VERSION "V6.0.0"

NS_ :

BS_:

BU_: OBD_Node CGW_PT POD BMS TCU APTC VCU MCU PRND EVCOM IBS_PT ADCU_PT

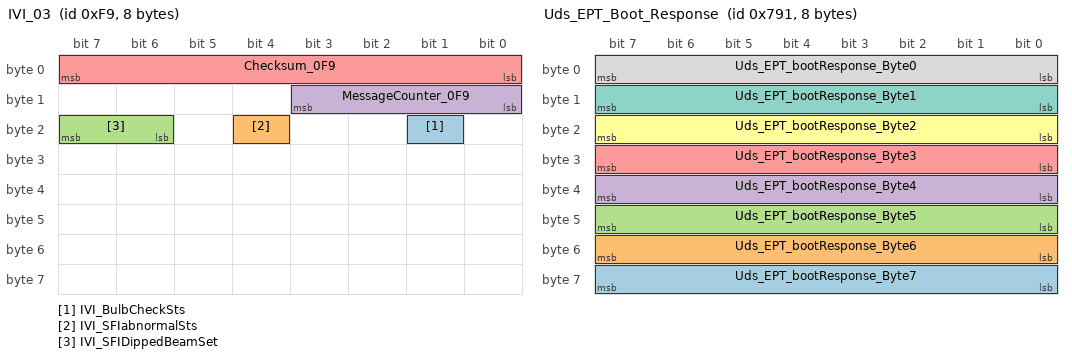
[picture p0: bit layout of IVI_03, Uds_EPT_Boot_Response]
BO_ 249 IVI_03: 8 CGW_PT
 SG_ IVI_BulbCheckSts : 17|1@0+ (1,0) [0|1] ""  VCU
 SG_ IVI_SFIabnormalSts : 20|1@0+ (1,0) [0|1] ""  VCU
 SG_ IVI_SFIDippedBeamSet : 23|2@0+ (1,0) [0|3] ""  VCU
 SG_ MessageCounter_0F9 : 11|4@0+ (1,0) [0|15] ""  VCU
 SG_ Checksum_0F9 : 7|8@0+ (1,0) [0|255] ""  VCU

BO_ 1937 Uds_EPT_Boot_Response: 8 VCU
 SG_ Uds_EPT_bootResponse_Byte7 : 56|8@1+ (1,0) [0|0] ""  CGW_PT
 SG_ Uds_EPT_bootResponse_Byte6 : 48|8@1+ (1,0) [0|0] ""  CGW_PT
 SG_ Uds_EPT_bootResponse_Byte5 : 40|8@1+ (1,0) [0|0] ""  CGW_PT
 SG_ Uds_EPT_bootResponse_Byte4 : 32|8@1+ (1,0) [0|0] ""  CGW_PT
 SG_ Uds_EPT_bootResponse_Byte3 : 24|8@1+ (1,0) [0|0] ""  CGW_PT
 SG_ Uds_EPT_bootResponse_Byte2 : 16|8@1+ (1,0) [0|0] ""  CGW_PT
 SG_ Uds_EPT_bootResponse_Byte1 : 8|8@1+ (1,0) [0|0] ""  CGW_PT
 SG_ Uds_EPT_bootResponse_Byte0 : 0|8@1+ (1,0) [0|0] ""  CGW_PT

BO_ 1809 Uds_EPT_Boot_Request: 8 CGW_PT
 SG_ UDS_EPT_BootCmd3 : 16|8@1+ (1,0) [0|0] ""  VCU
 SG_ UDS_EPT_BootCmd2 : 8|8@1+ (1,0) [0|0] ""  VCU
 SG_ UDS_EPT_BootCmd1 : 0|8@1+ (1,0) [0|0] ""  VCU

BO_ 151 ACU_info: 8 CGW_PT
 SG_ Checksum_097 : 7|8@0+ (1,0) [0|255] ""  MCU,BMS
 SG_ MessageCounter_097 : 11|4@0+ (1,0) [0|15] ""  MCU,BMS
 SG_ ACU_CrashOutputSts : 23|5@0+ (1,0) [0|31] ""  MCU,BMS
 SG_ ACU_CrashOutputStsValid : 16|1@0+ (1,0) [0|1] ""  MCU,BMS
 SG_ ACU_DriverSeatBeltSts : 31|1@0+ (1,0) [0|1] "" Vector__XXX
 SG_ ACU_DriverSeatBeltStsValid : 30|1@0+ (1,0) [0|1] "" Vector__XXX
 SG_ ACU_PassengerSeatBeltSts : 27|1@0+ (1,0) [0|1] "" Vector__XXX
 SG_ ACU_PassengerSeatBeltStsValid : 26|1@0+ (1,0) [0|1] "" Vector__XXX
 SG_ ACU_PassengerSts : 25|1@0+ (1,0) [0|1] "" Vector__XXX
 SG_ ACU_SecondLeftSeatBeltSts : 39|1@0+ (1,0) [0|1] "" Vector__XXX
 SG_ ACU_RLSeatBeltStatusValid : 38|1@0+ (1,0) [0|1] "" Vector__XXX
 SG_ ACU_SecondLeftSts : 37|1@0+ (1,0) [0|1] "" Vector__XXX
 SG_ ACU_SecondRightSeatBeltSts : 55|1@0+ (1,0) [0|1] "" Vector__XXX
 SG_ ACU_RRSeatBeltStatusValid : 54|1@0+ (1,0) [0|1] "" Vector__XXX
 SG_ ACU_SecondRightSts : 53|1@0+ (1,0) [0|1] "" Vector__XXX
 SG_ ACU_PassengerAirbagSts : 63|2@0+ (1,0) [0|3] "" Vector__XXX
 SG_ ACU_DriverWarningLampSts : 61|2@0+ (1,0) [0|2] "" Vector__XXX
 SG_ ACU_PassengerWarningLampSts : 59|2@0+ (1,0) [0|2] "" Vector__XXX
 SG_ ACU_WarningLampSts : 57|2@0+ (1,0) [0|2] "" Vector__XXX

BO_ 918 ADCU_temperature: 8 ADCU_PT
 SG_ ADCU_TemperatureSts : 23|2@0+ (1,0) [0|3] "" Vector__XXX

BO_ 613 APTC_TCU: 8 APTC
 SG_ APTC_HVPowerUpReq : 7|1@0+ (1,0) [0|1] ""  TCU,CGW_PT
 SG_ APTC_HeatingFaltStatus : 6|1@0+ (1,0) [0|1] ""  TCU,CGW_PT
 SG_ APTC_DriveFaltStatus : 5|1@0+ (1,0) [0|1] ""  TCU,CGW_PT
 SG_ APTC_LostCommuFaltStatus : 4|1@0+ (1,0) [0|1] ""  TCU,CGW_PT
 SG_ APTC_IGBTFaltStatus : 3|2@0+ (1,0) [0|3] ""  TCU,CGW_PT
 SG_ APTC_Core1TempSensorFaltStatus : 1|2@0+ (1,0) [0|3] ""  TCU,CGW_PT
 SG_ APTC_LeftCoreTemp : 15|8@0+ (1,-40) [-40|215] "degrees"  TCU,CGW_PT
 SG_ APTC_RightCoreTemp : 23|8@0+ (1,-40) [-40|215] "degrees"  TCU,CGW_PT
 SG_ APTC_PowerConsumption : 31|8@0+ (0.04,0) [0|10.2] "KW"  TCU,VCU,CGW_PT
 SG_ APTC_HVBusVoltage : 39|11@0+ (0.5,0) [0|1020] "V"  TCU,CGW_PT
 SG_ APTC_OverCurrentFault : 52|1@0+ (1,0) [0|1] ""  TCU,CGW_PT
 SG_ APTC_LowVoltageStatus : 51|2@0+ (1,0) [0|3] ""  TCU,CGW_PT
 SG_ APTC_HighVoltageStatus : 49|2@0+ (1,0) [0|3] ""  TCU,CGW_PT
 SG_ APTC_OverLoadStatus : 63|2@0+ (1,0) [0|3] ""  TCU,CGW_PT
 SG_ APTC_IGBTTempSensorStatus : 61|2@0+ (1,0) [0|3] ""  TCU,CGW_PT
 SG_ APTC_PCBTempSensorStatus : 59|2@0+ (1,0) [0|3] ""  TCU,CGW_PT
 SG_ APTC_Core2TempSensorFaltStatus : 57|2@0+ (1,0) [0|3] ""  TCU,CGW_PT

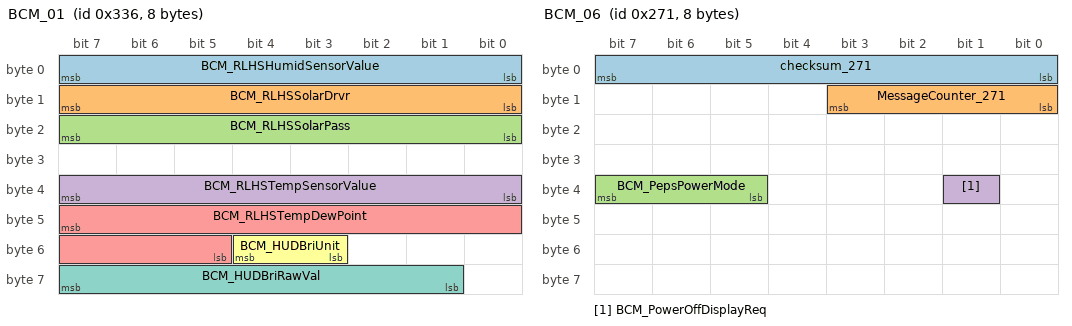
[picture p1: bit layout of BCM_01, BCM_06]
BO_ 822 BCM_01: 8 CGW_PT
 SG_ BCM_RLHSHumidSensorValue : 7|8@0+ (0.5,-0.5) [0|100] "percent"  TCU
 SG_ BCM_RLHSSolarDrvr : 15|8@0+ (4,0) [0|1000] "W/m^2"  TCU
 SG_ BCM_RLHSSolarPass : 23|8@0+ (4,0) [0|1000] "W/m^2"  TCU
 SG_ BCM_RLHSTempSensorValue : 39|8@0+ (0.5,-40) [-39.5|87] "celsius"  TCU
 SG_ BCM_RLHSTempDewPoint : 47|11@0+ (0.1,-39.6) [-39.5|60.4] "celsius"  TCU
 SG_ BCM_HUDBriUnit : 52|2@0+ (1,0) [0|3] "" Vector__XXX
 SG_ BCM_HUDBriRawVal : 63|7@0+ (1,0) [0|126] "" Vector__XXX

BO_ 826 BCM_05: 8 CGW_PT
 SG_ Checksum_33A : 7|8@0+ (1,0) [0|255] ""  VCU
 SG_ MessageCounter_33A : 11|4@0+ (1,0) [0|15] ""  VCU
 SG_ BCM_GearTimesSts : 15|3@0+ (1,0) [0|5] ""  VCU
 SG_ BCM_ChrgFlapLockSts : 12|1@0+ (1,0) [0|1] ""  VCU
 SG_ BCM_FRSeatBeltRemindReq : 17|2@0+ (1,0) [0|3] ""  VCU
 SG_ BCM_FLSeatBeltRemindReq : 19|2@0+ (1,0) [0|3] ""  VCU
 SG_ BCM_KeyNotInCarRemind : 20|1@0+ (1,0) [0|1] ""  VCU
 SG_ BCM_RRSeatBeltRemindReq : 29|2@0+ (1,0) [0|3] ""  VCU
 SG_ BCM_RLSeatBeltRemindReq : 31|2@0+ (1,0) [0|3] ""  VCU
 SG_ BCM_WiperServiceSts : 33|2@0+ (1,0) [0|1] ""  VCU
 SG_ BCM_AutoCloseWinFunSts : 36|1@0+ (1,0) [0|1] ""  VCU
 SG_ BCM_DomeLampBrightSts : 37|1@0+ (1,0) [0|1] ""  VCU
 SG_ BCM_PuddleLiReq : 39|2@0+ (1,0) [0|2] ""  VCU
 SG_ BCM_DomeLampAutoSts : 41|2@0+ (1,0) [0|2] ""  VCU
 SG_ BCM_FrontWiperModeSts : 44|3@0+ (1,0) [0|5] ""  VCU
 SG_ BCM_WiperWorkingSts : 47|3@0+ (1,0) [0|2] ""  VCU
 SG_ BCM_WelLightshowOnOffSts : 51|2@0+ (1,0) [0|2] ""  VCU

BO_ 625 BCM_06: 8 CGW_PT
 SG_ checksum_271 : 7|8@0+ (1,0) [0|255] ""  VCU
 SG_ MessageCounter_271 : 11|4@0+ (1,0) [0|15] ""  VCU
 SG_ BCM_PepsPowerMode : 39|3@0+ (1,0) [0|7] ""  VCU
 SG_ BCM_PowerOffDisplayReq : 33|1@0+ (1,0) [0|1] ""  VCU

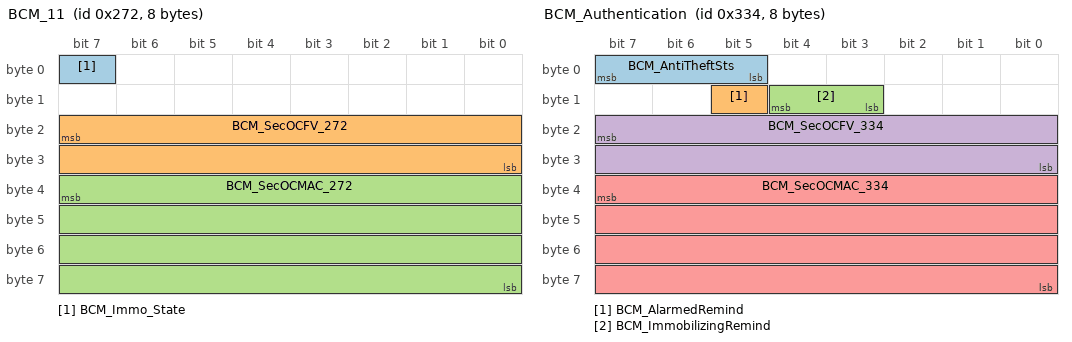
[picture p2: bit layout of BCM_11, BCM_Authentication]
BO_ 626 BCM_11: 8 CGW_PT
 SG_ BCM_Immo_State : 7|1@0+ (1,0) [0|1] ""  VCU
 SG_ BCM_SecOCFV_272 : 23|16@0+ (1,0) [0|65535] ""  VCU
 SG_ BCM_SecOCMAC_272 : 39|32@0+ (1,0) [0|4294967295] ""  VCU

BO_ 820 BCM_Authentication: 8 CGW_PT
 SG_ BCM_AntiTheftSts : 7|3@0+ (1,0) [0|3] ""  VCU
 SG_ BCM_AlarmedRemind : 13|1@0+ (1,0) [0|1] "" Vector__XXX
 SG_ BCM_ImmobilizingRemind : 12|2@0+ (1,0) [0|3] "" Vector__XXX
 SG_ BCM_SecOCFV_334 : 23|16@0+ (1,0) [0|65535] ""  VCU
 SG_ BCM_SecOCMAC_334 : 39|32@0+ (1,0) [0|4294967295] ""  VCU

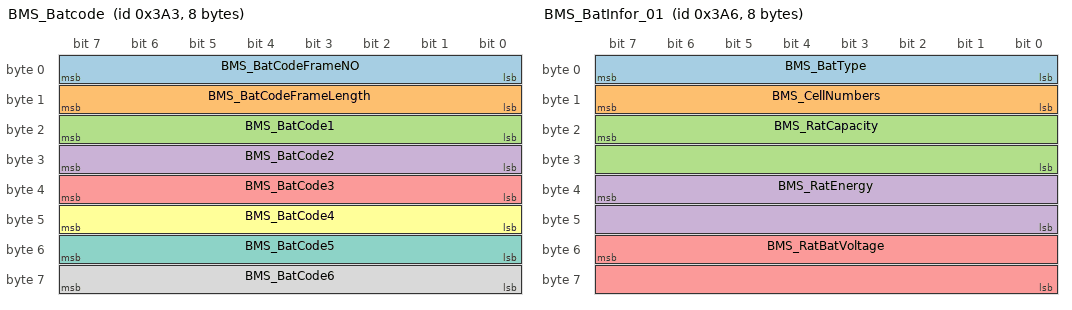
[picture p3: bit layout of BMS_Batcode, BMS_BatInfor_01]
BO_ 931 BMS_Batcode: 8 BMS
 SG_ BMS_BatCodeFrameNO : 7|8@0+ (1,0) [0|255] "" Vector__XXX
 SG_ BMS_BatCodeFrameLength : 15|8@0+ (1,0) [0|255] "" Vector__XXX
 SG_ BMS_BatCode1 : 23|8@0+ (1,0) [0|255] "" Vector__XXX
 SG_ BMS_BatCode2 : 31|8@0+ (1,0) [0|255] "" Vector__XXX
 SG_ BMS_BatCode3 : 39|8@0+ (1,0) [0|255] "" Vector__XXX
 SG_ BMS_BatCode4 : 47|8@0+ (1,0) [0|255] "" Vector__XXX
 SG_ BMS_BatCode5 : 55|8@0+ (1,0) [0|255] "" Vector__XXX
 SG_ BMS_BatCode6 : 63|8@0+ (1,0) [0|255] "" Vector__XXX

BO_ 934 BMS_BatInfor_01: 8 BMS
 SG_ BMS_BatType : 7|8@0+ (1,0) [0|255] ""  VCU,CGW_PT
 SG_ BMS_CellNumbers : 15|8@0+ (1,0) [0|255] ""  VCU,CGW_PT
 SG_ BMS_RatCapacity : 23|16@0+ (0.1,0) [0|6553.5] "Ah"  VCU,CGW_PT
 SG_ BMS_RatEnergy : 39|16@0+ (0.1,0) [0|6553.5] "KWH"  VCU,CGW_PT
 SG_ BMS_RatBatVoltage : 55|16@0+ (0.1,0) [0|6553.5] "V"  VCU,CGW_PT

BO_ 935 BMS_BatInfor_02: 8 BMS
 SG_ BMS_BatSupName : 7|64@0+ (1,0) [0|4294967295] ""  VCU

BO_ 938 BMS_BatInfor_03: 8 BMS
 SG_ BMS_RemainCapacity : 23|16@0+ (0.1,0) [0|6553.5] "Ah"  VCU

BO_ 993 BMS_Cellinfo: 8 BMS
 SG_ BMS_Cellinfo : 7|64@0+ (0.01,0) [0|655.35] "" Vector__XXX

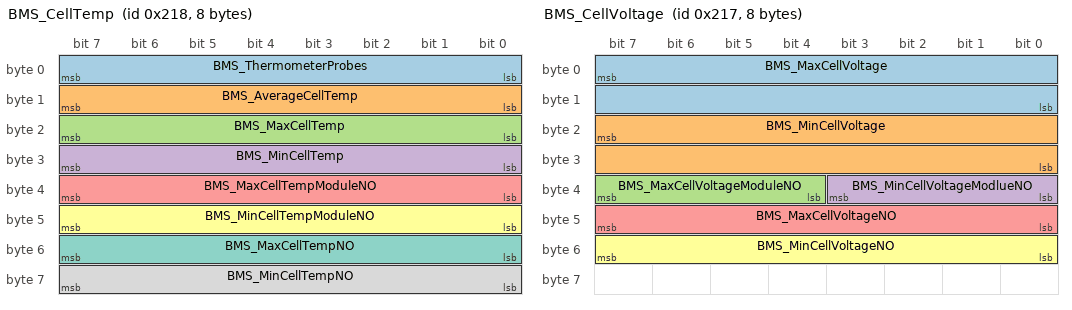
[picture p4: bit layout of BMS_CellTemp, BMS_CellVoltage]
BO_ 536 BMS_CellTemp: 8 BMS
 SG_ BMS_ThermometerProbes : 7|8@0+ (1,0) [0|255] ""  CGW_PT
 SG_ BMS_AverageCellTemp : 15|8@0+ (1,-40) [-40|215] "celsius"  TCU,VCU,CGW_PT
 SG_ BMS_MaxCellTemp : 23|8@0+ (1,-40) [-40|215] "celsius"  TCU,VCU,CGW_PT
 SG_ BMS_MinCellTemp : 31|8@0+ (1,-40) [-40|215] "celsius"  TCU,VCU,CGW_PT
 SG_ BMS_MaxCellTempModuleNO : 39|8@0+ (1,0) [0|255] ""  CGW_PT
 SG_ BMS_MinCellTempModuleNO : 47|8@0+ (1,0) [0|255] ""  VCU,CGW_PT
 SG_ BMS_MaxCellTempNO : 55|8@0+ (1,0) [0|255] ""  VCU,CGW_PT
 SG_ BMS_MinCellTempNO : 63|8@0+ (1,0) [0|255] ""  VCU,CGW_PT

BO_ 535 BMS_CellVoltage: 8 BMS
 SG_ BMS_MaxCellVoltage : 7|16@0+ (0.001,0) [0|65.535] "V"  VCU,CGW_PT
 SG_ BMS_MinCellVoltage : 23|16@0+ (0.001,0) [0|65.535] "V"  VCU,CGW_PT
 SG_ BMS_MaxCellVoltageModuleNO : 39|4@0+ (1,0) [0|15] ""  VCU,CGW_PT
 SG_ BMS_MinCellVoltageModlueNO : 35|4@0+ (1,0) [0|15] ""  CGW_PT
 SG_ BMS_MaxCellVoltageNO : 47|8@0+ (1,0) [0|255] ""  VCU,CGW_PT
 SG_ BMS_MinCellVoltageNO : 55|8@0+ (1,0) [0|255] ""  CGW_PT

BO_ 530 BMS_Charge_01: 8 BMS
 SG_ BMS_RemChagTime : 7|16@0+ (1,0) [0|3600] "min"  VCU,CGW_PT
 SG_ BMS_MaxChagVoltage : 23|16@0+ (0.1,0) [0|6553.5] "V"  VCU,CGW_PT,POD
 SG_ BMS_AllowChagCurrent : 39|16@0+ (0.1,-1000) [-1000|1000] "A"  VCU,CGW_PT

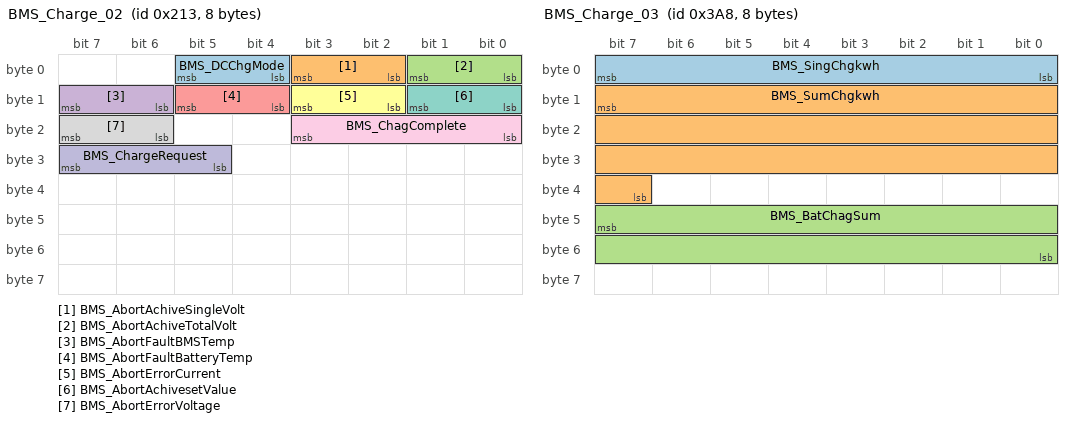
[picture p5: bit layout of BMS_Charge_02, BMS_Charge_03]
BO_ 531 BMS_Charge_02: 8 BMS
 SG_ BMS_DCChgMode : 5|2@0+ (1,0) [0|2] ""  VCU,CGW_PT
 SG_ BMS_AbortAchiveSingleVolt : 3|2@0+ (1,0) [0|2] ""  VCU,CGW_PT
 SG_ BMS_AbortAchiveTotalVolt : 1|2@0+ (1,0) [0|2] ""  VCU,CGW_PT
 SG_ BMS_AbortFaultBMSTemp : 15|2@0+ (1,0) [0|2] ""  VCU,CGW_PT
 SG_ BMS_AbortFaultBatteryTemp : 13|2@0+ (1,0) [0|2] ""  VCU,CGW_PT
 SG_ BMS_AbortErrorCurrent : 11|2@0+ (1,0) [0|2] ""  VCU,CGW_PT
 SG_ BMS_AbortAchivesetValue : 9|2@0+ (1,0) [0|2] ""  VCU,CGW_PT
 SG_ BMS_AbortErrorVoltage : 23|2@0+ (1,0) [0|2] ""  VCU,CGW_PT
 SG_ BMS_ChagComplete : 19|4@0+ (1,0) [0|3] ""  VCU,CGW_PT,POD
 SG_ BMS_ChargeRequest : 31|3@0+ (1,0) [0|4] ""  VCU,CGW_PT,POD

BO_ 936 BMS_Charge_03: 8 BMS
 SG_ BMS_SingChgkwh : 7|8@0+ (1,0) [0|255] "KWH"  VCU
 SG_ BMS_SumChgkwh : 15|25@0+ (1,0) [0|16777216] "KWH"  VCU
 SG_ BMS_BatChagSum : 47|16@0+ (1,0) [0|3000] ""  VCU

BO_ 937 BMS_Charge_04: 8 BMS
 SG_ BMS_SumDisChgkwh : 7|25@0+ (1,0) [0|16777216] "KWH" Vector__XXX

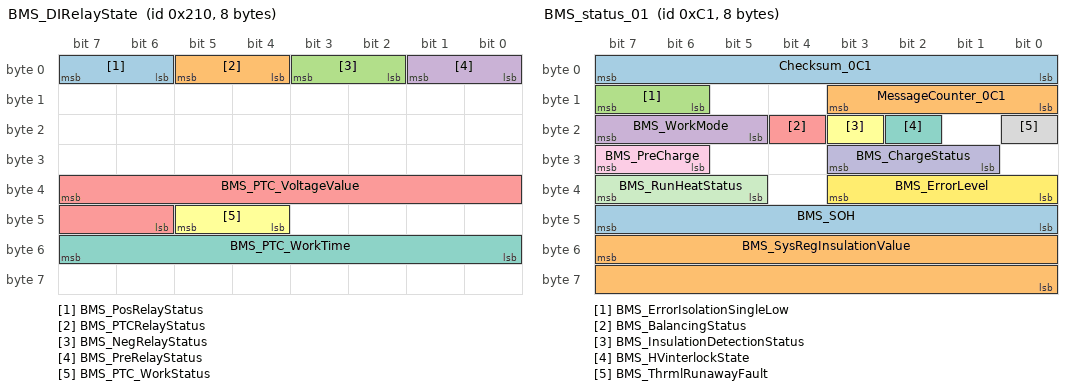
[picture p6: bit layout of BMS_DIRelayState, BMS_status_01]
BO_ 528 BMS_DIRelayState: 8 BMS
 SG_ BMS_PosRelayStatus : 7|2@0+ (1,0) [0|3] ""  VCU,CGW_PT
 SG_ BMS_PTCRelayStatus : 5|2@0+ (1,0) [0|3] ""  VCU,CGW_PT
 SG_ BMS_NegRelayStatus : 3|2@0+ (1,0) [0|3] ""  VCU,CGW_PT
 SG_ BMS_PreRelayStatus : 1|2@0+ (1,0) [0|3] ""  VCU,CGW_PT
 SG_ BMS_PTC_VoltageValue : 39|10@0+ (1,0) [0|1023] "V"  TCU,VCU,CGW_PT
 SG_ BMS_PTC_WorkStatus : 45|2@0+ (1,0) [0|2] ""  CGW_PT
 SG_ BMS_PTC_WorkTime : 55|8@0+ (1,0) [0|255] "min"  CGW_PT

BO_ 772 BMS_ErrorInfo: 8 BMS
 SG_ BMS_ErrorCellOverVolt : 7|2@0+ (1,0) [0|3] ""  VCU,CGW_PT
 SG_ BMS_ErrorCellUnderVolt : 5|2@0+ (1,0) [0|3] ""  VCU,CGW_PT
 SG_ BMS_ErrorCellHighTemp : 3|2@0+ (1,0) [0|3] ""  VCU,CGW_PT
 SG_ BMS_ErrorCellLowTemp : 1|2@0+ (1,0) [0|3] ""  VCU,CGW_PT
 SG_ BMS_ErrorBattOverVolt : 15|2@0+ (1,0) [0|3] ""  CGW_PT
 SG_ BMS_ErrorBattUnderVolt : 13|2@0+ (1,0) [0|3] ""  CGW_PT
 SG_ BMS_ErrorChaCurrentOver : 11|2@0+ (1,0) [0|3] ""  VCU,CGW_PT
 SG_ BMS_ErrorDisChaCurrentOver : 9|2@0+ (1,0) [0|3] ""  CGW_PT
 SG_ BMS_ErrorBSUOffline : 23|1@0+ (1,0) [0|1] ""  CGW_PT
 SG_ BMS_ErrorLeakCurrent : 22|2@0+ (1,0) [0|3] ""  CGW_PT
 SG_ BMS_ErrorCellVoltDiff : 20|2@0+ (1,0) [0|3] ""  CGW_PT
 SG_ BMS_ErrorCellTempDiff : 18|2@0+ (1,0) [0|3] ""  CGW_PT
 SG_ BMS_ErrorBatVolt : 31|2@0+ (1,0) [0|3] ""  CGW_PT
 SG_ BMS_ErrorHallOffline : 29|1@0+ (1,0) [0|1] ""  CGW_PT
 SG_ BMS_ErrorCellVoltOffline : 28|1@0+ (1,0) [0|1] ""  CGW_PT
 SG_ BMS_ErrorCellTempOffline : 27|1@0+ (1,0) [0|1] ""  CGW_PT
 SG_ BMS_ErrorPreChaFailed : 26|1@0+ (1,0) [0|1] ""  VCU,CGW_PT
 SG_ BMS_ErrorRelay : 25|1@0+ (1,0) [0|1] ""  VCU,CGW_PT
 SG_ BMS_ErrorBSUBalance : 24|1@0+ (1,0) [0|1] ""  CGW_PT
 SG_ BMS_ErrorLowSoc : 37|2@0+ (1,0) [0|3] ""  VCU,CGW_PT
 SG_ BMS_ErrorHighSoc : 35|1@0+ (1,0) [0|1] ""  VCU,CGW_PT
 SG_ BMS_ErrorSoCJump_RM : 34|1@0+ (1,0) [0|1] ""  CGW_PT
 SG_ BMS_ErrorHVIL : 33|1@0+ (1,0) [0|1] ""  CGW_PT
 SG_ BMS_ErrorEmergencyOffCrash : 32|1@0+ (1,0) [0|1] ""  MCU,CGW_PT
 SG_ BMS_ErrorSystemsMatch : 47|1@0+ (1,0) [0|1] ""  CGW_PT
 SG_ BMS_ErrorSmoke : 46|1@0+ (1,0) [0|1] ""  CGW_PT
 SG_ BMS_ErrorLeakDet : 45|1@0+ (1,0) [0|1] ""  CGW_PT
 SG_ BMS_ThermalRunawayFault : 43|1@0+ (1,0) [0|1] ""  VCU,CGW_PT
 SG_ BMS_DTC : 55|8@0+ (1,0) [0|255] ""  CGW_PT

BO_ 933 BMS_PRO: 8 BMS
 SG_ BMS_BatProDatYear : 7|8@0+ (1,0) [0|1] ""  VCU,CGW_PT
 SG_ BMS_BatProDatMonth : 15|8@0+ (1,0) [0|1] ""  VCU,CGW_PT
 SG_ BMS_BatProDatDay : 23|8@0+ (1,0) [0|1] ""  VCU,CGW_PT

BO_ 992 BMS_SGW_01: 8 BMS
 SG_ BMS_FeedEnergySts : 7|17@0+ (0.1,0) [0|9999] ""  CGW_PT
 SG_ BMS_DirveDiscSts : 31|17@0+ (0.1,0) [0|9999] ""  CGW_PT

BO_ 193 BMS_status_01: 8 BMS
 SG_ Checksum_0C1 : 7|8@0+ (1,0) [0|255] ""  VCU,MCU,CGW_PT
 SG_ MessageCounter_0C1 : 11|4@0+ (1,0) [0|15] ""  VCU,MCU,CGW_PT
 SG_ BMS_ErrorIsolationSingleLow : 15|2@0+ (1,0) [0|3] ""  VCU,CGW_PT
 SG_ BMS_WorkMode : 23|3@0+ (1,0) [0|7] ""  VCU,MCU,CGW_PT
 SG_ BMS_BalancingStatus : 20|1@0+ (1,0) [0|1] ""  VCU,CGW_PT
 SG_ BMS_InsulationDetectionStatus : 19|1@0+ (1,0) [0|1] ""  VCU,CGW_PT
 SG_ BMS_HVinterlockState : 18|1@0+ (1,0) [0|1] ""  VCU,CGW_PT
 SG_ BMS_ThrmlRunawayFault : 16|1@0+ (1,0) [0|1] ""  VCU,CGW_PT
 SG_ BMS_PreCharge : 31|2@0+ (1,0) [0|3] ""  VCU,CGW_PT
 SG_ BMS_ChargeStatus : 27|3@0+ (1,0) [0|7] ""  VCU,CGW_PT
 SG_ BMS_RunHeatStatus : 39|3@0+ (1,0) [0|4] ""  VCU,CGW_PT
 SG_ BMS_ErrorLevel : 35|4@0+ (1,0) [0|4] ""  VCU,CGW_PT
 SG_ BMS_SOH : 47|8@0+ (0.5,0) [0|100] "percent"  VCU,CGW_PT
 SG_ BMS_SysRegInsulationValue : 55|16@0+ (1,0) [0|60000] "kOhm"  VCU,CGW_PT

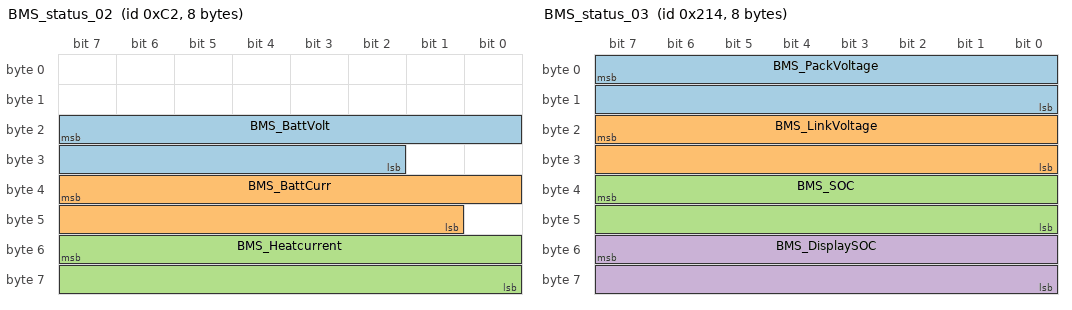
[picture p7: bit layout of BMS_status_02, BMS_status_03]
BO_ 194 BMS_status_02: 8 BMS
 SG_ BMS_BattVolt : 23|14@0+ (0.1,0) [0|1000] "V"  VCU,MCU,CGW_PT
 SG_ BMS_BattCurr : 39|15@0+ (0.1,-1024) [-1024|1023] "A"  VCU,CGW_PT
 SG_ BMS_Heatcurrent : 55|16@0+ (0.1,-1024) [-1024|1023] "A"  TCU,VCU,CGW_PT

BO_ 532 BMS_status_03: 8 BMS
 SG_ BMS_PackVoltage : 7|16@0+ (0.1,0) [0|6553.5] "V"  VCU,CGW_PT
 SG_ BMS_LinkVoltage : 23|16@0+ (0.1,0) [0|6553.5] "V"  VCU,CGW_PT
 SG_ BMS_SOC : 39|16@0+ (0.01,0) [0|100] "percent"  CGW_PT
 SG_ BMS_DisplaySOC : 55|16@0+ (0.01,0) [0|100] "percent"  TCU,APTC,VCU,MCU,PRND,EVCOM,ADCU_PT,CGW_PT,POD

BO_ 533 BMS_status_04: 8 BMS
 SG_ BMS_FeedbackCurr : 7|16@0- (0.1,-1000) [-1000|1000] "A"  VCU
 SG_ BMS_DisChgCurr : 23|16@0- (0.1,-1000) [-1000|1000] "A"  VCU

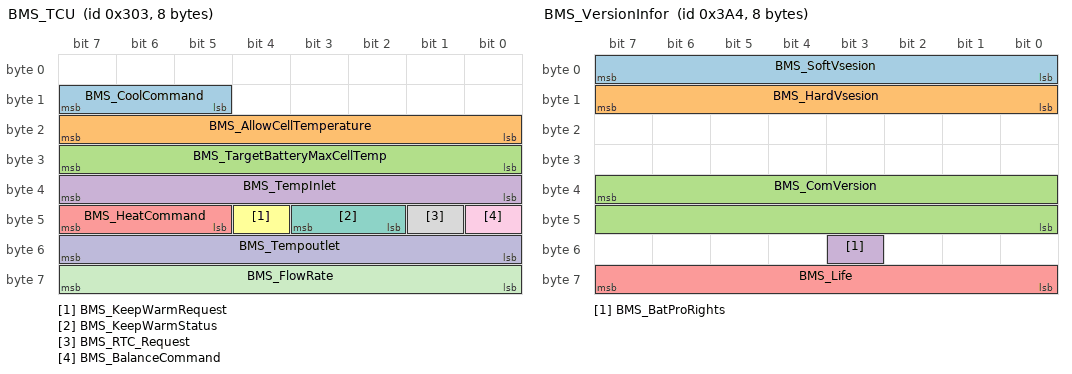
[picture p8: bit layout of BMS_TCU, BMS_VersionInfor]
BO_ 771 BMS_TCU: 8 BMS
 SG_ BMS_CoolCommand : 15|3@0+ (1,0) [0|7] ""  TCU,CGW_PT
 SG_ BMS_AllowCellTemperature : 23|8@0+ (1,-40) [-40|215] "celsius"  VCU,CGW_PT
 SG_ BMS_TargetBatteryMaxCellTemp : 31|8@0+ (1,-40) [-40|215] "celsius"  TCU,CGW_PT
 SG_ BMS_TempInlet : 39|8@0+ (1,-40) [-40|215] "celsius"  TCU,CGW_PT
 SG_ BMS_HeatCommand : 47|3@0+ (1,0) [0|7] ""  TCU,CGW_PT
 SG_ BMS_KeepWarmRequest : 44|1@0+ (1,0) [0|1] ""  VCU,CGW_PT,POD
 SG_ BMS_KeepWarmStatus : 43|2@0+ (1,0) [0|2] ""  VCU,CGW_PT
 SG_ BMS_RTC_Request : 41|1@0+ (1,0) [0|1] ""  VCU,CGW_PT
 SG_ BMS_BalanceCommand : 40|1@0+ (1,0) [0|1] ""  TCU,CGW_PT
 SG_ BMS_Tempoutlet : 55|8@0+ (1,-40) [-40|215] "celsius"  TCU,CGW_PT
 SG_ BMS_FlowRate : 63|8@0+ (1,0) [0|255] "L/min"  TCU,CGW_PT

BO_ 932 BMS_VersionInfor: 8 BMS
 SG_ BMS_SoftVsesion : 7|8@0+ (1,0) [0|1] ""  CGW_PT
 SG_ BMS_HardVsesion : 15|8@0+ (1,0) [0|1] ""  CGW_PT
 SG_ BMS_ComVersion : 39|16@0+ (1,0) [0|65535] ""  VCU,CGW_PT
 SG_ BMS_BatProRights : 51|1@0+ (1,0) [0|1] ""  VCU,CGW_PT
 SG_ BMS_Life : 63|8@0+ (1,0) [0|255] ""  CGW_PT

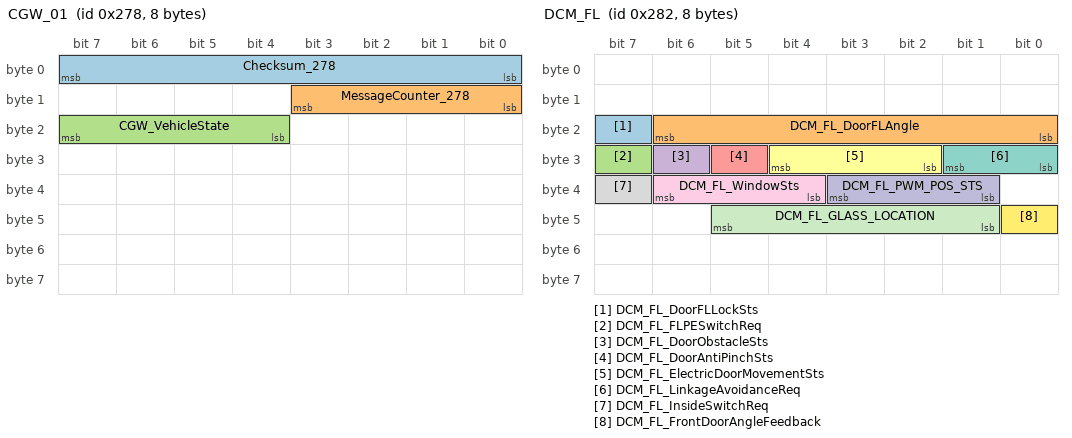
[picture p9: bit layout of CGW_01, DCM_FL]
BO_ 632 CGW_01: 8 CGW_PT
 SG_ Checksum_278 : 7|8@0+ (1,0) [0|255] ""  VCU,MCU,PRND,ADCU_PT,BMS
 SG_ MessageCounter_278 : 11|4@0+ (1,0) [0|15] ""  VCU,MCU,PRND,ADCU_PT,BMS
 SG_ CGW_VehicleState : 23|4@0+ (1,0) [0|8] ""  TCU,APTC,VCU,MCU,PRND,EVCOM,ADCU_PT,POD,BMS

BO_ 642 DCM_FL: 8 CGW_PT
 SG_ DCM_FL_DoorFLLockSts : 23|1@0+ (1,0) [0|1] "" Vector__XXX
 SG_ DCM_FL_DoorFLAngle : 22|7@0+ (1,0) [0|100] "degrees" Vector__XXX
 SG_ DCM_FL_FLPESwitchReq : 31|1@0+ (1,0) [0|1] "" Vector__XXX
 SG_ DCM_FL_DoorObstacleSts : 30|1@0+ (1,0) [0|1] "" Vector__XXX
 SG_ DCM_FL_DoorAntiPinchSts : 29|1@0+ (1,0) [0|1] "" Vector__XXX
 SG_ DCM_FL_ElectricDoorMovementSts : 28|3@0+ (1,0) [0|7] "" Vector__XXX
 SG_ DCM_FL_LinkageAvoidanceReq : 25|2@0+ (1,0) [0|3] "" Vector__XXX
 SG_ DCM_FL_InsideSwitchReq : 39|1@0+ (1,0) [0|1] "" Vector__XXX
 SG_ DCM_FL_WindowSts : 38|3@0+ (1,0) [0|5] "" Vector__XXX
 SG_ DCM_FL_PWM_POS_STS : 35|3@0+ (1,0) [0|4] "" Vector__XXX
 SG_ DCM_FL_GLASS_LOCATION : 45|5@0+ (1,0) [0|20] ""  TCU
 SG_ DCM_FL_FrontDoorAngleFeedback : 40|1@0+ (1,0) [0|1] "" Vector__XXX

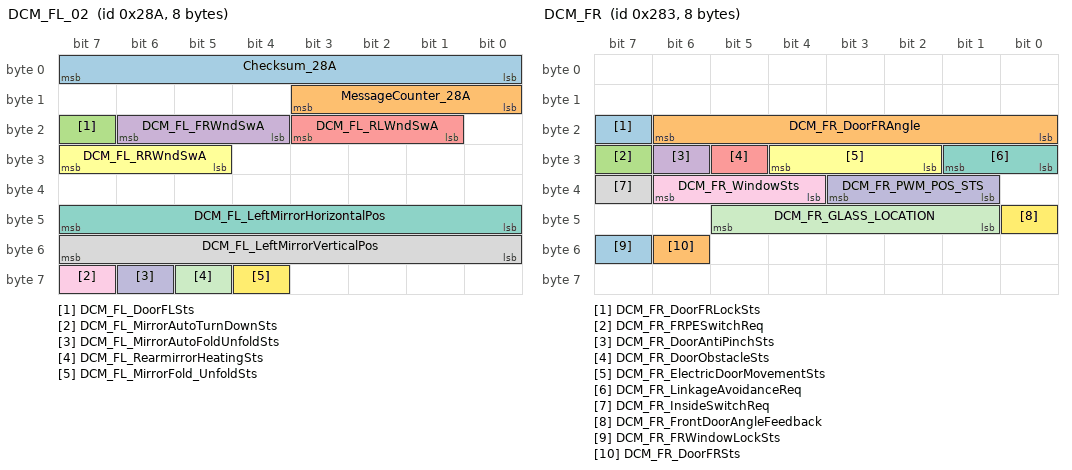
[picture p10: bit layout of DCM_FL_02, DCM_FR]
BO_ 650 DCM_FL_02: 8 CGW_PT
 SG_ Checksum_28A : 7|8@0+ (1,0) [0|255] ""  VCU
 SG_ MessageCounter_28A : 11|4@0+ (1,0) [0|15] ""  VCU
 SG_ DCM_FL_DoorFLSts : 23|1@0+ (1,0) [0|1] ""  TCU,VCU
 SG_ DCM_FL_FRWndSwA : 22|3@0+ (1,0) [0|5] ""  VCU
 SG_ DCM_FL_RLWndSwA : 19|3@0+ (1,0) [0|5] ""  VCU
 SG_ DCM_FL_RRWndSwA : 31|3@0+ (1,0) [0|5] ""  VCU
 SG_ DCM_FL_LeftMirrorHorizontalPos : 47|8@0+ (1,0) [0|100] "percent"  VCU
 SG_ DCM_FL_LeftMirrorVerticalPos : 55|8@0+ (1,0) [0|100] "percent"  VCU
 SG_ DCM_FL_MirrorAutoTurnDownSts : 63|1@0+ (1,0) [0|1] ""  VCU
 SG_ DCM_FL_MirrorAutoFoldUnfoldSts : 62|1@0+ (1,0) [0|1] ""  VCU
 SG_ DCM_FL_RearmirrorHeatingSts : 61|1@0+ (1,0) [0|1] ""  VCU
 SG_ DCM_FL_MirrorFold_UnfoldSts : 60|1@0+ (1,0) [0|1] ""  VCU

BO_ 643 DCM_FR: 8 CGW_PT
 SG_ DCM_FR_DoorFRLockSts : 23|1@0+ (1,0) [0|1] "" Vector__XXX
 SG_ DCM_FR_DoorFRAngle : 22|7@0+ (1,0) [0|100] "degrees" Vector__XXX
 SG_ DCM_FR_FRPESwitchReq : 31|1@0+ (1,0) [0|1] "" Vector__XXX
 SG_ DCM_FR_DoorAntiPinchSts : 30|1@0+ (1,0) [0|1] "" Vector__XXX
 SG_ DCM_FR_DoorObstacleSts : 29|1@0+ (1,0) [0|1] "" Vector__XXX
 SG_ DCM_FR_ElectricDoorMovementSts : 28|3@0+ (1,0) [0|7] "" Vector__XXX
 SG_ DCM_FR_LinkageAvoidanceReq : 25|2@0+ (1,0) [0|3] "" Vector__XXX
 SG_ DCM_FR_InsideSwitchReq : 39|1@0+ (1,0) [0|1] "" Vector__XXX
 SG_ DCM_FR_WindowSts : 38|3@0+ (1,0) [0|5] "" Vector__XXX
 SG_ DCM_FR_PWM_POS_STS : 35|3@0+ (1,0) [0|4] "" Vector__XXX
 SG_ DCM_FR_GLASS_LOCATION : 45|5@0+ (1,0) [0|20] ""  TCU
 SG_ DCM_FR_FrontDoorAngleFeedback : 40|1@0+ (1,0) [0|1] "" Vector__XXX
 SG_ DCM_FR_FRWindowLockSts : 55|1@0+ (1,0) [0|1] "" Vector__XXX
 SG_ DCM_FR_DoorFRSts : 54|1@0+ (1,0) [0|1] ""  TCU,VCU

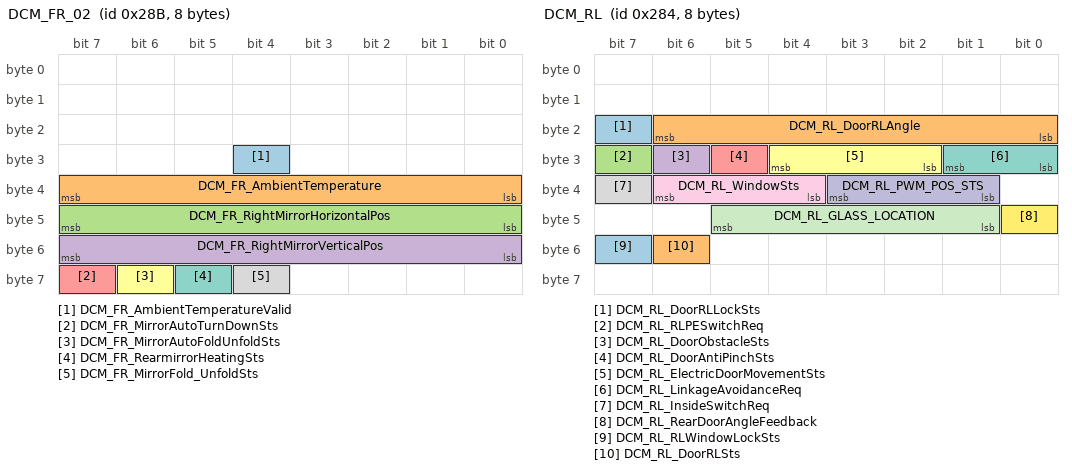
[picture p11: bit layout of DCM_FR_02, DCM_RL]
BO_ 651 DCM_FR_02: 8 CGW_PT
 SG_ DCM_FR_AmbientTemperatureValid : 28|1@0+ (1,0) [0|1] ""  VCU,TCU,BMS
 SG_ DCM_FR_AmbientTemperature : 39|8@0+ (1,-50) [-50|205] "celsius"  VCU,TCU,BMS
 SG_ DCM_FR_RightMirrorHorizontalPos : 47|8@0+ (1,0) [0|100] "percent" Vector__XXX
 SG_ DCM_FR_RightMirrorVerticalPos : 55|8@0+ (1,0) [0|100] "percent" Vector__XXX
 SG_ DCM_FR_MirrorAutoTurnDownSts : 63|1@0+ (1,0) [0|1] "" Vector__XXX
 SG_ DCM_FR_MirrorAutoFoldUnfoldSts : 62|1@0+ (1,0) [0|1] "" Vector__XXX
 SG_ DCM_FR_RearmirrorHeatingSts : 61|1@0+ (1,0) [0|1] "" Vector__XXX
 SG_ DCM_FR_MirrorFold_UnfoldSts : 60|1@0+ (1,0) [0|1] "" Vector__XXX

BO_ 644 DCM_RL: 8 CGW_PT
 SG_ DCM_RL_DoorRLLockSts : 23|1@0+ (1,0) [0|1] "" Vector__XXX
 SG_ DCM_RL_DoorRLAngle : 22|7@0+ (1,0) [0|100] "degrees" Vector__XXX
 SG_ DCM_RL_RLPESwitchReq : 31|1@0+ (1,0) [0|1] "" Vector__XXX
 SG_ DCM_RL_DoorObstacleSts : 30|1@0+ (1,0) [0|1] "" Vector__XXX
 SG_ DCM_RL_DoorAntiPinchSts : 29|1@0+ (1,0) [0|1] "" Vector__XXX
 SG_ DCM_RL_ElectricDoorMovementSts : 28|3@0+ (1,0) [0|7] "" Vector__XXX
 SG_ DCM_RL_LinkageAvoidanceReq : 25|2@0+ (1,0) [0|3] "" Vector__XXX
 SG_ DCM_RL_InsideSwitchReq : 39|1@0+ (1,0) [0|1] "" Vector__XXX
 SG_ DCM_RL_WindowSts : 38|3@0+ (1,0) [0|5] "" Vector__XXX
 SG_ DCM_RL_PWM_POS_STS : 35|3@0+ (1,0) [0|4] "" Vector__XXX
 SG_ DCM_RL_GLASS_LOCATION : 45|5@0+ (1,0) [0|20] ""  TCU
 SG_ DCM_RL_RearDoorAngleFeedback : 40|1@0+ (1,0) [0|1] "" Vector__XXX
 SG_ DCM_RL_RLWindowLockSts : 55|1@0+ (1,0) [0|1] "" Vector__XXX
 SG_ DCM_RL_DoorRLSts : 54|1@0+ (1,0) [0|1] ""  TCU,VCU

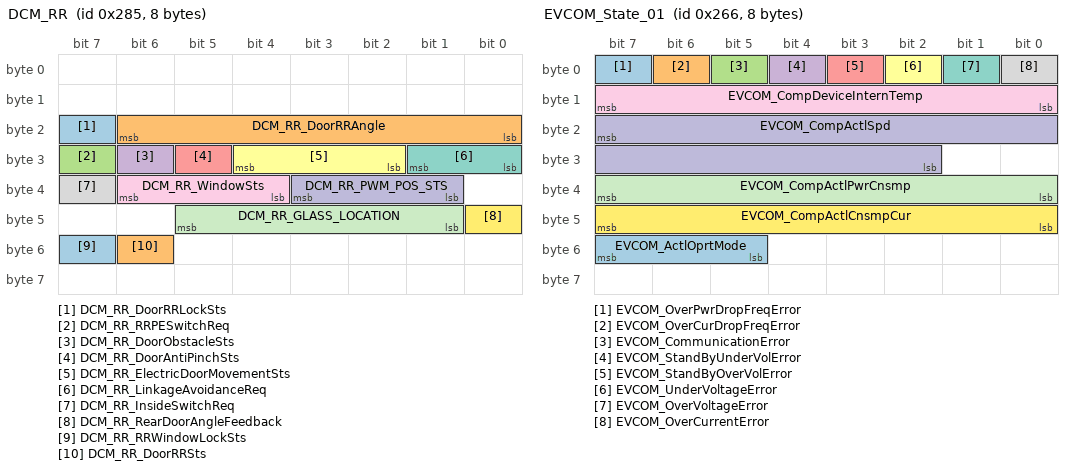
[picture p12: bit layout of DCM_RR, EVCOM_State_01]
BO_ 645 DCM_RR: 8 CGW_PT
 SG_ DCM_RR_DoorRRLockSts : 23|1@0+ (1,0) [0|1] "" Vector__XXX
 SG_ DCM_RR_DoorRRAngle : 22|7@0+ (1,0) [0|100] "degrees" Vector__XXX
 SG_ DCM_RR_RRPESwitchReq : 31|1@0+ (1,0) [0|1] "" Vector__XXX
 SG_ DCM_RR_DoorObstacleSts : 30|1@0+ (1,0) [0|1] "" Vector__XXX
 SG_ DCM_RR_DoorAntiPinchSts : 29|1@0+ (1,0) [0|1] "" Vector__XXX
 SG_ DCM_RR_ElectricDoorMovementSts : 28|3@0+ (1,0) [0|7] "" Vector__XXX
 SG_ DCM_RR_LinkageAvoidanceReq : 25|2@0+ (1,0) [0|3] "" Vector__XXX
 SG_ DCM_RR_InsideSwitchReq : 39|1@0+ (1,0) [0|1] "" Vector__XXX
 SG_ DCM_RR_WindowSts : 38|3@0+ (1,0) [0|5] "" Vector__XXX
 SG_ DCM_RR_PWM_POS_STS : 35|3@0+ (1,0) [0|4] "" Vector__XXX
 SG_ DCM_RR_GLASS_LOCATION : 45|5@0+ (1,0) [0|20] ""  TCU
 SG_ DCM_RR_RearDoorAngleFeedback : 40|1@0+ (1,0) [0|1] "" Vector__XXX
 SG_ DCM_RR_RRWindowLockSts : 55|1@0+ (1,0) [0|1] "" Vector__XXX
 SG_ DCM_RR_DoorRRSts : 54|1@0+ (1,0) [0|1] ""  TCU,VCU

BO_ 614 EVCOM_State_01: 8 EVCOM
 SG_ EVCOM_OverPwrDropFreqError : 7|1@0+ (1,0) [0|1] ""  TCU,CGW_PT
 SG_ EVCOM_OverCurDropFreqError : 6|1@0+ (1,0) [0|1] ""  TCU,CGW_PT
 SG_ EVCOM_CommunicationError : 5|1@0+ (1,0) [0|1] ""  TCU,CGW_PT
 SG_ EVCOM_StandByUnderVolError : 4|1@0+ (1,0) [0|1] ""  TCU,CGW_PT
 SG_ EVCOM_StandByOverVolError : 3|1@0+ (1,0) [0|1] ""  TCU,CGW_PT
 SG_ EVCOM_UnderVoltageError : 2|1@0+ (1,0) [0|1] ""  TCU,CGW_PT
 SG_ EVCOM_OverVoltageError : 1|1@0+ (1,0) [0|1] ""  TCU,CGW_PT
 SG_ EVCOM_OverCurrentError : 0|1@0+ (1,0) [0|1] ""  TCU,CGW_PT
 SG_ EVCOM_CompDeviceInternTemp : 15|8@0+ (1,-40) [-40|215] "celsius"  TCU,CGW_PT
 SG_ EVCOM_CompActlSpd : 23|14@0+ (1,0) [0|9200] "rpm"  TCU,CGW_PT
 SG_ EVCOM_CompActlPwrCnsmp : 39|8@0+ (0.04,0) [0|10.2] "KW"  TCU,VCU,CGW_PT
 SG_ EVCOM_CompActlCnsmpCur : 47|8@0+ (0.2,0) [0|51] "A"  TCU,VCU,CGW_PT
 SG_ EVCOM_ActlOprtMode : 55|3@0+ (1,0) [0|7] ""  TCU,CGW_PT

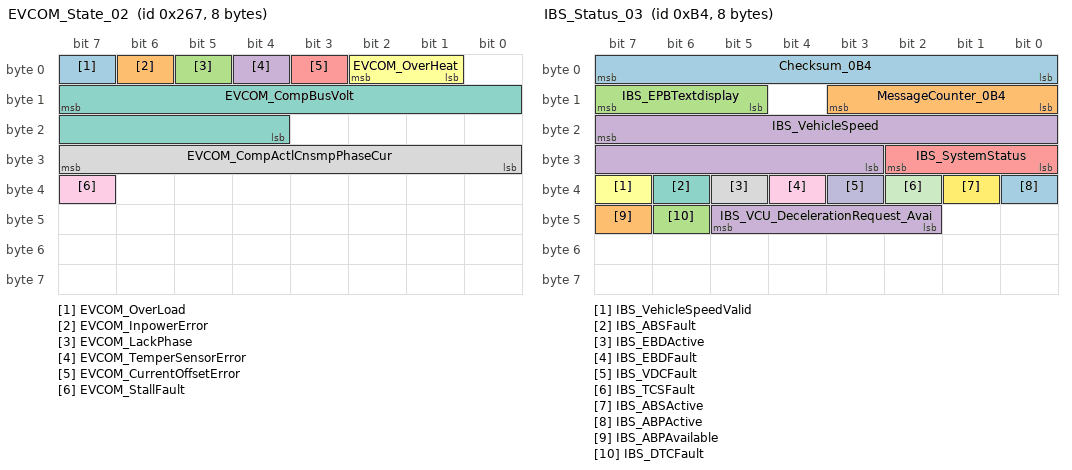
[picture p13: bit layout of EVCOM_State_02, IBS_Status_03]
BO_ 615 EVCOM_State_02: 8 EVCOM
 SG_ EVCOM_OverLoad : 7|1@0+ (1,0) [0|1] ""  TCU,CGW_PT
 SG_ EVCOM_InpowerError : 6|1@0+ (1,0) [0|1] ""  TCU,CGW_PT
 SG_ EVCOM_LackPhase : 5|1@0+ (1,0) [0|1] ""  TCU,CGW_PT
 SG_ EVCOM_TemperSensorError : 4|1@0+ (1,0) [0|1] ""  TCU,CGW_PT
 SG_ EVCOM_CurrentOffsetError : 3|1@0+ (1,0) [0|1] ""  TCU,CGW_PT
 SG_ EVCOM_OverHeat : 2|2@0+ (1,0) [0|3] ""  TCU,CGW_PT
 SG_ EVCOM_CompBusVolt : 15|12@0+ (2,0) [0|1022] "V"  TCU,CGW_PT
 SG_ EVCOM_CompActlCnsmpPhaseCur : 31|8@0+ (0.2,0) [0|51] "A"  TCU,CGW_PT
 SG_ EVCOM_StallFault : 39|1@0+ (1,0) [0|1] ""  TCU,CGW_PT

BO_ 179 IBS_Status_02: 8 CGW_PT
 SG_ Checksum_0B3 : 7|8@0+ (1,0) [0|255] ""  MCU,PRND,BMS
 SG_ MessageCounter_0B3 : 11|4@0+ (1,0) [0|15] ""  MCU,PRND,BMS
 SG_ IBS_EPBFailureLamp : 23|2@0+ (1,0) [0|1] ""  PRND
 SG_ IBS_BrakeLightRequest : 21|2@0+ (1,0) [0|3] "" Vector__XXX
 SG_ IBS_EPBworkingSts : 19|3@0+ (1,0) [0|7] ""  MCU,BMS
 SG_ IBS_TCSActive : 31|1@0+ (1,0) [0|1] "" Vector__XXX
 SG_ IBS_VDCActive : 30|1@0+ (1,0) [0|1] "" Vector__XXX
 SG_ IBS_HDCAvailable : 27|1@0+ (1,0) [0|1] "" Vector__XXX
 SG_ IBS_AEBActive : 26|1@0+ (1,0) [0|1] "" Vector__XXX
 SG_ IBS_HHCActive : 25|1@0+ (1,0) [0|1] "" Vector__XXX
 SG_ IBS_HHCAvailable : 24|1@0+ (1,0) [0|1] "" Vector__XXX
 SG_ IBS_AVHAvailable : 39|1@0+ (1,0) [0|1] "" Vector__XXX
 SG_ IBS_HazWarnReq : 38|2@0+ (1,0) [0|2] "" Vector__XXX
 SG_ IBS_EPBFunctionLamp : 35|2@0+ (1,0) [0|3] ""  PRND
 SG_ IBS_AEBAvailable : 33|1@0+ (1,0) [0|1] "" Vector__XXX
 SG_ IBS_AWBActive : 36|1@0+ (1,0) [0|1] "" Vector__XXX
 SG_ IBS_AWBAvailable : 32|1@0+ (1,0) [0|1] "" Vector__XXX
 SG_ IBS_EPBControllerSts : 47|2@0+ (1,0) [0|1] "" Vector__XXX

BO_ 180 IBS_Status_03: 8 CGW_PT
 SG_ Checksum_0B4 : 7|8@0+ (1,0) [0|255] ""  MCU,PRND,ADCU_PT,BMS
 SG_ MessageCounter_0B4 : 11|4@0+ (1,0) [0|15] ""  MCU,PRND,ADCU_PT,BMS
 SG_ IBS_EPBTextdisplay : 15|3@0+ (1,0) [0|4] "" Vector__XXX
 SG_ IBS_VehicleSpeed : 23|13@0+ (0.05625,0) [0|360] "km/h"  TCU,APTC,MCU,PRND,EVCOM,POD,BMS
 SG_ IBS_SystemStatus : 26|3@0+ (1,0) [0|7] "" Vector__XXX
 SG_ IBS_VehicleSpeedValid : 39|1@0+ (1,0) [0|1] "" Vector__XXX
 SG_ IBS_ABSFault : 38|1@0+ (1,0) [0|1] "" Vector__XXX
 SG_ IBS_EBDActive : 37|1@0+ (1,0) [0|1] "" Vector__XXX
 SG_ IBS_EBDFault : 36|1@0+ (1,0) [0|1] "" Vector__XXX
 SG_ IBS_VDCFault : 35|1@0+ (1,0) [0|1] ""  ADCU_PT
 SG_ IBS_TCSFault : 34|1@0+ (1,0) [0|1] ""  ADCU_PT
 SG_ IBS_ABSActive : 33|1@0+ (1,0) [0|1] "" Vector__XXX
 SG_ IBS_ABPActive : 32|1@0+ (1,0) [0|1] "" Vector__XXX
 SG_ IBS_ABPAvailable : 47|1@0+ (1,0) [0|1] "" Vector__XXX
 SG_ IBS_DTCFault : 46|1@0+ (1,0) [0|1] "" Vector__XXX
 SG_ IBS_VCU_DecelerationRequest_Avai : 45|4@0+ (1,0) [0|3] "" Vector__XXX

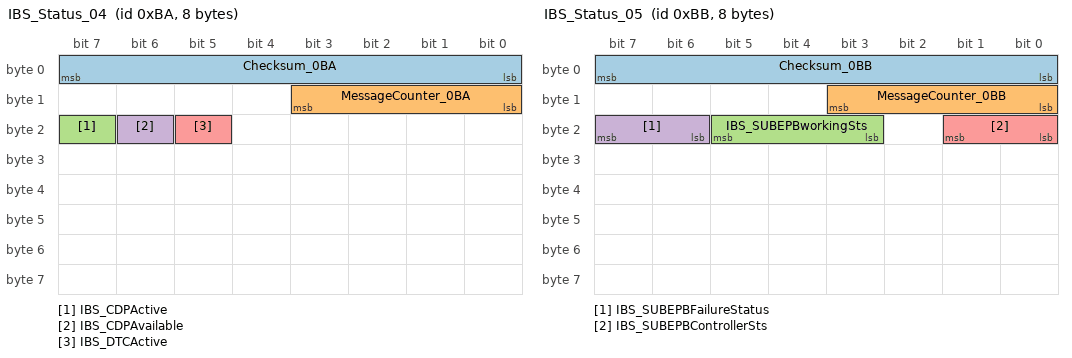
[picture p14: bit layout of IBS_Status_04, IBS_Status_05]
BO_ 186 IBS_Status_04: 8 CGW_PT
 SG_ Checksum_0BA : 7|8@0+ (1,0) [0|255] ""  PRND
 SG_ MessageCounter_0BA : 11|4@0+ (1,0) [0|15] ""  PRND
 SG_ IBS_CDPActive : 23|1@0+ (1,0) [0|1] ""  PRND
 SG_ IBS_CDPAvailable : 22|1@0+ (1,0) [0|1] "" Vector__XXX
 SG_ IBS_DTCActive : 21|1@0+ (1,0) [0|1] "" Vector__XXX

BO_ 187 IBS_Status_05: 8 IBS_PT
 SG_ Checksum_0BB : 7|8@0+ (1,0) [0|255] ""  VCU,ADCU_PT,CGW_PT
 SG_ MessageCounter_0BB : 11|4@0+ (1,0) [0|15] ""  VCU,ADCU_PT,CGW_PT
 SG_ IBS_SUBEPBworkingSts : 21|3@0+ (1,0) [0|7] ""  VCU,ADCU_PT,CGW_PT
 SG_ IBS_SUBEPBFailureStatus : 23|2@0+ (1,0) [0|3] ""  VCU,ADCU_PT,CGW_PT
 SG_ IBS_SUBEPBControllerSts : 17|2@0+ (1,0) [0|1] ""  VCU,ADCU_PT,CGW_PT

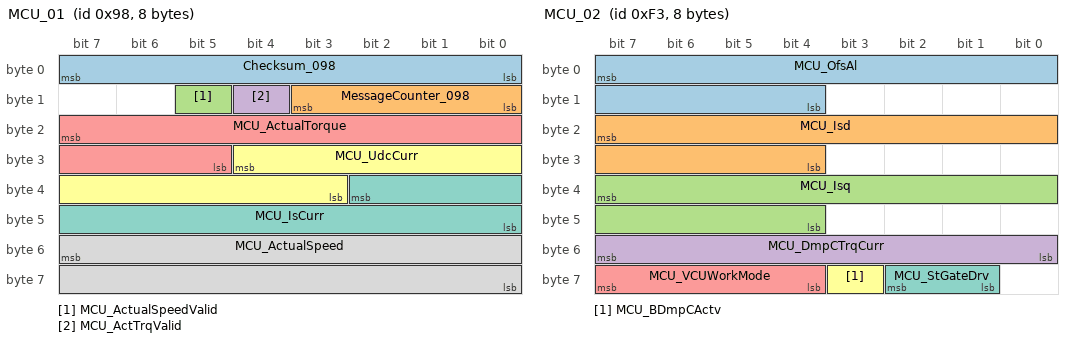
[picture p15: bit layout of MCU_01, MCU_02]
BO_ 152 MCU_01: 8 MCU
 SG_ Checksum_098 : 7|8@0+ (1,0) [0|255] ""  VCU,IBS_PT,CGW_PT
 SG_ MessageCounter_098 : 11|4@0+ (1,0) [0|15] ""  VCU,IBS_PT,CGW_PT
 SG_ MCU_ActualSpeedValid : 13|1@0+ (1,0) [0|1] ""  VCU,IBS_PT,CGW_PT
 SG_ MCU_ActTrqValid : 12|1@0+ (1,0) [0|1] ""  VCU,CGW_PT
 SG_ MCU_ActualTorque : 23|11@0+ (1,-1023) [-1023|1023] ""  VCU,CGW_PT
 SG_ MCU_UdcCurr : 28|10@0+ (1,0) [0|1021] ""  VCU,CGW_PT
 SG_ MCU_IsCurr : 34|11@0+ (1,-1023) [-1023|1023] ""  VCU,CGW_PT
 SG_ MCU_ActualSpeed : 55|16@0+ (1,-32767) [-32767|32767] ""  VCU,IBS_PT,CGW_PT

BO_ 243 MCU_02: 8 MCU
 SG_ MCU_OfsAl : 7|12@0+ (0.0878906,0) [0|359.6483352] ""  CGW_PT
 SG_ MCU_Isd : 23|12@0+ (0.5,-1023.5) [-1023.5|1023] ""  CGW_PT
 SG_ MCU_Isq : 39|12@0+ (0.5,-1023.5) [-1023.5|1023] ""  CGW_PT
 SG_ MCU_DmpCTrqCurr : 55|8@0+ (0.2,-25) [-25|25] ""  CGW_PT
 SG_ MCU_VCUWorkMode : 63|4@0+ (1,0) [0|8] ""  VCU,CGW_PT
 SG_ MCU_BDmpCActv : 59|1@0+ (1,0) [0|1] ""  VCU,CGW_PT
 SG_ MCU_StGateDrv : 58|2@0+ (1,0) [0|3] ""  TCU,CGW_PT

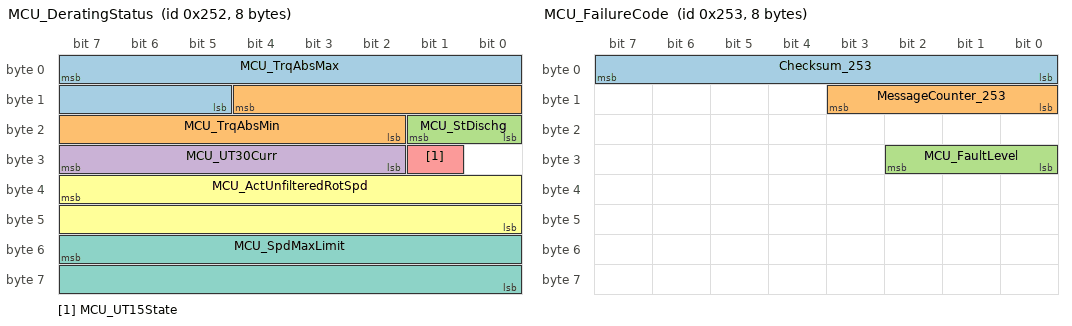
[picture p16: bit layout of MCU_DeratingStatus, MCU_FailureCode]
BO_ 594 MCU_DeratingStatus: 8 MCU
 SG_ MCU_TrqAbsMax : 7|11@0+ (1,-1023) [-1023|1023] ""  VCU,CGW_PT
 SG_ MCU_TrqAbsMin : 12|11@0+ (1,-1023) [-1023|1023] ""  VCU,CGW_PT
 SG_ MCU_StDischg : 17|2@0+ (1,0) [0|3] ""  CGW_PT
 SG_ MCU_UT30Curr : 31|6@0+ (0.5,0) [0|31] "V"  CGW_PT
 SG_ MCU_UT15State : 25|1@0+ (1,0) [0|1] ""  CGW_PT
 SG_ MCU_ActUnfilteredRotSpd : 39|16@0+ (1,-32767) [-32767|32767] ""  CGW_PT
 SG_ MCU_SpdMaxLimit : 55|16@0+ (1,-32767) [-32767|32767] ""  CGW_PT

BO_ 595 MCU_FailureCode: 8 MCU
 SG_ Checksum_253 : 7|8@0+ (1,0) [0|255] ""  VCU,CGW_PT
 SG_ MessageCounter_253 : 11|4@0+ (1,0) [0|15] ""  VCU,CGW_PT
 SG_ MCU_FaultLevel : 26|3@0+ (1,0) [0|7] ""  VCU,CGW_PT

BO_ 929 MCU_HardwareNumber: 8 MCU
 SG_ MCU_HwVer : 7|16@0+ (1,0) [0|65535] ""  CGW_PT

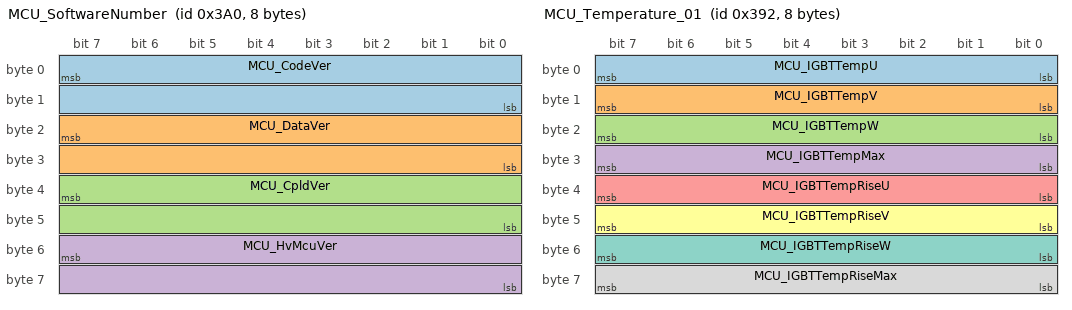
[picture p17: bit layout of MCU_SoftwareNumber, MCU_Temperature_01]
BO_ 928 MCU_SoftwareNumber: 8 MCU
 SG_ MCU_CodeVer : 7|16@0+ (1,0) [0|65535] ""  CGW_PT
 SG_ MCU_DataVer : 23|16@0+ (1,0) [0|65535] ""  CGW_PT
 SG_ MCU_CpldVer : 39|16@0+ (1,0) [0|65535] ""  CGW_PT
 SG_ MCU_HvMcuVer : 55|16@0+ (1,0) [0|65535] ""  CGW_PT

BO_ 914 MCU_Temperature_01: 8 MCU
 SG_ MCU_IGBTTempU : 7|8@0+ (1,-50) [-50|200] ""  CGW_PT
 SG_ MCU_IGBTTempV : 15|8@0+ (1,-50) [-50|200] ""  CGW_PT
 SG_ MCU_IGBTTempW : 23|8@0+ (1,-50) [-50|200] ""  CGW_PT
 SG_ MCU_IGBTTempMax : 31|8@0+ (1,-50) [-50|200] ""  TCU,VCU,CGW_PT
 SG_ MCU_IGBTTempRiseU : 39|8@0+ (1,0) [0|200] ""  CGW_PT
 SG_ MCU_IGBTTempRiseV : 47|8@0+ (1,0) [0|200] ""  CGW_PT
 SG_ MCU_IGBTTempRiseW : 55|8@0+ (1,0) [0|200] ""  CGW_PT
 SG_ MCU_IGBTTempRiseMax : 63|8@0+ (1,0) [0|200] ""  CGW_PT

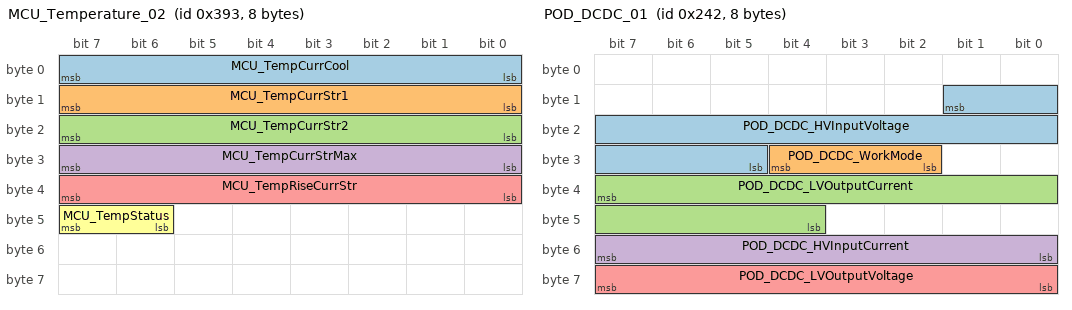
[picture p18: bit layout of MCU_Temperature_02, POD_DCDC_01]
BO_ 915 MCU_Temperature_02: 8 MCU
 SG_ MCU_TempCurrCool : 7|8@0+ (1,-50) [-50|200] ""  TCU,CGW_PT
 SG_ MCU_TempCurrStr1 : 15|8@0+ (1,-50) [-50|200] ""  CGW_PT
 SG_ MCU_TempCurrStr2 : 23|8@0+ (1,-50) [-50|200] ""  CGW_PT
 SG_ MCU_TempCurrStrMax : 31|8@0+ (1,-50) [-50|200] ""  TCU,CGW_PT
 SG_ MCU_TempRiseCurrStr : 39|8@0+ (1,0) [0|250] ""  CGW_PT
 SG_ MCU_TempStatus : 47|2@0+ (1,0) [0|3] ""  VCU,CGW_PT

BO_ 578 POD_DCDC_01: 8 POD
 SG_ POD_DCDC_HVInputVoltage : 9|13@0+ (0.1,0) [0|800] "V"  VCU,CGW_PT
 SG_ POD_DCDC_WorkMode : 28|3@0+ (1,0) [0|4] ""  VCU,CGW_PT
 SG_ POD_DCDC_LVOutputCurrent : 39|12@0+ (0.1,0) [0|400] "A"  CGW_PT
 SG_ POD_DCDC_HVInputCurrent : 55|8@0+ (0.1,0) [0|25.5] "A"  VCU,CGW_PT
 SG_ POD_DCDC_LVOutputVoltage : 63|8@0+ (0.1,0) [0|25.5] "V"  CGW_PT

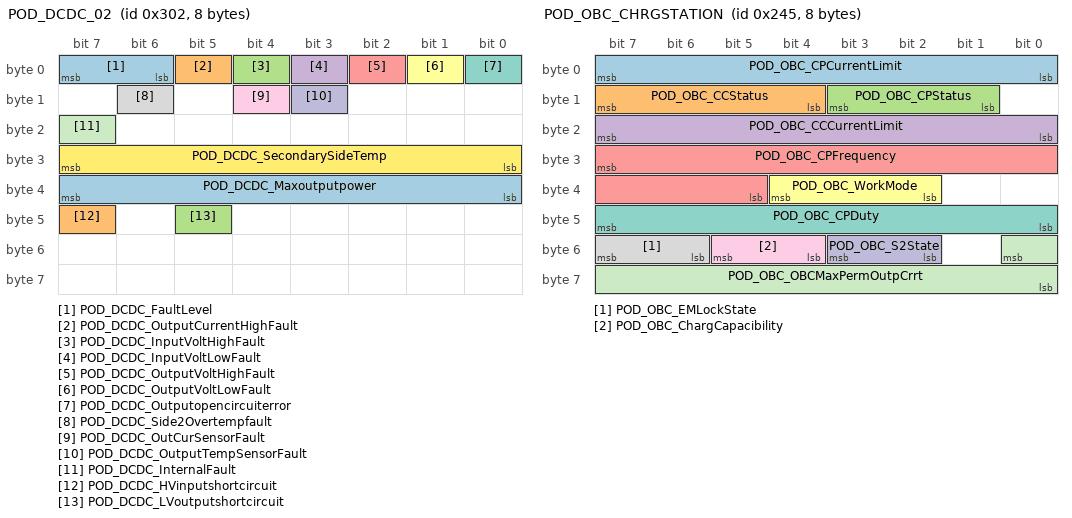
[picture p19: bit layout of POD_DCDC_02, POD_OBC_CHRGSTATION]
BO_ 770 POD_DCDC_02: 8 POD
 SG_ POD_DCDC_FaultLevel : 7|2@0+ (1,0) [0|3] ""  VCU,CGW_PT
 SG_ POD_DCDC_OutputCurrentHighFault : 5|1@0+ (1,0) [0|1] ""  CGW_PT
 SG_ POD_DCDC_InputVoltHighFault : 4|1@0+ (1,0) [0|1] ""  CGW_PT
 SG_ POD_DCDC_InputVoltLowFault : 3|1@0+ (1,0) [0|1] ""  CGW_PT
 SG_ POD_DCDC_OutputVoltHighFault : 2|1@0+ (1,0) [0|1] ""  CGW_PT
 SG_ POD_DCDC_OutputVoltLowFault : 1|1@0+ (1,0) [0|1] ""  CGW_PT
 SG_ POD_DCDC_Outputopencircuiterror : 0|1@0+ (1,0) [0|1] ""  CGW_PT
 SG_ POD_DCDC_Side2Overtempfault : 14|1@0+ (1,0) [0|1] ""  VCU,CGW_PT
 SG_ POD_DCDC_OutCurSensorFault : 12|1@0+ (1,0) [0|1] ""  CGW_PT
 SG_ POD_DCDC_OutputTempSensorFault : 11|1@0+ (1,0) [0|1] ""  CGW_PT
 SG_ POD_DCDC_InternalFault : 23|1@0+ (1,0) [0|1] ""  CGW_PT
 SG_ POD_DCDC_SecondarySideTemp : 31|8@0+ (1,-40) [-40|215] "celsius"  TCU,CGW_PT
 SG_ POD_DCDC_Maxoutputpower : 39|8@0+ (0.02,0) [0|5.1] "kW"  CGW_PT
 SG_ POD_DCDC_HVinputshortcircuit : 47|1@0+ (1,0) [0|1] ""  CGW_PT
 SG_ POD_DCDC_LVoutputshortcircuit : 45|1@0+ (1,0) [0|1] ""  CGW_PT

BO_ 581 POD_OBC_CHRGSTATION: 8 POD
 SG_ POD_OBC_CPCurrentLimit : 7|8@0+ (0.126,0) [0|32.13] "A"  VCU,CGW_PT
 SG_ POD_OBC_CCStatus : 15|4@0+ (1,0) [0|10] ""  VCU,CGW_PT
 SG_ POD_OBC_CPStatus : 11|3@0+ (1,0) [0|7] ""  VCU,CGW_PT
 SG_ POD_OBC_CCCurrentLimit : 23|8@0+ (0.126,0) [0|32.13] "A"  VCU,CGW_PT
 SG_ POD_OBC_CPFrequency : 31|11@0+ (1,0) [0|2000] "Hz"  CGW_PT
 SG_ POD_OBC_WorkMode : 36|3@0+ (1,0) [0|7] ""  VCU,CGW_PT
 SG_ POD_OBC_CPDuty : 47|8@0+ (1,0) [0|255] "percent"  VCU,CGW_PT
 SG_ POD_OBC_EMLockState : 55|2@0+ (1,0) [0|2] ""  VCU,CGW_PT
 SG_ POD_OBC_ChargCapacibility : 53|2@0+ (1,0) [0|2] ""  VCU,CGW_PT
 SG_ POD_OBC_S2State : 51|2@0+ (1,0) [0|2] ""  VCU,CGW_PT
 SG_ POD_OBC_OBCMaxPermOutpCrrt : 48|9@0+ (0.1,0) [0|40] "A"  VCU,CGW_PT

CM_ "Revision:V1.0,
Revision:V1.0.1,
Revision:V1.0.1,
Revision:V1.0.2,
Revision:V1.0.2,
Revision:V1.0.2,
Revision:V1.0.2,
Revision:V1.0.2,
Revision:V1.0.2,
Revision:V1.0.2,
Revision:V1.0.2,
Revision:V1.0.2,
Revision:V1.0.2,
Revision:V1.0.2,
Revision:V1.0.2,
Revision:V1.0.2,
Revision:V1.1,
Revision:V1.1,
Revision:V1.1,
Revision:V1.1,
Revision:V1.1,
Revision:V1.1,
Revision:V1.1,
Revision:V1.1,
Revision:V1.1,
Revision:V1.1,
Revision:V1.1,
Revision:V1.1,
Revision:V1.1,
Revision:V1.1,
Revision:V1.2,
Revision:V0.1.3,
Revision:V0.1.3,
Revision:V0.1.3,
Revision:V0.1.3,
Revision:V0.1.3,
Revision:V0.1.3,
Revision:V0.1.3,
Revision:V0.1.3,
Revision:V0.2.0,
Revision:V0.2.0,
Revision:V0.2.0,
Revision:V0.2.0,
Revision:V0.2.0,
Revision:V0.2.0,
Revision:V0.2.0,
Revision:V0.2.0,
Revision:V1.0.0,
Revision:V1.1.0,
Revision:V1.1.0,
Revision:V1.0.0,
Revision:V1.0.0,
Revision:V1.0.0,
Revision:V1.0.0,
Revision:V1.0.0,
Revision:V1.0.0,
Revision:V1.0.0,
Revision:V1.0.0,
Revision:V1";
CM_ SG_ 151 Checksum_097 "Checksum signal for frame";
CM_ SG_ 151 MessageCounter_097 "Message counter signal for frame";
CM_ SG_ 151 ACU_CrashOutputSts "Crash Output Status";
CM_ SG_ 151 ACU_CrashOutputStsValid "Collision signal effective indication";
CM_ SG_ 151 ACU_DriverSeatBeltSts "Driver seat belt status";
CM_ SG_ 151 ACU_DriverSeatBeltStsValid "Driver seat belt state invalid";
CM_ SG_ 151 ACU_PassengerSeatBeltSts "Passenger seat belt status";
CM_ SG_ 151 ACU_PassengerSeatBeltStsValid "Passenger seat belt status invalid signal";
CM_ SG_ 151 ACU_PassengerSts "Passenger seat occupied state";
CM_ SG_ 151 ACU_SecondLeftSeatBeltSts "Second row left seat belt condition";
CM_ SG_ 151 ACU_RLSeatBeltStatusValid "Second row seat belt status on the left is valid";
CM_ SG_ 151 ACU_SecondLeftSts "The left seat of the second row is occupied";
CM_ SG_ 151 ACU_SecondRightSeatBeltSts "Second row right seat belt status";
CM_ SG_ 151 ACU_RRSeatBeltStatusValid "Second row seat belt status on the lright is valid";
CM_ SG_ 151 ACU_SecondRightSts "The right seat of the second row is occupied";
CM_ SG_ 151 ACU_PassengerAirbagSts "Passenger Airbag Status, closed or not";
CM_ SG_ 151 ACU_DriverWarningLampSts "Driver Warning Lamp Status";
CM_ SG_ 151 ACU_PassengerWarningLampSts "Passenger Warning Lamp Status";
CM_ SG_ 151 ACU_WarningLampSts "WarningLampStatus";
CM_ SG_ 918 ADCU_TemperatureSts "Information about the current temperature of the ADCU control unit";
CM_ SG_ 613 APTC_HVPowerUpReq "APTC high voltage power supply off line request";
CM_ SG_ 613 APTC_HeatingFaltStatus "ptc heater core status";
CM_ SG_ 613 APTC_DriveFaltStatus "Ptc driver status";
CM_ SG_ 613 APTC_LostCommuFaltStatus "TCU signal lost";
CM_ SG_ 613 APTC_IGBTFaltStatus "IGBT failure";
CM_ SG_ 613 APTC_Core1TempSensorFaltStatus "Left core sensor temperature error";
CM_ SG_ 613 APTC_LeftCoreTemp "Left core sensor temperature";
CM_ SG_ 613 APTC_RightCoreTemp "Right core sensor temperature";
CM_ SG_ 613 APTC_PowerConsumption "APTC OutPut Power";
CM_ SG_ 613 APTC_HVBusVoltage "HV voltage";
CM_ SG_ 613 APTC_OverCurrentFault "Indicate Over Current Fault";
CM_ SG_ 613 APTC_LowVoltageStatus "Indicate Low Volatge Status";
CM_ SG_ 613 APTC_HighVoltageStatus "Indicate High Volatge Status";
CM_ SG_ 613 APTC_OverLoadStatus "Indicate Over load Fault";
CM_ SG_ 613 APTC_IGBTTempSensorStatus "Indicate IGBT Sensor Status";
CM_ SG_ 613 APTC_PCBTempSensorStatus "Indicate PCB Sensor Status";
CM_ SG_ 613 APTC_Core2TempSensorFaltStatus "Right core sensor temperature error";
CM_ SG_ 822 BCM_RLHSHumidSensorValue "This signal delivers information about air humid : from 0% to 100%";
CM_ SG_ 822 BCM_RLHSSolarDrvr "The left solar sensor measured";
CM_ SG_ 822 BCM_RLHSSolarPass "The right solar sensor measured";
CM_ SG_ 822 BCM_RLHSTempSensorValue "This signal delivers information about temperature in car";
CM_ SG_ 822 BCM_RLHSTempDewPoint "Dew point temperature";
CM_ SG_ 822 BCM_HUDBriUnit "HUD Brightness Unit";
CM_ SG_ 822 BCM_HUDBriRawVal "Brightness adjust value for HUD";
CM_ SG_ 826 Checksum_33A "Checksum signal for frame";
CM_ SG_ 826 MessageCounter_33A "Message counter signal for frame";
CM_ SG_ 826 BCM_GearTimesSts "R gear times status";
CM_ SG_ 826 BCM_ChrgFlapLockSts "Charging flap lock status";
CM_ SG_ 826 BCM_FRSeatBeltRemindReq "The front passenger seat belt unfastened reminder request signal";
CM_ SG_ 826 BCM_FLSeatBeltRemindReq "The driver seat belt unfastened reminder request signal";
CM_ SG_ 826 BCM_KeyNotInCarRemind "Key not found reminder";
CM_ SG_ 826 BCM_RRSeatBeltRemindReq "The second row right seat belt unfastened reminder request signal";
CM_ SG_ 826 BCM_RLSeatBeltRemindReq "The second row left seat belt unfastened reminder request signal";
CM_ SG_ 826 BCM_WiperServiceSts "Wiper Service Mode State";
CM_ SG_ 826 BCM_AutoCloseWinFunSts "Auto close window function status";
CM_ SG_ 826 BCM_DomeLampBrightSts "Dome lamp brightness feedback signal";
CM_ SG_ 826 BCM_PuddleLiReq "Puddle light in exterior mirror request";
CM_ SG_ 826 BCM_DomeLampAutoSts "Dome Lamp automatic setting";
CM_ SG_ 826 BCM_FrontWiperModeSts "Front wipers mode status feedback";
CM_ SG_ 826 BCM_WiperWorkingSts "Front wipers working status";
CM_ SG_ 826 BCM_WelLightshowOnOffSts "Welcome Light show switch state signal";
CM_ SG_ 625 checksum_271 "Checksum signal for frame";
CM_ SG_ 625 MessageCounter_271 "Message counter signal for frame";
CM_ SG_ 625 BCM_PepsPowerMode "Power mode";
CM_ SG_ 625 BCM_PowerOffDisplayReq "Power-down pop-up window prompt request";
CM_ SG_ 626 BCM_Immo_State "BCM-VCU Immobilizing state";
CM_ SG_ 626 BCM_SecOCFV_272 "Freshness value";
CM_ SG_ 626 BCM_SecOCMAC_272 "Message authentication code";
CM_ SG_ 820 BCM_AntiTheftSts "Anti-theft status";
CM_ SG_ 820 BCM_AlarmedRemind "Vehicle has experienced anti-theft alarm reminders";
CM_ SG_ 820 BCM_ImmobilizingRemind "Immobilizing Remind";
CM_ SG_ 820 BCM_SecOCFV_334 "Freshness value";
CM_ SG_ 820 BCM_SecOCMAC_334 "Message authentication code";
CM_ SG_ 931 BMS_BatCodeFrameNO "BatteryCodeNumber";
CM_ SG_ 931 BMS_BatCodeFrameLength "Length of battery code";
CM_ SG_ 931 BMS_BatCode1 "Battery code 1";
CM_ SG_ 931 BMS_BatCode2 "Battery code 2";
CM_ SG_ 931 BMS_BatCode3 "Battery code 3";
CM_ SG_ 931 BMS_BatCode4 "Battery code 4";
CM_ SG_ 931 BMS_BatCode5 "Battery code 5";
CM_ SG_ 931 BMS_BatCode6 "Battery code 6";
CM_ SG_ 934 BMS_BatType "Battery type";
CM_ SG_ 934 BMS_CellNumbers "Sum of cell in pack";
CM_ SG_ 934 BMS_RatCapacity "Rated capacity of power battery system";
CM_ SG_ 934 BMS_RatEnergy "Nominal total energy of power battery";
CM_ SG_ 934 BMS_RatBatVoltage "Rated Voltage of power battery system";
CM_ SG_ 935 BMS_BatSupName "Battery supplier name";
CM_ SG_ 938 BMS_RemainCapacity "BMS Remain Capacity";
CM_ SG_ 993 BMS_Cellinfo "Battery cell information, including cell temperature and voltage.";
CM_ SG_ 536 BMS_ThermometerProbes "Sum of Temperature Probe in PACK";
CM_ SG_ 536 BMS_AverageCellTemp "Average battery cell temperature";
CM_ SG_ 536 BMS_MaxCellTemp "Maximal Cell TemperatureInlet value";
CM_ SG_ 536 BMS_MinCellTemp "Minimal Cell TemperatureInlet value";
CM_ SG_ 536 BMS_MaxCellTempModuleNO "Maximal Cell TemperatureInlet module NO";
CM_ SG_ 536 BMS_MinCellTempModuleNO "Minimal Cell TemperatureInlet module NO";
CM_ SG_ 536 BMS_MaxCellTempNO "Maximal Cell TemperatureInlet NO";
CM_ SG_ 536 BMS_MinCellTempNO "Minimal Cell TemperatureInlet NO";
CM_ SG_ 535 BMS_MaxCellVoltage "The Maximal Cell Voltage";
CM_ SG_ 535 BMS_MinCellVoltage "The Minimal Cell Voltage";
CM_ SG_ 535 BMS_MaxCellVoltageModuleNO "Maximal Cell Voltage module NO";
CM_ SG_ 535 BMS_MinCellVoltageModlueNO "Minimal Cell Voltage module NO";
CM_ SG_ 535 BMS_MaxCellVoltageNO "The Maximal Cell Voltage NO";
CM_ SG_ 535 BMS_MinCellVoltageNO "The Minimal Cell Voltage NO";
CM_ SG_ 530 BMS_RemChagTime "Remaining charging time prediction in minute";
CM_ SG_ 530 BMS_MaxChagVoltage "Maximum allowable charging voltage";
CM_ SG_ 530 BMS_AllowChagCurrent "Maximum allowable charging current";
CM_ SG_ 531 BMS_DCChgMode "DC charging mode";
CM_ SG_ 531 BMS_AbortAchiveSingleVolt "Abort charging when reaching the set value of unit voltage";
CM_ SG_ 531 BMS_AbortAchiveTotalVolt "Stop charging when the total voltage setting is reached";
CM_ SG_ 531 BMS_AbortFaultBMSTemp "BMS over temperature suspension charging";
CM_ SG_ 531 BMS_AbortFaultBatteryTemp "Battery pack over temperature stops charging";
CM_ SG_ 531 BMS_AbortErrorCurrent "Overcurrent suspension charging";
CM_ SG_ 531 BMS_AbortAchivesetValue "Abort charging when reaching the required SOC target value";
CM_ SG_ 531 BMS_AbortErrorVoltage "Abnormal voltage suspends charging";
CM_ SG_ 531 BMS_ChagComplete "Charging completion status";
CM_ SG_ 531 BMS_ChargeRequest "BMS charging request";
CM_ SG_ 936 BMS_SingChgkwh "Single charged electric quantity (charger online)";
CM_ SG_ 936 BMS_SumChgkwh "Accumulated charged electric quantity";
CM_ SG_ 936 BMS_BatChagSum "Sum of how many cycle for battery charged";
CM_ SG_ 937 BMS_SumDisChgkwh "Accumulated discharged electric quantity";
CM_ SG_ 528 BMS_PosRelayStatus "State of positive relay status";
CM_ SG_ 528 BMS_PTCRelayStatus "the status of PTC relay from BMS side";
CM_ SG_ 528 BMS_NegRelayStatus "State of negtive relay status";
CM_ SG_ 528 BMS_PreRelayStatus "State of precharge relay status";
CM_ SG_ 528 BMS_PTC_VoltageValue "Voltage across Pack PTC";
CM_ SG_ 528 BMS_PTC_WorkStatus "PTC WorkStatus";
CM_ SG_ 528 BMS_PTC_WorkTime "PTC WorkTime";
CM_ SG_ 772 BMS_ErrorCellOverVolt "Cell voltage over limit";
CM_ SG_ 772 BMS_ErrorCellUnderVolt "Cell voltage under limit";
CM_ SG_ 772 BMS_ErrorCellHighTemp "Cell temperature over limit";
CM_ SG_ 772 BMS_ErrorCellLowTemp "Cell temperature under limit";
CM_ SG_ 772 BMS_ErrorBattOverVolt "Battery voltage over limit";
CM_ SG_ 772 BMS_ErrorBattUnderVolt "Battery voltage under limit";
CM_ SG_ 772 BMS_ErrorChaCurrentOver "Battery charge current over limit";
CM_ SG_ 772 BMS_ErrorDisChaCurrentOver "Battery discharge current over limit";
CM_ SG_ 772 BMS_ErrorBSUOffline "BSU offline";
CM_ SG_ 772 BMS_ErrorLeakCurrent "Leakage current exceeds the limit";
CM_ SG_ 772 BMS_ErrorCellVoltDiff "Cell‘s voltage diffrence between maximal and minimal one is over limit";
CM_ SG_ 772 BMS_ErrorCellTempDiff "Cell's temperature diffrence between maximal and minimal one is over limit";
CM_ SG_ 772 BMS_ErrorBatVolt "Battery error";
CM_ SG_ 772 BMS_ErrorHallOffline "Hall offline";
CM_ SG_ 772 BMS_ErrorCellVoltOffline "Cell voltage detector offline";
CM_ SG_ 772 BMS_ErrorCellTempOffline "Cell temperature detector offline";
CM_ SG_ 772 BMS_ErrorPreChaFailed "HV precharg failed";
CM_ SG_ 772 BMS_ErrorRelay "Relay error";
CM_ SG_ 772 BMS_ErrorBSUBalance "BSU balance fuction error";
CM_ SG_ 772 BMS_ErrorLowSoc "SOC under limit";
CM_ SG_ 772 BMS_ErrorHighSoc "SOC over limit";
CM_ SG_ 772 BMS_ErrorSoCJump_RM "SOC jump";
CM_ SG_ 772 BMS_ErrorHVIL "HVIL offline";
CM_ SG_ 772 BMS_ErrorEmergencyOffCrash "Crash signal";
CM_ SG_ 772 BMS_ErrorSystemsMatch "BMS not matched alarm";
CM_ SG_ 772 BMS_ErrorSmoke "Smoke alarm";
CM_ SG_ 772 BMS_ErrorLeakDet "Leakage detection";
CM_ SG_ 772 BMS_ThermalRunawayFault "Thermal Runaway failure";
CM_ SG_ 772 BMS_DTC "Fault code";
CM_ SG_ 933 BMS_BatProDatYear "Battery pack production date year";
CM_ SG_ 933 BMS_BatProDatMonth "Battery pack production date month";
CM_ SG_ 933 BMS_BatProDatDay "Battery pack production date day";
CM_ SG_ 992 BMS_FeedEnergySts "Accumulated actual feedback energy for this operation";
CM_ SG_ 992 BMS_DirveDiscSts "Accumulated actual discharge energy during this operation";
CM_ SG_ 193 Checksum_0C1 "Checksum signal for frame";
CM_ SG_ 193 MessageCounter_0C1 "Message counter signal for frame";
CM_ SG_ 193 BMS_ErrorIsolationSingleLow "The insulation resistance is too low.";
CM_ SG_ 193 BMS_WorkMode "State of BMS";
CM_ SG_ 193 BMS_BalancingStatus "Cell balancing status";
CM_ SG_ 193 BMS_InsulationDetectionStatus "BMS insulation detection status";
CM_ SG_ 193 BMS_HVinterlockState "HV interlock state";
CM_ SG_ 193 BMS_ThrmlRunawayFault "Thermal runaway fault";
CM_ SG_ 193 BMS_PreCharge "State of BMS Precharge";
CM_ SG_ 193 BMS_ChargeStatus "State of BMS Charge Mode";
CM_ SG_ 193 BMS_RunHeatStatus "State of Heat state when car running";
CM_ SG_ 193 BMS_ErrorLevel "BMS Error Level";
CM_ SG_ 193 BMS_SOH "BMS SOH";
CM_ SG_ 193 BMS_SysRegInsulationValue "BMS system insulation value";
CM_ SG_ 194 BMS_BattVolt "the voltage of dclink from BMS side";
CM_ SG_ 194 BMS_BattCurr "the current of dclink from BMS side";
CM_ SG_ 194 BMS_Heatcurrent "Heat current";
CM_ SG_ 532 BMS_PackVoltage "Pack Inside Volt";
CM_ SG_ 532 BMS_LinkVoltage "Pack Outside Volt";
CM_ SG_ 532 BMS_SOC "BMS Real SOC";
CM_ SG_ 532 BMS_DisplaySOC "BMS Display SOC";
CM_ SG_ 533 BMS_FeedbackCurr "Maximum feed back charging current(30S)";
CM_ SG_ 533 BMS_DisChgCurr "Maximum allowable discharge current";
CM_ SG_ 771 BMS_CoolCommand "Cool command from BMS";
CM_ SG_ 771 BMS_AllowCellTemperature "Maximum allowable charging temperature";
CM_ SG_ 771 BMS_TargetBatteryMaxCellTemp "Target battery cell temperature";
CM_ SG_ 771 BMS_TempInlet "Water inlet temperature";
CM_ SG_ 771 BMS_HeatCommand "Heat command from BMS";
CM_ SG_ 771 BMS_KeepWarmRequest "Keep warm request";
CM_ SG_ 771 BMS_KeepWarmStatus "Keep warm status";
CM_ SG_ 771 BMS_RTC_Request "BMS real time clock wake up request";
CM_ SG_ 771 BMS_BalanceCommand "Balance command from BMS";
CM_ SG_ 771 BMS_Tempoutlet "Outlet water temperature";
CM_ SG_ 771 BMS_FlowRate "Coolant flow rate";
CM_ SG_ 932 BMS_SoftVsesion "BMS software version";
CM_ SG_ 932 BMS_HardVsesion "BMS hardware version";
CM_ SG_ 932 BMS_ComVersion "BMS Communication Protocol Version";
CM_ SG_ 932 BMS_BatProRights "Battery property rights";
CM_ SG_ 932 BMS_Life "BMS life signal";
CM_ SG_ 632 Checksum_278 "Checksum signal for frame";
CM_ SG_ 632 MessageCounter_278 "Message counter signal for frame";
CM_ SG_ 632 CGW_VehicleState "Vehicle state";
CM_ SG_ 642 DCM_FL_DoorFLLockSts "Left front door lock status";
CM_ SG_ 642 DCM_FL_DoorFLAngle "FL door angle signal";
CM_ SG_ 642 DCM_FL_FLPESwitchReq "Front left exterior door handle PE switch status";
CM_ SG_ 642 DCM_FL_DoorObstacleSts "Left front door obstacle avoidance status";
CM_ SG_ 642 DCM_FL_DoorAntiPinchSts "Left front door anti pinch status";
CM_ SG_ 642 DCM_FL_ElectricDoorMovementSts "FL Electric door movement status";
CM_ SG_ 642 DCM_FL_LinkageAvoidanceReq "FLdoor linkage avoidance";
CM_ SG_ 642 DCM_FL_InsideSwitchReq "Driver's door open switch operation";
CM_ SG_ 642 DCM_FL_WindowSts "Left front window status";
CM_ SG_ 642 DCM_FL_PWM_POS_STS "Driver window position status";
CM_ SG_ 642 DCM_FL_GLASS_LOCATION "Left front window percentage position";
CM_ SG_ 642 DCM_FL_FrontDoorAngleFeedback "Feedback value for rear door angle setting";
CM_ SG_ 650 Checksum_28A "Checksum signal for frame";
CM_ SG_ 650 MessageCounter_28A "Message counter signal for frame";
CM_ SG_ 650 DCM_FL_DoorFLSts "Driver's door status";
CM_ SG_ 650 DCM_FL_FRWndSwA "Front right window enabled";
CM_ SG_ 650 DCM_FL_RLWndSwA "Rear left window enabled";
CM_ SG_ 650 DCM_FL_RRWndSwA "Rear right window enabled";
CM_ SG_ 650 DCM_FL_LeftMirrorHorizontalPos "Left and right position of left rearview mirror (percentage)";
CM_ SG_ 650 DCM_FL_LeftMirrorVerticalPos "Up and down positions of the left rearview mirror (percentage)";
CM_ SG_ 650 DCM_FL_MirrorAutoTurnDownSts "Left exterior mirror automatic flip down enable status feedback";
CM_ SG_ 650 DCM_FL_MirrorAutoFoldUnfoldSts "Left exterior mirror automatic folding and unfolding setting status";
CM_ SG_ 650 DCM_FL_RearmirrorHeatingSts "Left rear mirror heat status";
CM_ SG_ 650 DCM_FL_MirrorFold_UnfoldSts "Mirror folding or unfolding status signal";
CM_ SG_ 643 DCM_FR_DoorFRLockSts "Right front door locked state";
CM_ SG_ 643 DCM_FR_DoorFRAngle "FR door angle signal";
CM_ SG_ 643 DCM_FR_FRPESwitchReq "Right front exterior door handle PE switch status";
CM_ SG_ 643 DCM_FR_DoorAntiPinchSts "Right front door anti pinch status";
CM_ SG_ 643 DCM_FR_DoorObstacleSts "Right front door obstacle avoidance status";
CM_ SG_ 643 DCM_FR_ElectricDoorMovementSts "FR Electric door movement status";
CM_ SG_ 643 DCM_FR_LinkageAvoidanceReq "RR door linkage avoidance";
CM_ SG_ 643 DCM_FR_InsideSwitchReq "Front passenger door open switch operation";
CM_ SG_ 643 DCM_FR_WindowSts "Front right window status";
CM_ SG_ 643 DCM_FR_PWM_POS_STS "Passenger window position status";
CM_ SG_ 643 DCM_FR_GLASS_LOCATION "Right front window percentage position";
CM_ SG_ 643 DCM_FR_FrontDoorAngleFeedback "Feedback value for rear door angle setting";
CM_ SG_ 643 DCM_FR_FRWindowLockSts "Passenger window disabled";
CM_ SG_ 643 DCM_FR_DoorFRSts "Right front door status signal";
CM_ SG_ 651 DCM_FR_AmbientTemperatureValid "Ambient temperature Valid";
CM_ SG_ 651 DCM_FR_AmbientTemperature "Ambient temperature";
CM_ SG_ 651 DCM_FR_RightMirrorHorizontalPos "Right rearview mirror left and right position (percentage)";
CM_ SG_ 651 DCM_FR_RightMirrorVerticalPos "Right rearview mirror up and down position (percentage)";
CM_ SG_ 651 DCM_FR_MirrorAutoTurnDownSts "Right exterior mirror automatic flip down enable status feedback";
CM_ SG_ 651 DCM_FR_MirrorAutoFoldUnfoldSts "Right exterior mirror automatic folding and unfolding setting status";
CM_ SG_ 651 DCM_FR_RearmirrorHeatingSts "EN: Right rear mirror heat status";
CM_ SG_ 651 DCM_FR_MirrorFold_UnfoldSts "Mirror folding or unfolding status signal";
CM_ SG_ 644 DCM_RL_DoorRLLockSts "left rear door locked state";
CM_ SG_ 644 DCM_RL_DoorRLAngle "RL door angle signal";
CM_ SG_ 644 DCM_RL_RLPESwitchReq "Left rear exterior door handle PE switch status";
CM_ SG_ 644 DCM_RL_DoorObstacleSts "Left rear door obstacle avoidance status";
CM_ SG_ 644 DCM_RL_DoorAntiPinchSts "Left rear  door anti pinch status";
CM_ SG_ 644 DCM_RL_ElectricDoorMovementSts "RL Electric door movement status";
CM_ SG_ 644 DCM_RL_LinkageAvoidanceReq "FL door linkage avoidance";
CM_ SG_ 644 DCM_RL_InsideSwitchReq "Left rear door open switch operation";
CM_ SG_ 644 DCM_RL_WindowSts "Left rear window status";
CM_ SG_ 644 DCM_RL_PWM_POS_STS "Left rear window position status";
CM_ SG_ 644 DCM_RL_GLASS_LOCATION "Left rear window percentage position";
CM_ SG_ 644 DCM_RL_RearDoorAngleFeedback "Feedback value for rear door angle setting";
CM_ SG_ 644 DCM_RL_RLWindowLockSts "Rear left window disabled";
CM_ SG_ 644 DCM_RL_DoorRLSts "Left rear door status signal";
CM_ SG_ 645 DCM_RR_DoorRRLockSts "Right rear door locked state";
CM_ SG_ 645 DCM_RR_DoorRRAngle "RR door angle signal";
CM_ SG_ 645 DCM_RR_RRPESwitchReq "Right rear exterior door handle PE switch status";
CM_ SG_ 645 DCM_RR_DoorObstacleSts "Right rear door obstacle avoidance status";
CM_ SG_ 645 DCM_RR_DoorAntiPinchSts "Right rear door anti pinch status";
CM_ SG_ 645 DCM_RR_ElectricDoorMovementSts "RR Electric door movement status";
CM_ SG_ 645 DCM_RR_LinkageAvoidanceReq "FR door linkage avoidance";
CM_ SG_ 645 DCM_RR_InsideSwitchReq "Right rear door o open switch operation";
CM_ SG_ 645 DCM_RR_WindowSts "Right rear window status";
CM_ SG_ 645 DCM_RR_PWM_POS_STS "Right rear window position status";
CM_ SG_ 645 DCM_RR_GLASS_LOCATION "Right rear window percentage position";
CM_ SG_ 645 DCM_RR_RearDoorAngleFeedback "Feedback value for rear door angle setting";
CM_ SG_ 645 DCM_RR_RRWindowLockSts "Rear right window disabled";
CM_ SG_ 645 DCM_RR_DoorRRSts "Right rear door status signal";
CM_ SG_ 614 EVCOM_OverPwrDropFreqError "EVCOM Over Power Drop Frequency Error";
CM_ SG_ 614 EVCOM_OverCurDropFreqError "EVCOM Over Current Drop Frequency Error";
CM_ SG_ 614 EVCOM_CommunicationError "EVCOM Communication Error";
CM_ SG_ 614 EVCOM_StandByUnderVolError "EVCOM Stand By Under Voltage Error";
CM_ SG_ 614 EVCOM_StandByOverVolError "EVCOM Stand By Over Voltage Error";
CM_ SG_ 614 EVCOM_UnderVoltageError "EVCOM Under Voltage Error LV";
CM_ SG_ 614 EVCOM_OverVoltageError "EVCOM Over Voltage Error LV";
CM_ SG_ 614 EVCOM_OverCurrentError "EVCOM Over Current Error";
CM_ SG_ 614 EVCOM_CompDeviceInternTemp "Device Internal Temperature";
CM_ SG_ 614 EVCOM_CompActlSpd "Compressor Actual Speed";
CM_ SG_ 614 EVCOM_CompActlPwrCnsmp "Compressor Actual Power Consumption";
CM_ SG_ 614 EVCOM_CompActlCnsmpCur "Compressor Run Current";
CM_ SG_ 614 EVCOM_ActlOprtMode "Air Conditioning Compressor Actual Operation Mode";
CM_ SG_ 615 EVCOM_OverLoad "EVCOM  Over Load Error";
CM_ SG_ 615 EVCOM_InpowerError "EVCOM  Inpower Error";
CM_ SG_ 615 EVCOM_LackPhase "EVCOM  Lack Phase Error";
CM_ SG_ 615 EVCOM_TemperSensorError "EVCOM  Temperature Sensor Error";
CM_ SG_ 615 EVCOM_CurrentOffsetError "EVCOM Current offset Error";
CM_ SG_ 615 EVCOM_OverHeat "EVCOM Over Heat Error";
CM_ SG_ 615 EVCOM_CompBusVolt "Compressor Bus Voltage";
CM_ SG_ 615 EVCOM_CompActlCnsmpPhaseCur "Compressor Run Phase Current";
CM_ SG_ 615 EVCOM_StallFault "Stall Fault";
CM_ SG_ 179 Checksum_0B3 "Checksum signal for frame";
CM_ SG_ 179 MessageCounter_0B3 "Message counter signal for frame";
CM_ SG_ 179 IBS_EPBFailureLamp "EN: EPB Failure Lamp";
CM_ SG_ 179 IBS_BrakeLightRequest "EN: IBS request to turn on the stop lamp when the active braking is triggered";
CM_ SG_ 179 IBS_EPBworkingSts "EN: EPB Status";
CM_ SG_ 179 IBS_TCSActive "EN: Tindicates TCS intervention active,TCS will detect spinning wheels and request torque reduction/limitation";
CM_ SG_ 179 IBS_VDCActive "EN: indicates VDC intervention active,
ESP will detect other vehicle slip/slide situations, and brake individual wheels to counteract the vehicle slid";
CM_ SG_ 179 IBS_HDCAvailable "EN: HDC Function Available";
CM_ SG_ 179 IBS_AEBActive "EN: AEB Function Active";
CM_ SG_ 179 IBS_HHCActive "EN: HHC Function Active";
CM_ SG_ 179 IBS_HHCAvailable "EN: HHC Function Available";
CM_ SG_ 179 IBS_AVHAvailable "EN: AVH Function Available";
CM_ SG_ 179 IBS_HazWarnReq "EN: Hazard warning Lamps";
CM_ SG_ 179 IBS_EPBFunctionLamp "EN: EPB Function Lamp";
CM_ SG_ 179 IBS_AEBAvailable "Information indicating whether braking control for AEB is possible or not";
CM_ SG_ 179 IBS_AWBActive "AWB is active or not";
CM_ SG_ 179 IBS_AWBAvailable "AWB is available or not";
CM_ SG_ 179 IBS_EPBControllerSts "Primary controller switchover status of an EPB";
CM_ SG_ 180 Checksum_0B4 "Checksum signal for frame";
CM_ SG_ 180 MessageCounter_0B4 "Message counter signal for frame";
CM_ SG_ 180 IBS_EPBTextdisplay "EN: EPB Text display";
CM_ SG_ 180 IBS_VehicleSpeed "EN: Vehicle speed";
CM_ SG_ 180 IBS_SystemStatus "IBS System Status";
CM_ SG_ 180 IBS_VehicleSpeedValid "EN: Vehicle speed valid";
CM_ SG_ 180 IBS_ABSFault "ABS system has detected a failure which does not allow a reliable ABS regulation and is therefore switched off.";
CM_ SG_ 180 IBS_EBDActive "EBD Active Status";
CM_ SG_ 180 IBS_EBDFault "ABS system has detected a heavy fault, which does not even allow a reliable electronic brake distribution and is therefore completely shut down.";
CM_ SG_ 180 IBS_VDCFault "EN: VDC status valid";
CM_ SG_ 180 IBS_TCSFault "EN: TCS status valid";
CM_ SG_ 180 IBS_ABSActive "indicates ABS intervention active.";
CM_ SG_ 180 IBS_ABPActive "Prefill(ABP) is active or not.";
CM_ SG_ 180 IBS_ABPAvailable "Prefill(ABP) is available or not.";
CM_ SG_ 180 IBS_DTCFault "Drag Torque Control fault";
CM_ SG_ 180 IBS_VCU_DecelerationRequest_Avai "Indicates whether the VCU-related deceleration request function is available";
CM_ SG_ 186 Checksum_0BA "Checksum signal for frame";
CM_ SG_ 186 MessageCounter_0BA "Message counter signal for frame";
CM_ SG_ 186 IBS_CDPActive "Indicate CDP Control Active";
CM_ SG_ 186 IBS_CDPAvailable "EN: CDP Function Available";
CM_ SG_ 186 IBS_DTCActive "Drag Torque Control";
CM_ SG_ 187 Checksum_0BB "Checksum signal for frame";
CM_ SG_ 187 MessageCounter_0BB "Message counter signal for frame";
CM_ SG_ 187 IBS_SUBEPBworkingSts "EPB Status(Redundant EPB status)";
CM_ SG_ 187 IBS_SUBEPBFailureStatus "EPB failure status(Redundant EPB status)";
CM_ SG_ 187 IBS_SUBEPBControllerSts "Switchover status of EPB auxiliary controller";
CM_ SG_ 152 Checksum_098 "Checksum signal for frame";
CM_ SG_ 152 MessageCounter_098 "Message counter signal for frame";
CM_ SG_ 152 MCU_ActualSpeedValid "Motor actual speed valid status";
CM_ SG_ 152 MCU_ActTrqValid "Motor actual torque valid status";
CM_ SG_ 152 MCU_ActualTorque "the actual torque of motor";
CM_ SG_ 152 MCU_UdcCurr "the actual voltage of udclink";
CM_ SG_ 152 MCU_IsCurr "the actual current";
CM_ SG_ 152 MCU_ActualSpeed "the actual motor speed";
CM_ SG_ 243 MCU_OfsAl "the offset angle of motor";
CM_ SG_ 243 MCU_Isd "the actual d axle current of MCU";
CM_ SG_ 243 MCU_Isq "the actual q axle current of MCU";
CM_ SG_ 243 MCU_DmpCTrqCurr "the actual torque of damping control compensation";
CM_ SG_ 243 MCU_VCUWorkMode "the actual running mode of motor";
CM_ SG_ 243 MCU_BDmpCActv "the damping control enable flag of motor";
CM_ SG_ 243 MCU_StGateDrv "the gate drive status of MCU";
CM_ SG_ 594 MCU_TrqAbsMax "the maximum allowed torque of E-motor";
CM_ SG_ 594 MCU_TrqAbsMin "the minimum allowed torque of E-motor";
CM_ SG_ 594 MCU_StDischg "the discharge status";
CM_ SG_ 594 MCU_UT30Curr "the actual voltage of Tl30";
CM_ SG_ 594 MCU_UT15State "the active state of Tl15 KL15";
CM_ SG_ 594 MCU_ActUnfilteredRotSpd "Unfiltered motor speed";
CM_ SG_ 594 MCU_SpdMaxLimit "The maximum allowed speed of E-motor";
CM_ SG_ 595 Checksum_253 "Checksum signal for frame";
CM_ SG_ 595 MessageCounter_253 "Message counter signal for frame";
CM_ SG_ 595 MCU_FaultLevel "the failure code of E-motor which has the highest priority";
CM_ SG_ 929 MCU_HwVer "the version of hardware";
CM_ SG_ 928 MCU_CodeVer "the version of TC275 software code";
CM_ SG_ 928 MCU_DataVer "the version of TC275 software calibration data";
CM_ SG_ 928 MCU_CpldVer "the version of CPLD software";
CM_ SG_ 928 MCU_HvMcuVer "the version of Hv Mcu software";
CM_ SG_ 914 MCU_IGBTTempU "the temperature of U phase IGBT";
CM_ SG_ 914 MCU_IGBTTempV "the temperature of V phase IGBT";
CM_ SG_ 914 MCU_IGBTTempW "the temperature of W phase IGBT";
CM_ SG_ 914 MCU_IGBTTempMax "the temperature of Max phase IGBT";
CM_ SG_ 914 MCU_IGBTTempRiseU "the temperature rise of U phase IGBT";
CM_ SG_ 914 MCU_IGBTTempRiseV "the temperature rise of V phase IGBT";
CM_ SG_ 914 MCU_IGBTTempRiseW "the temperature rise of W phase IGBT";
CM_ SG_ 914 MCU_IGBTTempRiseMax "the temperature rise of Max phase IGBT";
CM_ SG_ 915 MCU_TempCurrCool "the temperature of coolant";
CM_ SG_ 915 MCU_TempCurrStr1 "the temperature of stator NTC1";
CM_ SG_ 915 MCU_TempCurrStr2 "the temperature of stator NTC2";
CM_ SG_ 915 MCU_TempCurrStrMax "the temperature of Max stator NTC";
CM_ SG_ 915 MCU_TempRiseCurrStr "the temperature of stator NTC1";
CM_ SG_ 915 MCU_TempStatus "The E-motor temperature state";
CM_ SG_ 578 POD_DCDC_HVInputVoltage "Voltage at high voltage side";
CM_ SG_ 578 POD_DCDC_WorkMode "State DCDC converter";
CM_ SG_ 578 POD_DCDC_LVOutputCurrent "Current on low voltage side";
CM_ SG_ 578 POD_DCDC_HVInputCurrent "Current at high voltage side";
CM_ SG_ 578 POD_DCDC_LVOutputVoltage "Voltage on low voltage side";
CM_ SG_ 770 POD_DCDC_FaultLevel "0x0: No Fault;
0x1: Minor faults.The drive performance of the whole vehicle has no influence on the parts, the output power is not limited, the function is affected to a certain extent, and the instrument alarm prompts. The component records the corresponding fault code
0x2: Recoverable malfunctions,Light the meter fault light and record the fault code. drive speed should be limited with 60km/h.the fault code of the faulty parts is recorded, limit LV power and the ICU lights up the system fault light and DCDC fault indicator.
0x3: Unrecoverable malfunctions,The function and performance of the whole vehicle are affected, drive speed should be limited with 60km/h.the fault code of the faulty parts is recorded, limit LV power and the ICU lights up the system fault light and DCDC fault indicator.";
CM_ SG_ 770 POD_DCDC_OutputCurrentHighFault "DCDC output overcurrent fault";
CM_ SG_ 770 POD_DCDC_InputVoltHighFault "DCDC input overvoltage fault";
CM_ SG_ 770 POD_DCDC_InputVoltLowFault "DCDC input undervoltage fault";
CM_ SG_ 770 POD_DCDC_OutputVoltHighFault "DCDC output overvoltage fault";
CM_ SG_ 770 POD_DCDC_OutputVoltLowFault "DCDC output undervoltage fault";
CM_ SG_ 770 POD_DCDC_Outputopencircuiterror "DCDC output open circuit error";
CM_ SG_ 770 POD_DCDC_Side2Overtempfault "DCDC Secordary side overtemperature fault";
CM_ SG_ 770 POD_DCDC_OutCurSensorFault "DCDC the low-side current sensor is faulty";
CM_ SG_ 770 POD_DCDC_OutputTempSensorFault "DCDC the low-voltage side temperature sensor is faulty";
CM_ SG_ 770 POD_DCDC_InternalFault "DCDC internal error";
CM_ SG_ 770 POD_DCDC_SecondarySideTemp "This signal is sent to TMS,according to this signal, TCU control the temporature of water";
CM_ SG_ 770 POD_DCDC_Maxoutputpower "DCDC maximum out put power at present condition";
CM_ SG_ 770 POD_DCDC_HVinputshortcircuit "DCDC HV input short circuit";
CM_ SG_ 770 POD_DCDC_LVoutputshortcircuit "DCDC LV output short circuit";
CM_ SG_ 581 POD_OBC_CPCurrentLimit "Maximum AC current of infrastructure signalled by charging station with Duty-Cycle on the CP-PWM-Signal.";
CM_ SG_ 581 POD_OBC_CCStatus "OBC CC status";
CM_ SG_ 581 POD_OBC_CPStatus "Feedback the connected status of CP to VCU";
CM_ SG_ 581 POD_OBC_CCCurrentLimit "Maximum AC current of vehicle plug and cable detected by the EV.
For different charging plugs and cables e.g. with lower current performance then the charging station there are seperate values of resistors (RC and R4) inside the charging plug";
CM_ SG_ 581 POD_OBC_CPFrequency "CP frequency";
CM_ SG_ 581 POD_OBC_WorkMode "Idle when OBC shut up & be able to send message /
Readywhen OBC finish init. & itself detec./Charging/
Faultwhen OBC Fault Level=Recoverable fault,stop output but not power down
/Level=Unrecoverable fault,stop output and pow.down
/Stopstop pow.down";
CM_ SG_ 581 POD_OBC_CPDuty "CP Duty";
CM_ SG_ 581 POD_OBC_EMLockState "Give feedback of EM lock status to VCU";
CM_ SG_ 581 POD_OBC_ChargCapacibility "single-phase or three-phase";
CM_ SG_ 581 POD_OBC_S2State "Give feedback of S2 status to VCU";
CM_ SG_ 581 POD_OBC_OBCMaxPermOutpCrrt "Report OBC Max Permit Output Current";
BA_DEF_ BO_  "SCP_FreshnessValueTxLength" INT 0 512;
BA_DEF_ BO_  "SCP_FreshnessValueLength" INT 0 512;
BA_DEF_ BO_  "SCP_FreshnessValueld" INT 0 65535;
BA_DEF_ BO_  "SCP_DataId" INT 0 65535;
BA_DEF_ BO_  "SCP_AuthinfoTxLength" INT 0 512;
BA_DEF_ BO_  "DiagConnection" INT 0 0;
BA_DEF_  "DBName" STRING ;
BA_DEF_  "BusType" STRING ;
BA_DEF_  "NmAsrWaitBusSleepTime" INT 0 65535;
BA_DEF_  "NmAsrTimeoutTime" INT 1 65535;
BA_DEF_  "NmAsrRepeatMessageTime" INT 0 65535;
BA_DEF_ BU_  "NmAsrNodeIdentifier" HEX 0 255;
BA_DEF_ BU_  "NmAsrNode" ENUM  "no","yes";
BA_DEF_  "NmAsrMessageCount" INT 1 256;
BA_DEF_ BU_  "NmAsrCanMsgReducedTime" INT 1 65535;
BA_DEF_  "NmAsrCanMsgCycleTime" INT 1 65535;
BA_DEF_  "NmAsrBaseAddress" HEX 0 2047;
BA_DEF_  "NmBaseAddress" HEX 1280 1407;
BA_DEF_  "NmMessageCount" INT 0 255;
BA_DEF_ BU_  "NodeLayerModules" STRING ;
BA_DEF_ BO_  "GenMsgSendType" ENUM  "Cyclic","Event","IfActive","CE","CA","NoMsgSendType";
BA_DEF_ BO_  "GenMsgCycleTime" INT 0 0;
BA_DEF_ BO_  "GenMsgCycleTimeFast" INT 0 0;
BA_DEF_ BO_  "GenMsgNrOfRepetition" INT 0 0;
BA_DEF_ BO_  "GenMsgDelayTime" INT 0 0;
BA_DEF_ BO_  "GenMsgILSupport" ENUM  "No","Yes";
BA_DEF_ BO_  "NmMessage" ENUM  "No","Yes";
BA_DEF_ BO_  "DiagState" ENUM  "No","Yes";
BA_DEF_ BO_  "DiagRequest" ENUM  "No","Yes";
BA_DEF_ BO_  "DiagResponse" ENUM  "No","Yes";
BA_DEF_ SG_  "GenSigSendType" ENUM  "Cyclic","OnChange","OnWrite","IfActive","OnChangeWithRepetition","OnWriteWithRepetition","IfActiveWithRepetition","NoSigSendType","NotUsed","NotUsed","NotUsed","NotUsed","NotUsed";
BA_DEF_ SG_  "GenSigStartValue" INT 0 0;
BA_DEF_ SG_  "GenSigInvalidValue" INT 0 0;
BA_DEF_ SG_  "SystemSignalLongSymbol" STRING ;
BA_DEF_DEF_  "SCP_FreshnessValueTxLength" 4;
BA_DEF_DEF_  "SCP_FreshnessValueLength" 48;
BA_DEF_DEF_  "SCP_FreshnessValueld" 0;
BA_DEF_DEF_  "SCP_DataId" 0;
BA_DEF_DEF_  "SCP_AuthinfoTxLength" 28;
BA_DEF_DEF_  "DiagConnection" 0;
BA_DEF_DEF_  "DBName" "";
BA_DEF_DEF_  "BusType" "CAN";
BA_DEF_DEF_  "NmAsrWaitBusSleepTime" 2000;
BA_DEF_DEF_  "NmAsrTimeoutTime" 2000;
BA_DEF_DEF_  "NmAsrRepeatMessageTime" 1500;
BA_DEF_DEF_  "NmAsrNodeIdentifier" 28;
BA_DEF_DEF_  "NmAsrNode" "yes";
BA_DEF_DEF_  "NmAsrMessageCount" 128;
BA_DEF_DEF_  "NmAsrCanMsgReducedTime" 320;
BA_DEF_DEF_  "NmAsrCanMsgCycleTime" 500;
BA_DEF_DEF_  "NmAsrBaseAddress" 1280;
BA_DEF_DEF_  "NmBaseAddress" 1280;
BA_DEF_DEF_  "NmMessageCount" 255;
BA_DEF_DEF_  "NodeLayerModules" "CANoeILNLVector.dll";
BA_DEF_DEF_  "GenMsgSendType" "Cyclic";
BA_DEF_DEF_  "GenMsgCycleTime" 0;
BA_DEF_DEF_  "GenMsgCycleTimeFast" 0;
BA_DEF_DEF_  "GenMsgNrOfRepetition" 0;
BA_DEF_DEF_  "GenMsgDelayTime" 0;
BA_DEF_DEF_  "GenMsgILSupport" "Yes";
BA_DEF_DEF_  "NmMessage" "No";
BA_DEF_DEF_  "DiagState" "No";
BA_DEF_DEF_  "DiagRequest" "No";
BA_DEF_DEF_  "DiagResponse" "No";
BA_DEF_DEF_  "GenSigSendType" "Cyclic";
BA_DEF_DEF_  "GenSigStartValue" 0;
BA_DEF_DEF_  "GenSigInvalidValue" 0;
BA_DEF_DEF_  "SystemSignalLongSymbol" "";
BA_ "DBName" "ATOM_CAN_Matrix_PT_V600_20250211";
BA_ "GenMsgCycleTime" BO_ 249 20;
BA_ "GenMsgSendType" BO_ 1937 5;
BA_ "GenMsgCycleTime" BO_ 151 20;
BA_ "GenMsgCycleTime" BO_ 918 1000;
BA_ "GenMsgCycleTime" BO_ 613 100;
BA_ "GenMsgCycleTime" BO_ 822 200;
BA_ "GenMsgCycleTime" BO_ 826 200;
BA_ "GenMsgCycleTime" BO_ 625 100;
BA_ "GenMsgCycleTime" BO_ 626 100;
BA_ "SCP_AuthinfoTxLength" BO_ 626 32;
BA_ "SCP_DataId" BO_ 626 4660;
BA_ "SCP_FreshnessValueld" BO_ 626 2;
BA_ "GenMsgCycleTime" BO_ 820 200;
BA_ "SCP_AuthinfoTxLength" BO_ 820 32;
BA_ "SCP_DataId" BO_ 820 4660;
BA_ "SCP_FreshnessValueld" BO_ 820 2;
BA_ "GenMsgCycleTime" BO_ 931 1000;
BA_ "GenMsgCycleTime" BO_ 934 1000;
BA_ "GenMsgCycleTime" BO_ 935 1000;
BA_ "GenMsgCycleTime" BO_ 938 1000;
BA_ "GenMsgCycleTime" BO_ 993 500;
BA_ "GenMsgCycleTime" BO_ 536 100;
BA_ "GenMsgCycleTime" BO_ 535 100;
BA_ "GenMsgCycleTime" BO_ 530 100;
BA_ "GenMsgCycleTime" BO_ 531 100;
BA_ "GenMsgCycleTime" BO_ 936 1000;
BA_ "GenMsgCycleTime" BO_ 937 1000;
BA_ "GenMsgCycleTime" BO_ 528 100;
BA_ "GenMsgCycleTime" BO_ 772 200;
BA_ "GenMsgCycleTime" BO_ 933 1000;
BA_ "GenMsgCycleTime" BO_ 992 500;
BA_ "GenMsgCycleTime" BO_ 193 20;
BA_ "GenMsgCycleTime" BO_ 194 20;
BA_ "GenMsgCycleTime" BO_ 532 100;
BA_ "GenMsgCycleTime" BO_ 533 100;
BA_ "GenMsgCycleTime" BO_ 771 200;
BA_ "GenMsgCycleTime" BO_ 932 1000;
BA_ "GenMsgCycleTime" BO_ 632 100;
BA_ "GenMsgDelayTime" BO_ 642 20;
BA_ "GenMsgNrOfRepetition" BO_ 642 3;
BA_ "GenMsgCycleTimeFast" BO_ 642 20;
BA_ "GenMsgCycleTime" BO_ 642 100;
BA_ "GenMsgSendType" BO_ 642 3;
BA_ "GenMsgCycleTime" BO_ 650 100;
BA_ "GenMsgDelayTime" BO_ 643 20;
BA_ "GenMsgNrOfRepetition" BO_ 643 3;
BA_ "GenMsgCycleTimeFast" BO_ 643 20;
BA_ "GenMsgCycleTime" BO_ 643 100;
BA_ "GenMsgSendType" BO_ 643 3;
BA_ "GenMsgCycleTime" BO_ 651 100;
BA_ "GenMsgDelayTime" BO_ 644 20;
BA_ "GenMsgNrOfRepetition" BO_ 644 3;
BA_ "GenMsgCycleTimeFast" BO_ 644 20;
BA_ "GenMsgCycleTime" BO_ 644 100;
BA_ "GenMsgSendType" BO_ 644 3;
BA_ "GenMsgDelayTime" BO_ 645 20;
BA_ "GenMsgNrOfRepetition" BO_ 645 3;
BA_ "GenMsgCycleTimeFast" BO_ 645 20;
BA_ "GenMsgCycleTime" BO_ 645 100;
BA_ "GenMsgSendType" BO_ 645 3;
BA_ "GenMsgCycleTime" BO_ 614 100;
BA_ "GenMsgCycleTime" BO_ 615 100;
BA_ "GenMsgCycleTime" BO_ 179 20;
BA_ "GenMsgCycleTime" BO_ 180 20;
BA_ "GenMsgCycleTime" BO_ 186 20;
BA_ "GenMsgCycleTime" BO_ 187 20;
BA_ "GenMsgCycleTime" BO_ 152 10;
BA_ "GenMsgCycleTime" BO_ 243 20;
BA_ "GenMsgCycleTime" BO_ 594 100;
BA_ "GenMsgCycleTime" BO_ 595 100;
BA_ "GenMsgCycleTime" BO_ 929 1000;
BA_ "GenMsgCycleTime" BO_ 928 1000;
BA_ "GenMsgCycleTime" BO_ 914 500;
BA_ "GenMsgCycleTime" BO_ 915 500;
BA_ "GenMsgCycleTime" BO_ 578 100;
BA_ "GenMsgCycleTime" BO_ 770 200;
BA_ "GenMsgCycleTime" BO_ 581 100;
BA_ "GenSigSendType" SG_ 1937 Uds_EPT_bootResponse_Byte7 2;
BA_ "GenSigSendType" SG_ 1937 Uds_EPT_bootResponse_Byte6 2;
BA_ "GenSigSendType" SG_ 1937 Uds_EPT_bootResponse_Byte5 2;
BA_ "GenSigSendType" SG_ 1937 Uds_EPT_bootResponse_Byte4 2;
BA_ "GenSigSendType" SG_ 1937 Uds_EPT_bootResponse_Byte3 2;
BA_ "GenSigSendType" SG_ 1937 Uds_EPT_bootResponse_Byte2 2;
BA_ "GenSigSendType" SG_ 1937 Uds_EPT_bootResponse_Byte1 2;
BA_ "GenSigSendType" SG_ 1937 Uds_EPT_bootResponse_Byte0 2;
BA_ "GenSigInvalidValue" SG_ 151 MessageCounter_097 15;
BA_ "GenSigStartValue" SG_ 151 ACU_CrashOutputStsValid 1;
BA_ "GenSigInvalidValue" SG_ 822 BCM_RLHSHumidSensorValue 255;
BA_ "GenSigInvalidValue" SG_ 822 BCM_RLHSTempSensorValue 255;
BA_ "GenSigInvalidValue" SG_ 822 BCM_RLHSTempDewPoint 2047;
BA_ "GenSigInvalidValue" SG_ 822 BCM_HUDBriRawVal 127;
BA_ "GenSigStartValue" SG_ 822 BCM_HUDBriRawVal 127;
BA_ "GenSigInvalidValue" SG_ 826 MessageCounter_33A 15;
BA_ "GenSigStartValue" SG_ 826 BCM_GearTimesSts 5;
BA_ "GenSigStartValue" SG_ 826 BCM_DomeLampBrightSts 1;
BA_ "GenSigStartValue" SG_ 826 BCM_PuddleLiReq 1;
BA_ "GenSigStartValue" SG_ 826 BCM_DomeLampAutoSts 1;
BA_ "GenSigStartValue" SG_ 826 BCM_WelLightshowOnOffSts 2;
BA_ "GenSigInvalidValue" SG_ 625 MessageCounter_271 15;
BA_ "GenSigInvalidValue" SG_ 625 BCM_PepsPowerMode 7;
BA_ "GenSigStartValue" SG_ 536 BMS_AverageCellTemp 255;
BA_ "GenSigStartValue" SG_ 536 BMS_MaxCellTemp 255;
BA_ "GenSigStartValue" SG_ 536 BMS_MinCellTemp 255;
BA_ "GenSigInvalidValue" SG_ 528 BMS_PosRelayStatus 3;
BA_ "GenSigInvalidValue" SG_ 528 BMS_PTCRelayStatus 3;
BA_ "GenSigInvalidValue" SG_ 528 BMS_NegRelayStatus 3;
BA_ "GenSigInvalidValue" SG_ 528 BMS_PreRelayStatus 3;
BA_ "GenSigStartValue" SG_ 528 BMS_PTC_WorkStatus 1;
BA_ "GenSigStartValue" SG_ 992 BMS_FeedEnergySts 255;
BA_ "GenSigStartValue" SG_ 992 BMS_DirveDiscSts 255;
BA_ "GenSigInvalidValue" SG_ 193 MessageCounter_0C1 15;
BA_ "GenSigInvalidValue" SG_ 193 BMS_WorkMode 7;
BA_ "GenSigStartValue" SG_ 771 BMS_AllowCellTemperature 255;
BA_ "GenSigStartValue" SG_ 771 BMS_TargetBatteryMaxCellTemp 255;
BA_ "GenSigStartValue" SG_ 771 BMS_TempInlet 255;
BA_ "GenSigStartValue" SG_ 771 BMS_Tempoutlet 255;
BA_ "GenSigStartValue" SG_ 771 BMS_FlowRate 255;
BA_ "GenSigInvalidValue" SG_ 632 MessageCounter_278 15;
BA_ "GenSigInvalidValue" SG_ 642 DCM_FL_DoorFLAngle 127;
BA_ "GenSigStartValue" SG_ 642 DCM_FL_DoorFLAngle 127;
BA_ "GenSigSendType" SG_ 642 DCM_FL_LinkageAvoidanceReq 4;
BA_ "GenSigInvalidValue" SG_ 650 MessageCounter_28A 15;
BA_ "GenSigInvalidValue" SG_ 650 DCM_FL_FRWndSwA 5;
BA_ "GenSigInvalidValue" SG_ 650 DCM_FL_RLWndSwA 5;
BA_ "GenSigInvalidValue" SG_ 650 DCM_FL_RRWndSwA 5;
BA_ "GenSigInvalidValue" SG_ 650 DCM_FL_LeftMirrorHorizontalPos 255;
BA_ "GenSigStartValue" SG_ 650 DCM_FL_LeftMirrorHorizontalPos 254;
BA_ "GenSigInvalidValue" SG_ 650 DCM_FL_LeftMirrorVerticalPos 255;
BA_ "GenSigStartValue" SG_ 650 DCM_FL_LeftMirrorVerticalPos 254;
BA_ "GenSigInvalidValue" SG_ 643 DCM_FR_DoorFRAngle 127;
BA_ "GenSigStartValue" SG_ 643 DCM_FR_DoorFRAngle 127;
BA_ "GenSigSendType" SG_ 643 DCM_FR_LinkageAvoidanceReq 4;
BA_ "GenSigStartValue" SG_ 651 DCM_FR_AmbientTemperature 70;
BA_ "GenSigInvalidValue" SG_ 651 DCM_FR_RightMirrorHorizontalPos 255;
BA_ "GenSigStartValue" SG_ 651 DCM_FR_RightMirrorHorizontalPos 254;
BA_ "GenSigInvalidValue" SG_ 651 DCM_FR_RightMirrorVerticalPos 255;
BA_ "GenSigStartValue" SG_ 651 DCM_FR_RightMirrorVerticalPos 254;
BA_ "GenSigInvalidValue" SG_ 644 DCM_RL_DoorRLAngle 127;
BA_ "GenSigStartValue" SG_ 644 DCM_RL_DoorRLAngle 127;
BA_ "GenSigSendType" SG_ 644 DCM_RL_LinkageAvoidanceReq 4;
BA_ "GenSigInvalidValue" SG_ 645 DCM_RR_DoorRRAngle 127;
BA_ "GenSigStartValue" SG_ 645 DCM_RR_DoorRRAngle 127;
BA_ "GenSigSendType" SG_ 645 DCM_RR_LinkageAvoidanceReq 4;
BA_ "GenSigInvalidValue" SG_ 615 EVCOM_CompBusVolt 511;
BA_ "GenSigInvalidValue" SG_ 179 MessageCounter_0B3 15;
BA_ "GenSigInvalidValue" SG_ 179 IBS_EPBFunctionLamp 3;
BA_ "GenSigInvalidValue" SG_ 180 MessageCounter_0B4 15;
BA_ "SystemSignalLongSymbol" SG_ 180 IBS_VCU_DecelerationRequest_Avai "IBS_VCU_DecelerationRequest_Available";
BA_ "GenSigInvalidValue" SG_ 186 MessageCounter_0BA 15;
BA_ "GenSigInvalidValue" SG_ 187 MessageCounter_0BB 15;
BA_ "GenSigInvalidValue" SG_ 152 MessageCounter_098 15;
BA_ "GenSigInvalidValue" SG_ 152 MCU_ActualTorque 2047;
BA_ "GenSigStartValue" SG_ 152 MCU_ActualTorque 1023;
BA_ "GenSigInvalidValue" SG_ 152 MCU_UdcCurr 1023;
BA_ "GenSigInvalidValue" SG_ 152 MCU_IsCurr 2047;
BA_ "GenSigStartValue" SG_ 152 MCU_IsCurr 1023;
BA_ "GenSigInvalidValue" SG_ 152 MCU_ActualSpeed 65535;
BA_ "GenSigStartValue" SG_ 152 MCU_ActualSpeed 32767;
BA_ "GenSigInvalidValue" SG_ 243 MCU_OfsAl 4095;
BA_ "GenSigInvalidValue" SG_ 243 MCU_Isd 4095;
BA_ "GenSigInvalidValue" SG_ 243 MCU_Isq 4095;
BA_ "GenSigInvalidValue" SG_ 243 MCU_DmpCTrqCurr 255;
BA_ "GenSigInvalidValue" SG_ 243 MCU_StGateDrv 3;
BA_ "GenSigStartValue" SG_ 243 MCU_StGateDrv 1;
BA_ "GenSigInvalidValue" SG_ 594 MCU_TrqAbsMax 2047;
BA_ "GenSigStartValue" SG_ 594 MCU_TrqAbsMax 1023;
BA_ "GenSigInvalidValue" SG_ 594 MCU_TrqAbsMin 2047;
BA_ "GenSigStartValue" SG_ 594 MCU_TrqAbsMin 1023;
BA_ "GenSigInvalidValue" SG_ 594 MCU_UT30Curr 63;
BA_ "GenSigInvalidValue" SG_ 594 MCU_ActUnfilteredRotSpd 65535;
BA_ "GenSigStartValue" SG_ 594 MCU_ActUnfilteredRotSpd 32767;
BA_ "GenSigInvalidValue" SG_ 594 MCU_SpdMaxLimit 65535;
BA_ "GenSigStartValue" SG_ 594 MCU_SpdMaxLimit 32767;
BA_ "GenSigInvalidValue" SG_ 595 MessageCounter_253 15;
BA_ "GenSigInvalidValue" SG_ 914 MCU_IGBTTempU 255;
BA_ "GenSigInvalidValue" SG_ 914 MCU_IGBTTempV 255;
BA_ "GenSigInvalidValue" SG_ 914 MCU_IGBTTempW 255;
BA_ "GenSigInvalidValue" SG_ 914 MCU_IGBTTempMax 255;
BA_ "GenSigInvalidValue" SG_ 914 MCU_IGBTTempRiseU 255;
BA_ "GenSigInvalidValue" SG_ 914 MCU_IGBTTempRiseV 255;
BA_ "GenSigInvalidValue" SG_ 914 MCU_IGBTTempRiseW 255;
BA_ "GenSigInvalidValue" SG_ 914 MCU_IGBTTempRiseMax 255;
BA_ "GenSigInvalidValue" SG_ 915 MCU_TempCurrCool 255;
BA_ "GenSigStartValue" SG_ 915 MCU_TempCurrCool 255;
BA_ "GenSigInvalidValue" SG_ 915 MCU_TempCurrStr1 255;
BA_ "GenSigStartValue" SG_ 915 MCU_TempCurrStr1 255;
BA_ "GenSigInvalidValue" SG_ 915 MCU_TempCurrStr2 255;
BA_ "GenSigStartValue" SG_ 915 MCU_TempCurrStr2 255;
BA_ "GenSigInvalidValue" SG_ 915 MCU_TempCurrStrMax 255;
BA_ "GenSigStartValue" SG_ 915 MCU_TempCurrStrMax 255;
BA_ "GenSigInvalidValue" SG_ 915 MCU_TempRiseCurrStr 255;
BA_ "GenSigStartValue" SG_ 770 POD_DCDC_SecondarySideTemp 255;
BA_ "GenSigInvalidValue" SG_ 581 POD_OBC_CCStatus 10;
BA_ "GenSigStartValue" SG_ 581 POD_OBC_S2State 1;
VAL_ 249 IVI_BulbCheckSts 1 "BulbCheck" 0 "Not BulbCheck" ;
VAL_ 249 IVI_SFIabnormalSts 1 "Abnormal" 0 "Normal" ;
VAL_ 249 IVI_SFIDippedBeamSet 3 "Reserved" 2 "Reserved" 1 "On" 0 "NO Request" ;
VAL_ 151 MessageCounter_097 15 "Invalid" ;
VAL_ 151 ACU_CrashOutputSts 0 "No Crash" 1 "Rollover" 2 "BPT Crash" 3 "Rollover + BPT" 4 "Front Crash" 5 "Rollover + Front" 6 "BPT+Front" 7 "Rollover+BPT+Front" 8 "Side Crash" 9 "Rollover+Side" 10 "BPT+Side" 11 "Rollover+BPT+Side" 12 "Front+Side" 13 "Rollover+Front+Side" 14 "BPT+Front+Side" 15 "Rollover+BPT+Front+Side" 16 "Rear Crash" 17 "Rollover+Rear" 18 "BPT+Rear" 19 "Rollover+BPT+Rear" 20 "Front+Rear" 21 "Rollover+Front+Rear" 22 "BPT+Front+Rear" 23 "Rollover+BPT+Front+Rear" 24 "Side+Rear" 25 "Rollover+Side+Rear" 26 "BPT+Side+Rear" 27 "Rollover+BPT+Side+Rear" 28 "Front+Side+Rear" 29 "Rollover+Front+Side+Rear" 30 "BPT+Front+Side+Rear" 31 "Rollover+BPT+Front+Side+Rear" ;
VAL_ 151 ACU_CrashOutputStsValid 0 "INVALID" 1 "VALID" ;
VAL_ 151 ACU_DriverSeatBeltSts 0 "UNTIED" 1 "TIED" ;
VAL_ 151 ACU_DriverSeatBeltStsValid 0 "INVALID" 1 "VALID" ;
VAL_ 151 ACU_PassengerSeatBeltSts 0 "UNTIED" 1 "TIED" ;
VAL_ 151 ACU_PassengerSeatBeltStsValid 0 "INVALID" 1 "VALID" ;
VAL_ 151 ACU_PassengerSts 0 "UNOCCUPIED" 1 "OCCUPIED" ;
VAL_ 151 ACU_SecondLeftSeatBeltSts 0 "UNTIED" 1 "TIED" ;
VAL_ 151 ACU_RLSeatBeltStatusValid 0 "INVALID" 1 "VALID" ;
VAL_ 151 ACU_SecondLeftSts 0 "UNOCCUPIED" 1 "OCCUPIED" ;
VAL_ 151 ACU_SecondRightSeatBeltSts 0 "UNTIED" 1 "TIED" ;
VAL_ 151 ACU_RRSeatBeltStatusValid 0 "INVALID" 1 "VALID" ;
VAL_ 151 ACU_SecondRightSts 0 "UNOCCUPIED" 1 "OCCUPIED" ;
VAL_ 151 ACU_PassengerAirbagSts 0 "RESERVED" 1 "Disabled" 2 "Enabled" 3 "RESERVED" ;
VAL_ 151 ACU_DriverWarningLampSts 0 "OFF" 1 "ON" 2 "FLASH" ;
VAL_ 151 ACU_PassengerWarningLampSts 0 "OFF" 1 "ON" 2 "FLASH" ;
VAL_ 151 ACU_WarningLampSts 0 "OFF" 1 "ON" 2 "FLASH" ;
VAL_ 918 ADCU_TemperatureSts 0 "No error" 1 "Normal" 2 "Overheat" 3 "Error" ;
VAL_ 613 APTC_HVPowerUpReq 0 "APTC OK" 1 "APTC failure" ;
VAL_ 613 APTC_HeatingFaltStatus 0 "no error" 1 "error" ;
VAL_ 613 APTC_DriveFaltStatus 0 "no error" 1 "error" ;
VAL_ 613 APTC_LostCommuFaltStatus 0 "no error" 1 "TCU signal losted" ;
VAL_ 613 APTC_IGBTFaltStatus 0 "no error" 1 "IGBT1 SHORT" 2 "IGBT2 SHORT" 3 "BOTH SHORT" ;
VAL_ 613 APTC_Core1TempSensorFaltStatus 0 "no error" 1 "L sensor open" 2 "sensor short" 3 "overheating" ;
VAL_ 613 APTC_OverCurrentFault 0 "No Error" 1 "Error" ;
VAL_ 613 APTC_LowVoltageStatus 0 "Low Voltage Normal" 1 "Low Voltage Under" 2 "Low Voltage Over" 3 "Reserve" ;
VAL_ 613 APTC_HighVoltageStatus 0 "High Voltage Normal" 1 "High Voltage Under" 2 "High Voltage Over" ;
VAL_ 613 APTC_OverLoadStatus 0 "No Error" 1 "Left APTC OverLoad" 2 "Right APTC Overload" 3 "Both APTC Overload" ;
VAL_ 613 APTC_IGBTTempSensorStatus 0 "No Error" 1 "IGBT Temp Sensor Short" 2 "IGBT Temp Sensor OverTemp" 3 "IGBT Temp Sensor Open" ;
VAL_ 613 APTC_PCBTempSensorStatus 0 "No Error" 1 "PCB Temp Sensor Short" 2 "PCB Temp Sensor OverTemp" 3 "PCB Temp Sensor Open" ;
VAL_ 613 APTC_Core2TempSensorFaltStatus 0 "no error" 1 "R sensor open" 2 "sensor short" 3 "overheating" ;
VAL_ 822 BCM_HUDBriUnit 0 "1 lux" 1 "10 lux" 2 "100 lux" 3 "1000 lux" ;
VAL_ 826 MessageCounter_33A 15 "Invalid" ;
VAL_ 826 BCM_GearTimesSts 0 "0" 1 "1" 2 "2" 3 "3" 4 "4" 5 "5" ;
VAL_ 826 BCM_ChrgFlapLockSts 0 "Locked" 1 "Unlocked" ;
VAL_ 826 BCM_FRSeatBeltRemindReq 0 "No request" 1 "First level reminder" 2 "Second level reminder" 3 "Reserved" ;
VAL_ 826 BCM_FLSeatBeltRemindReq 0 "No request" 1 "First level reminder" 2 "Second level reminder" 3 "Reserved" ;
VAL_ 826 BCM_KeyNotInCarRemind 0 "No Warning" 1 "Warning" ;
VAL_ 826 BCM_RRSeatBeltRemindReq 0 "No request" 1 "First level reminder" 2 "Second level reminder" 3 "Reserved" ;
VAL_ 826 BCM_RLSeatBeltRemindReq 0 "No request" 1 "First level reminder" 2 "Second level reminder" 3 "Reserved" ;
VAL_ 826 BCM_WiperServiceSts 0 "OFF" 1 "ON" ;
VAL_ 826 BCM_AutoCloseWinFunSts 0 "No Active" 1 "Active" ;
VAL_ 826 BCM_DomeLampBrightSts 0 "100%" 1 "50%" ;
VAL_ 826 BCM_PuddleLiReq 0 "Reserved" 1 "Off" 2 "On" ;
VAL_ 826 BCM_DomeLampAutoSts 0 "Non-auto set" 1 "Door open auto set" 2 "Door close auto set" ;
VAL_ 826 BCM_FrontWiperModeSts 0 "OFF" 1 "AUTO" 2 "Low speed" 3 "High speed" 4 "Intermittent" 5 "Reserved" ;
VAL_ 826 BCM_WiperWorkingSts 0 "OFF" 1 "Low speed" 2 "High speed" ;
VAL_ 826 BCM_WelLightshowOnOffSts 0 "Reserved" 1 "OFF" 2 "ON" ;
VAL_ 625 MessageCounter_271 15 "Invalid" ;
VAL_ 625 BCM_PepsPowerMode 0 "Default" 1 "OFF" 2 "Local ON" 3 "Reserve" 4 "Reserve" 5 "Reserve" 6 "Reserve" 7 "Invalid" ;
VAL_ 625 BCM_PowerOffDisplayReq 0 "No Request" 1 "Req_Power off" ;
VAL_ 626 BCM_Immo_State 0 "Disable immo" 1 "Enable immo" ;
VAL_ 820 BCM_AntiTheftSts 0 "DISARMED" 1 "ARMED" 2 "ALARM" 3 "HALF_ARMED" ;
VAL_ 820 BCM_AlarmedRemind 0 "No Warning" 1 "Warning" ;
VAL_ 820 BCM_ImmobilizingRemind 0 "No worning" 1 "Please stop" 2 "Immobilizing" 3 "Reserved" ;
VAL_ 934 BMS_BatType 1 "lead-acid battery" 2 "Ni-MH battery" 3 "Lithium iron phosphate battery" 4 "Lithium manganate battery" 5 "Lithium cobalt oxide battery" 6 "Ternary material battery" 7 "Polymer lithium ion battery" 8 "Lithium titanate battery" 9 "Reserved" 10 "Reserved" 11 "Reserved" 12 "Reserved" 13 "Reserved" 14 "Reserved" 15 "Reserved" 16 "Reserved" 17 "Reserved" 18 "Reserved" 19 "Reserved" 20 "Reserved" 21 "Reserved" 22 "Reserved" 23 "Reserved" 24 "Reserved" 25 "Reserved" 26 "Reserved" 27 "Reserved" 28 "Reserved" 29 "Reserved" 30 "Reserved" 31 "Reserved" 32 "Reserved" 33 "Reserved" 34 "Reserved" 35 "Reserved" 36 "Reserved" 37 "Reserved" 38 "Reserved" 39 "Reserved" 40 "Reserved" 41 "Reserved" 42 "Reserved" 43 "Reserved" 44 "Reserved" 45 "Reserved" 46 "Reserved" 47 "Reserved" 48 "Reserved" 49 "Reserved" 50 "Reserved" 51 "Reserved" 52 "Reserved" 53 "Reserved" 54 "Reserved" 55 "Reserved" 56 "Reserved" 57 "Reserved" 58 "Reserved" 59 "Reserved" 60 "Reserved" 61 "Reserved" 62 "Reserved" 63 "Reserved" 64 "Reserved" 65 "Reserved" 66 "Reserved" 67 "Reserved" 68 "Reserved" 69 "Reserved" 70 "Reserved" 71 "Reserved" 72 "Reserved" 73 "Reserved" 74 "Reserved" 75 "Reserved" 76 "Reserved" 77 "Reserved" 78 "Reserved" 79 "Reserved" 80 "Reserved" 81 "Reserved" 82 "Reserved" 83 "Reserved" 84 "Reserved" 85 "Reserved" 86 "Reserved" 87 "Reserved" 88 "Reserved" 89 "Reserved" 90 "Reserved" 91 "Reserved" 92 "Reserved" 93 "Reserved" 94 "Reserved" 95 "Reserved" 96 "Reserved" 97 "Reserved" 98 "Reserved" 99 "Reserved" 100 "Reserved" 101 "Reserved" 102 "Reserved" 103 "Reserved" 104 "Reserved" 105 "Reserved" 106 "Reserved" 107 "Reserved" 108 "Reserved" 109 "Reserved" 110 "Reserved" 111 "Reserved" 112 "Reserved" 113 "Reserved" 114 "Reserved" 115 "Reserved" 116 "Reserved" 117 "Reserved" 118 "Reserved" 119 "Reserved" 120 "Reserved" 121 "Reserved" 122 "Reserved" 123 "Reserved" 124 "Reserved" 125 "Reserved" 126 "Reserved" 127 "Reserved" 128 "Reserved" 129 "Reserved" 130 "Reserved" 131 "Reserved" 132 "Reserved" 133 "Reserved" 134 "Reserved" 135 "Reserved" 136 "Reserved" 137 "Reserved" 138 "Reserved" 139 "Reserved" 140 "Reserved" 141 "Reserved" 142 "Reserved" 143 "Reserved" 144 "Reserved" 145 "Reserved" 146 "Reserved" 147 "Reserved" 148 "Reserved" 149 "Reserved" 150 "Reserved" 151 "Reserved" 152 "Reserved" 153 "Reserved" 154 "Reserved" 155 "Reserved" 156 "Reserved" 157 "Reserved" 158 "Reserved" 159 "Reserved" 160 "Reserved" 161 "Reserved" 162 "Reserved" 163 "Reserved" 164 "Reserved" 165 "Reserved" 166 "Reserved" 167 "Reserved" 168 "Reserved" 169 "Reserved" 170 "Reserved" 171 "Reserved" 172 "Reserved" 173 "Reserved" 174 "Reserved" 175 "Reserved" 176 "Reserved" 177 "Reserved" 178 "Reserved" 179 "Reserved" 180 "Reserved" 181 "Reserved" 182 "Reserved" 183 "Reserved" 184 "Reserved" 185 "Reserved" 186 "Reserved" 187 "Reserved" 188 "Reserved" 189 "Reserved" 190 "Reserved" 191 "Reserved" 192 "Reserved" 193 "Reserved" 194 "Reserved" 195 "Reserved" 196 "Reserved" 197 "Reserved" 198 "Reserved" 199 "Reserved" 200 "Reserved" 201 "Reserved" 202 "Reserved" 203 "Reserved" 204 "Reserved" 205 "Reserved" 206 "Reserved" 207 "Reserved" 208 "Reserved" 209 "Reserved" 210 "Reserved" 211 "Reserved" 212 "Reserved" 213 "Reserved" 214 "Reserved" 215 "Reserved" 216 "Reserved" 217 "Reserved" 218 "Reserved" 219 "Reserved" 220 "Reserved" 221 "Reserved" 222 "Reserved" 223 "Reserved" 224 "Reserved" 225 "Reserved" 226 "Reserved" 227 "Reserved" 228 "Reserved" 229 "Reserved" 230 "Reserved" 231 "Reserved" 232 "Reserved" 233 "Reserved" 234 "Reserved" 235 "Reserved" 236 "Reserved" 237 "Reserved" 238 "Reserved" 239 "Reserved" 240 "Reserved" 241 "Reserved" 242 "Reserved" 243 "Reserved" 244 "Reserved" 245 "Reserved" 246 "Reserved" 247 "Reserved" 248 "Reserved" 249 "Reserved" 250 "Reserved" 251 "Reserved" 252 "Reserved" 253 "Reserved" 254 "Reserved" 255 "Reserved" ;
VAL_ 531 BMS_DCChgMode 0 "Ready" 1 "Constant voltage" 2 "Constant current" ;
VAL_ 531 BMS_AbortAchiveSingleVolt 0 "Not reached" 1 "Reached" 2 "Untrustable" ;
VAL_ 531 BMS_AbortAchiveTotalVolt 0 "Not reached" 1 "Reached" 2 "Untrustable" ;
VAL_ 531 BMS_AbortFaultBMSTemp 0 "Normal" 1 "Over temp" 2 "Untrustable" ;
VAL_ 531 BMS_AbortFaultBatteryTemp 0 "Normal" 1 "Over temp" 2 "Untrustable" ;
VAL_ 531 BMS_AbortErrorCurrent 0 "Normal" 1 "Over current" 2 "Untrustable" ;
VAL_ 531 BMS_AbortAchivesetValue 0 "Not reached" 1 "Reached" 2 "Untrustable" ;
VAL_ 531 BMS_AbortErrorVoltage 0 "Normal" 1 "Abnormal" 2 "Untrustable" ;
VAL_ 531 BMS_ChagComplete 0 "Normal Completion" 1 "Abnormal completion" 2 "Untrustable" 3 "During Charging" ;
VAL_ 531 BMS_ChargeRequest 0 "Invalid" 1 "Heat Request only" 2 "Heat And Charge Request" 3 "Charge Only" 4 "Cool And Charge Request" ;
VAL_ 528 BMS_PosRelayStatus 0 "Reserved" 1 "Closed" 2 "Opened" 3 "Signal Invalid" ;
VAL_ 528 BMS_PTCRelayStatus 0 "Reserved" 1 "Closed" 2 "Opened" 3 "Signal Invalid" ;
VAL_ 528 BMS_NegRelayStatus 0 "Reserved" 1 "Closed" 2 "Opened" 3 "Signal Invalid" ;
VAL_ 528 BMS_PreRelayStatus 0 "Reserved" 1 "Closed" 2 "Opened" 3 "Signal Invalid" ;
VAL_ 772 BMS_ErrorCellOverVolt 0 "Normal" 1 "Fault Level1" 2 "Fault Level2" 3 "Fault Level3" ;
VAL_ 772 BMS_ErrorCellUnderVolt 0 "Normal" 1 "Fault Level1" 2 "Fault Level2" 3 "Fault Level3" ;
VAL_ 772 BMS_ErrorCellHighTemp 0 "Normal" 1 "Fault Level1" 2 "Fault Level2" 3 "Fault Level3" ;
VAL_ 772 BMS_ErrorCellLowTemp 0 "Normal" 1 "Fault Level1" 2 "Fault Level2" 3 "Fault Level3" ;
VAL_ 772 BMS_ErrorBattOverVolt 0 "Normal" 1 "Fault Level1" 2 "Fault Level2" 3 "Fault Level3" ;
VAL_ 772 BMS_ErrorBattUnderVolt 0 "Normal" 1 "Fault Level1" 2 "Fault Level2" 3 "Fault Level3" ;
VAL_ 772 BMS_ErrorChaCurrentOver 0 "Normal" 1 "Fault Level1" 2 "Fault Level2" 3 "Fault Level3" ;
VAL_ 772 BMS_ErrorDisChaCurrentOver 0 "Normal" 1 "Fault Level1" 2 "Fault Level2" 3 "Fault Level3" ;
VAL_ 772 BMS_ErrorBSUOffline 0 "Normal" 1 "Fault" ;
VAL_ 772 BMS_ErrorLeakCurrent 0 "Normal" 1 "Fault Level1" 2 "Fault Level2" 3 "Fault Level3" ;
VAL_ 772 BMS_ErrorCellVoltDiff 0 "Normal" 1 "Fault Level1" 2 "Fault Level2" 3 "Fault Level3" ;
VAL_ 772 BMS_ErrorCellTempDiff 0 "Normal" 1 "Fault Level1" 2 "Fault Level2" 3 "Fault Level3" ;
VAL_ 772 BMS_ErrorBatVolt 0 "Normal" 1 "Fault Level1" 2 "Fault Level2" 3 "Fault Level3" ;
VAL_ 772 BMS_ErrorHallOffline 0 "Normal" 1 "Fault" ;
VAL_ 772 BMS_ErrorCellVoltOffline 0 "Normal" 1 "Fault" ;
VAL_ 772 BMS_ErrorCellTempOffline 0 "Normal" 1 "Fault" ;
VAL_ 772 BMS_ErrorPreChaFailed 0 "Normal" 1 "Fault" ;
VAL_ 772 BMS_ErrorRelay 0 "Normal" 1 "Fault" ;
VAL_ 772 BMS_ErrorBSUBalance 0 "Normal" 1 "Fault" ;
VAL_ 772 BMS_ErrorLowSoc 0 "Normal" 1 "Fault Level1" 2 "Fault Level2" 3 "Fault Level3" ;
VAL_ 772 BMS_ErrorHighSoc 0 "Normal" 1 "Fault" ;
VAL_ 772 BMS_ErrorSoCJump_RM 0 "Normal" 1 "Fault" ;
VAL_ 772 BMS_ErrorHVIL 0 "Normal" 1 "Fault" ;
VAL_ 772 BMS_ErrorEmergencyOffCrash 0 "Normal" 1 "Fault" ;
VAL_ 772 BMS_ErrorSystemsMatch 0 "Normal" 1 "Fault" ;
VAL_ 772 BMS_ErrorSmoke 0 "Normal" 1 "Fault" ;
VAL_ 772 BMS_ErrorLeakDet 0 "Normal" 1 "Fault" ;
VAL_ 772 BMS_ThermalRunawayFault 0 "Normal" 1 "Fault" ;
VAL_ 193 MessageCounter_0C1 15 "Invalid" ;
VAL_ 193 BMS_ErrorIsolationSingleLow 0 "Normal" 1 "Fault Level1" 2 "Fault Level2" 3 "Fault Level3" ;
VAL_ 193 BMS_WorkMode 0 "Initialize" 1 "Standby" 2 "Running" 3 "DC charge" 4 "AC charge" 5 "Discharge" 6 "Error" 7 "Invalid" ;
VAL_ 193 BMS_BalancingStatus 0 "stop" 1 "active" ;
VAL_ 193 BMS_InsulationDetectionStatus 0 "stop;" 1 "active;" ;
VAL_ 193 BMS_HVinterlockState 0 "Normal" 1 "Fault" ;
VAL_ 193 BMS_ThrmlRunawayFault 0 "Normal" 1 "Fault" ;
VAL_ 193 BMS_PreCharge 0 "Not precharge" 1 "Precharging" 2 "Precharge finished" 3 "Precharge failed" ;
VAL_ 193 BMS_ChargeStatus 0 "Not charging" 1 "Heat only" 2 "Charge and heat(DC)" 3 "Charge and heat(AC)" 4 "Charge only(DC)" 5 "Charge only(AC)" 6 "Charge hold" 7 "Charge stop" ;
VAL_ 193 BMS_RunHeatStatus 0 "Running heat" 1 "Target heat" 2 "App heat" 3 "Running cool" 4 "not heat not cool" ;
VAL_ 193 BMS_ErrorLevel 0 "Normal" 1 "level1" 2 "level2" 3 "level3" 4 "level4" ;
VAL_ 771 BMS_CoolCommand 0 "Not cooling" 1 "Reserved" 2 "Charge and cool(DC)" 3 "Charge and cool(AC)" 4 "Running cool" 5 "Keep cool" 6 "Reserved" 7 "Target cool" ;
VAL_ 771 BMS_HeatCommand 0 "Not heat" 1 "Preheating" 2 "Charge and heat(DC)" 3 "Charge and heat(AC)" 4 "Running heat" 5 "Keep warm" 6 "Reserved" 7 "Target heat" ;
VAL_ 771 BMS_KeepWarmRequest 0 "Not Request" 1 "Request" ;
VAL_ 771 BMS_KeepWarmStatus 0 "Init" 1 "OFF" 2 "ON" ;
VAL_ 771 BMS_RTC_Request 0 "No request" 1 "Request" ;
VAL_ 771 BMS_BalanceCommand 0 "No request" 1 "Request" ;
VAL_ 932 BMS_BatProRights 0 "lease" 1 "Buy" ;
VAL_ 632 MessageCounter_278 15 "Invalid" ;
VAL_ 632 CGW_VehicleState 0 "Fully sleep" 1 "Invisible awake-CANwakeup" 2 "Reserve" 3 "Reserve" 4 "Invisible awake-OnlyHVon" 5 "Standby-Normal" 6 "Standby-OnlyLVon" 7 "Drive-Normal" 8 "Drive-LVFault" ;
VAL_ 642 DCM_FL_DoorFLLockSts 0 "Locked" 1 "Unlocked" ;
VAL_ 642 DCM_FL_FLPESwitchReq 0 "Not pressed" 1 "Pressed" ;
VAL_ 642 DCM_FL_DoorObstacleSts 0 "Normal" 1 "Outer obstacle" ;
VAL_ 642 DCM_FL_DoorAntiPinchSts 0 "Normal" 1 "Anti pinch" ;
VAL_ 642 DCM_FL_ElectricDoorMovementSts 0 "FullyClosed" 1 "FullyOpened" 2 "Opening" 3 "Closing" 4 "Stoped" 5 "Revserved" 6 "Revserved" 7 "Revserved" ;
VAL_ 642 DCM_FL_LinkageAvoidanceReq 0 "No request" 1 "Close" 2 "Open" 3 "Stop" ;
VAL_ 642 DCM_FL_InsideSwitchReq 0 "Not pressed" 1 "Pressed" ;
VAL_ 642 DCM_FL_WindowSts 0 "stopped" 1 "Auto Up moving" 2 "Manual Up moving" 3 "Auto Down moving" 4 "Manual Down moving" 5 "Pinch Reversing" ;
VAL_ 642 DCM_FL_PWM_POS_STS 0 "Bottom stall" 1 "No stall" 2 "Top stall" 3 "Top soft stop" 4 "Bottom soft stop" ;
VAL_ 642 DCM_FL_GLASS_LOCATION 0 "0%" 1 "5%" 2 "10%" 3 "15%" 4 "20%" 5 "25%" 6 "30%" 7 "35%" 8 "40%" 9 "45%" 10 "50%" 11 "55%" 12 "60%" 13 "65%" 14 "70%" 15 "75%" 16 "80%" 17 "85%" 18 "90%" 19 "95%" 20 "100%" ;
VAL_ 642 DCM_FL_FrontDoorAngleFeedback 0 "75°" 1 "35°" ;
VAL_ 650 MessageCounter_28A 15 "Invalid" ;
VAL_ 650 DCM_FL_DoorFLSts 0 "Closed" 1 "Opened" ;
VAL_ 650 DCM_FL_FRWndSwA 0 "Off switch" 1 "manually press the window lift switch" 2 "automatically press the window lift switch" 3 "manually press the window drop switch" 4 "automatically press the window drop switch" 5 "Invalid" ;
VAL_ 650 DCM_FL_RLWndSwA 0 "Off switch" 1 "manually press the window lift switch" 2 "automatically press the window lift switch" 3 "manually press the window drop switch" 4 "automatically press the window drop switch" 5 "Invalid" ;
VAL_ 650 DCM_FL_RRWndSwA 0 "Off switch" 1 "manually press the window lift switch" 2 "automatically press the window lift switch" 3 "manually press the window drop switch" 4 "automatically press the window drop switch" 5 "Invalid" ;
VAL_ 650 DCM_FL_MirrorAutoTurnDownSts 0 "Disable" 1 "Enable" ;
VAL_ 650 DCM_FL_MirrorAutoFoldUnfoldSts 0 "Disable" 1 "Enable" ;
VAL_ 650 DCM_FL_RearmirrorHeatingSts 0 "OFF" 1 "ON" ;
VAL_ 650 DCM_FL_MirrorFold_UnfoldSts 0 "Unfold" 1 "Fold" ;
VAL_ 643 DCM_FR_DoorFRLockSts 0 "Locked" 1 "Unlocked" ;
VAL_ 643 DCM_FR_FRPESwitchReq 0 "Not pressed" 1 "Pressed" ;
VAL_ 643 DCM_FR_DoorAntiPinchSts 0 "Normal" 1 "Anti pinch" ;
VAL_ 643 DCM_FR_DoorObstacleSts 0 "Normal" 1 "Outer obstacle" ;
VAL_ 643 DCM_FR_ElectricDoorMovementSts 0 "FullyClosed" 1 "FullyOpened" 2 "Opening" 3 "Closing" 4 "Stoped" 5 "Revserved" 6 "Revserved" 7 "Revserved" ;
VAL_ 643 DCM_FR_LinkageAvoidanceReq 0 "NO Request" 1 "Close" 2 "Open" 3 "Stop" ;
VAL_ 643 DCM_FR_InsideSwitchReq 0 "Not pressed" 1 "Pressed" ;
VAL_ 643 DCM_FR_WindowSts 0 "Stopped" 1 "Auto Up moving" 2 "Manual Up moving" 3 "Auto Down moving" 4 "Manual Down moving" 5 "Pinch Reversing" ;
VAL_ 643 DCM_FR_PWM_POS_STS 0 "Bottom stall" 1 "No stall" 2 "Top stall" 3 "Top soft stop" 4 "Bottom soft stop" ;
VAL_ 643 DCM_FR_GLASS_LOCATION 0 "0%" 1 "5%" 2 "10%" 3 "15%" 4 "20%" 5 "25%" 6 "30%" 7 "35%" 8 "40%" 9 "45%" 10 "50%" 11 "55%" 12 "60%" 13 "65%" 14 "70%" 15 "75%" 16 "80%" 17 "85%" 18 "90%" 19 "95%" 20 "100%" ;
VAL_ 643 DCM_FR_FrontDoorAngleFeedback 0 "75°" 1 "35°" ;
VAL_ 643 DCM_FR_FRWindowLockSts 0 "LOCK" 1 "UNLOCK" ;
VAL_ 643 DCM_FR_DoorFRSts 0 "Closed" 1 "Opened" ;
VAL_ 651 DCM_FR_AmbientTemperatureValid 0 "Invalid" 1 "Valid" ;
VAL_ 651 DCM_FR_MirrorAutoTurnDownSts 0 "Disable" 1 "Enable" ;
VAL_ 651 DCM_FR_MirrorAutoFoldUnfoldSts 0 "Disable" 1 "Enable" ;
VAL_ 651 DCM_FR_RearmirrorHeatingSts 0 "OFF" 1 "ON" ;
VAL_ 651 DCM_FR_MirrorFold_UnfoldSts 0 "Unfold" 1 "Fold" ;
VAL_ 644 DCM_RL_DoorRLLockSts 0 "Locked" 1 "Unlocked" ;
VAL_ 644 DCM_RL_RLPESwitchReq 0 "Not pressed" 1 "Pressed" ;
VAL_ 644 DCM_RL_DoorObstacleSts 0 "Normal" 1 "Outer obstacle" ;
VAL_ 644 DCM_RL_DoorAntiPinchSts 0 "Normal" 1 "Anti pinch" ;
VAL_ 644 DCM_RL_ElectricDoorMovementSts 0 "FullyClosed" 1 "FullyOpened" 2 "Opening" 3 "Closing" 4 "Stoped" 5 "Revserved" 6 "Revserved" 7 "Revserved" ;
VAL_ 644 DCM_RL_LinkageAvoidanceReq 0 "NO Request" 1 "Close" 2 "Open" 3 "Stop" ;
VAL_ 644 DCM_RL_InsideSwitchReq 0 "Not pressed" 1 "Pressed" ;
VAL_ 644 DCM_RL_WindowSts 0 "stopped" 1 "Auto Up moving" 2 "Manual Up moving" 3 "Auto Down moving" 4 "Manual Down moving" 5 "Pinch Reversing" ;
VAL_ 644 DCM_RL_PWM_POS_STS 0 "Bottom stall" 1 "No stall" 2 "Top stall" 3 "Top soft stop" 4 "Bottom soft stop" ;
VAL_ 644 DCM_RL_GLASS_LOCATION 0 "0%" 1 "5%" 2 "10%" 3 "15%" 4 "20%" 5 "25%" 6 "30%" 7 "35%" 8 "40%" 9 "45%" 10 "50%" 11 "55%" 12 "60%" 13 "65%" 14 "70%" 15 "75%" 16 "80%" 17 "85%" 18 "90%" 19 "95%" 20 "100%" ;
VAL_ 644 DCM_RL_RearDoorAngleFeedback 0 "75°" 1 "35°" ;
VAL_ 644 DCM_RL_RLWindowLockSts 0 "LOCK" 1 "UNLOCK" ;
VAL_ 644 DCM_RL_DoorRLSts 0 "Closed" 1 "Opened" ;
VAL_ 645 DCM_RR_DoorRRLockSts 0 "Locked" 1 "Unlocked" ;
VAL_ 645 DCM_RR_RRPESwitchReq 0 "Not pressed" 1 "Pressed" ;
VAL_ 645 DCM_RR_DoorObstacleSts 0 "Normal" 1 "Outer obstacle" ;
VAL_ 645 DCM_RR_DoorAntiPinchSts 0 "Normal" 1 "Anti pinch" ;
VAL_ 645 DCM_RR_ElectricDoorMovementSts 0 "FullyClosed" 1 "FullyOpened" 2 "Opening" 3 "Closing" 4 "Stoped" 5 "Revserved" 6 "Revserved" 7 "Revserved" ;
VAL_ 645 DCM_RR_LinkageAvoidanceReq 0 "NO Request" 1 "Close" 2 "Open" 3 "Stop" ;
VAL_ 645 DCM_RR_InsideSwitchReq 0 "Not pressed" 1 "Pressed" ;
VAL_ 645 DCM_RR_WindowSts 0 "stopped" 1 "Auto Up moving" 2 "Manual Up moving" 3 "Auto Down moving" 4 "Manual Down moving" 5 "Pinch Reversing" ;
VAL_ 645 DCM_RR_PWM_POS_STS 0 "Bottom stall" 1 "No stall" 2 "Top stall" 3 "Top soft stop" 4 "Bottom soft stop" ;
VAL_ 645 DCM_RR_GLASS_LOCATION 0 "0%" 1 "5%" 2 "10%" 3 "15%" 4 "20%" 5 "25%" 6 "30%" 7 "35%" 8 "40%" 9 "45%" 10 "50%" 11 "55%" 12 "60%" 13 "65%" 14 "70%" 15 "75%" 16 "80%" 17 "85%" 18 "90%" 19 "95%" 20 "100%" ;
VAL_ 645 DCM_RR_RearDoorAngleFeedback 0 "75°" 1 "35°" ;
VAL_ 645 DCM_RR_RRWindowLockSts 0 "LOCK" 1 "UNLOCK" ;
VAL_ 645 DCM_RR_DoorRRSts 0 "Closed" 1 "Opened" ;
VAL_ 614 EVCOM_OverPwrDropFreqError 0 "No Error" 1 "Error" ;
VAL_ 614 EVCOM_OverCurDropFreqError 0 "No Error" 1 "Error" ;
VAL_ 614 EVCOM_CommunicationError 0 "No Error" 1 "Error" ;
VAL_ 614 EVCOM_StandByUnderVolError 0 "No Error" 1 "Error" ;
VAL_ 614 EVCOM_StandByOverVolError 0 "No Error" 1 "Error" ;
VAL_ 614 EVCOM_UnderVoltageError 0 "No Error" 1 "Error" ;
VAL_ 614 EVCOM_OverVoltageError 0 "No Error" 1 "Error" ;
VAL_ 614 EVCOM_OverCurrentError 0 "No Error" 1 "Error" ;
VAL_ 614 EVCOM_ActlOprtMode 0 "off" 1 "running" 2 "limit" 3 "pre_heat" 4 "fault" 5 "reserved" 6 "reserved" 7 "reserved" ;
VAL_ 615 EVCOM_OverLoad 0 "No Error" 1 "Error" ;
VAL_ 615 EVCOM_InpowerError 0 "No Error" 1 "Error" ;
VAL_ 615 EVCOM_LackPhase 0 "No Error" 1 "Error" ;
VAL_ 615 EVCOM_TemperSensorError 0 "No Error" 1 "Error" ;
VAL_ 615 EVCOM_CurrentOffsetError 0 "No Error" 1 "Error" ;
VAL_ 615 EVCOM_OverHeat 0 "No Error" 1 "IGBT overheat" 2 "MCU overheat" 3 "reserved" ;
VAL_ 615 EVCOM_StallFault 0 "No Fault" 1 "Fault" ;
VAL_ 179 MessageCounter_0B3 15 "Invalid" ;
VAL_ 179 IBS_EPBFailureLamp 0 "LampOFF" 1 "LampON" ;
VAL_ 179 IBS_BrakeLightRequest 0 "brakelightOFF" 1 "brakelightON" 2 "notused" 3 "signalnotavailable" ;
VAL_ 179 IBS_EPBworkingSts 0 "UNKNOWN" 1 "APPLIED" 2 "RELEASED" 3 "APPLY IN PROGRESS" 4 "RELEASE IN PROGRESS" 5 "COMPLETELY RELEASED" 6 "DYNAMIC APPLY" 7 "RESERVED" ;
VAL_ 179 IBS_TCSActive 0 "NotActive" 1 "Active" ;
VAL_ 179 IBS_VDCActive 0 "NotActive" 1 "Active" ;
VAL_ 179 IBS_HDCAvailable 0 "NOT_AVAILABLE" 1 "AVAILABLE" ;
VAL_ 179 IBS_AEBActive 0 "notactive" 1 "active" ;
VAL_ 179 IBS_HHCActive 0 "notactive" 1 "active" ;
VAL_ 179 IBS_HHCAvailable 0 "NOT_AVAILABLE" 1 "AVAILABLE" ;
VAL_ 179 IBS_AVHAvailable 0 "NOT_AVAILABLE" 1 "AVAILABLE" ;
VAL_ 179 IBS_HazWarnReq 0 "OFF" 1 "ON" 2 "Signalnotavailable" ;
VAL_ 179 IBS_EPBFunctionLamp 0 "LampOFF" 1 "LampON" 2 "flash" 3 "Invalid" ;
VAL_ 179 IBS_AEBAvailable 0 "NOT_AVAILABLE" 1 "AVAILABLE" ;
VAL_ 179 IBS_AWBActive 0 "NotActive" 1 "Active" ;
VAL_ 179 IBS_AWBAvailable 0 "NOT_AVAILABLE" 1 "AVAILABLE" ;
VAL_ 179 IBS_EPBControllerSts 0 "MasterMode" 1 "SlaveMode" ;
VAL_ 180 MessageCounter_0B4 15 "Invalid" ;
VAL_ 180 IBS_EPBTextdisplay 0 "Off" 1 "Park Brake Applied" 2 "Park Brake Released" 3 "Parking brake malfunction.Visit service center to fix the issue" 4 "Reserve" ;
VAL_ 180 IBS_SystemStatus 0 "Normal" 1 "Degrade" 2 "Partial" 3 "Inhibit" 4 "Reserved" 5 "Reserved" 6 "Reserved" 7 "Reserved" ;
VAL_ 180 IBS_VehicleSpeedValid 0 "Invalid" 1 "Valid" ;
VAL_ 180 IBS_ABSFault 0 "Noerror" 1 "Error" ;
VAL_ 180 IBS_EBDActive 0 "Not Active" 1 "Active" ;
VAL_ 180 IBS_EBDFault 0 "Noerror" 1 "Error" ;
VAL_ 180 IBS_VDCFault 0 "Noerror" 1 "Error" ;
VAL_ 180 IBS_TCSFault 0 "Noerror" 1 "Error" ;
VAL_ 180 IBS_ABSActive 0 "Not Active" 1 "Active" ;
VAL_ 180 IBS_ABPActive 0 "INACTIVE" 1 "ACTIVE" ;
VAL_ 180 IBS_ABPAvailable 0 "NOT_AVAILABLE" 1 "AVAILABLE" ;
VAL_ 180 IBS_DTCFault 0 "Noerror" 1 "Error" ;
VAL_ 180 IBS_VCU_DecelerationRequest_Avai 0 "Available" 1 "Not Available" 2 "Reserved" 3 "Reserved" ;
VAL_ 186 MessageCounter_0BA 15 "Invalid" ;
VAL_ 186 IBS_CDPActive 0 "Not Active" 1 "Active" ;
VAL_ 186 IBS_CDPAvailable 0 "NOT_AVAILABLE" 1 "AVAILABLE" ;
VAL_ 186 IBS_DTCActive 0 "Not Active" 1 "Active" ;
VAL_ 187 MessageCounter_0BB 15 "Invalid" ;
VAL_ 187 IBS_SUBEPBworkingSts 0 "UNKNOWN" 1 "APPLIED" 2 "RELEASED" 3 "APPLY IN PROGRESS" 4 "RELEASE IN PROGRESS" 5 "COMPLETELY RELEASED" 6 "DYNAMIC APPLY" 7 "RESERVED" ;
VAL_ 187 IBS_SUBEPBFailureStatus 0 "No error" 1 "error" 2 "Reserve" 3 "Reserve" ;
VAL_ 187 IBS_SUBEPBControllerSts 0 "MasterMode" 1 "SlaveMode" ;
VAL_ 152 MessageCounter_098 15 "Invalid" ;
VAL_ 152 MCU_ActualSpeedValid 0 "Invalid" 1 "Valid" ;
VAL_ 152 MCU_ActTrqValid 0 "Invalid" 1 "Valid" ;
VAL_ 152 MCU_UdcCurr 1022 "Abnormal" 1023 "Invalid" ;
VAL_ 243 MCU_VCUWorkMode 0 "Initialization;" 1 "Standby;" 2 "Ready;" 3 "Torque Control;" 4 "Fault" 5 "ActiveDischarge;" 6 "Afterrun;" 7 "Motor Active Hearting;" 8 "Speed Control" ;
VAL_ 243 MCU_BDmpCActv 0 "Damping Off" 1 "Damping On" ;
VAL_ 243 MCU_StGateDrv 0 "ShortCircuit" 1 "FreeWheel" 2 "PWMrun" 3 "Invalid" ;
VAL_ 594 MCU_StDischg 0 "Standby" 1 "Active" 2 "Finished" 3 "Failed" ;
VAL_ 594 MCU_UT15State 0 "No active" 1 "Active" ;
VAL_ 595 MessageCounter_253 15 "Invalid" ;
VAL_ 595 MCU_FaultLevel 0 "Normal" 1 "LV1 Minor fault" 2 "LV2 Limited power by a small margin" 3 "LV3 Greatly limited power" 4 "LV4 Stop the output(Fault enable recovery)" 5 "LV5 Stop the output(Fault disable recovery)" ;
VAL_ 914 MCU_IGBTTempU 254 "Abnormal" 255 "Invalid" ;
VAL_ 914 MCU_IGBTTempV 254 "Abnormal" 255 "Invalid" ;
VAL_ 914 MCU_IGBTTempW 254 "Abnormal" 255 "Invalid" ;
VAL_ 914 MCU_IGBTTempMax 254 "Abnormal" 255 "Invalid" ;
VAL_ 914 MCU_IGBTTempRiseU 254 "Abnormal" 255 "Invalid" ;
VAL_ 914 MCU_IGBTTempRiseV 254 "Abnormal" 255 "Invalid" ;
VAL_ 914 MCU_IGBTTempRiseW 254 "Abnormal" 255 "Invalid" ;
VAL_ 914 MCU_IGBTTempRiseMax 254 "Abnormal" 255 "Invalid" ;
VAL_ 915 MCU_TempCurrCool 254 "Abnormal" 255 "Invalid" ;
VAL_ 915 MCU_TempCurrStr1 254 "Abnormal" 255 "Invalid" ;
VAL_ 915 MCU_TempCurrStr2 254 "Abnormal" 255 "Invalid" ;
VAL_ 915 MCU_TempCurrStrMax 254 "Abnormal" 255 "Invalid" ;
VAL_ 915 MCU_TempRiseCurrStr 254 "Abnormal" 255 "Invalid" ;
VAL_ 915 MCU_TempStatus 0 "Normal Temperature" 1 "Heating alarm 1" 2 "Heating alarm 2" 3 "Over Heating" ;
VAL_ 578 POD_DCDC_WorkMode 0 "Init" 1 "Standby" 2 "Buck" 3 "Fault" 4 "sleep" ;
VAL_ 770 POD_DCDC_FaultLevel 0 "No Fault" 1 "Fault Level1" 2 "Fault Level2" 3 "Fault Level3" ;
VAL_ 770 POD_DCDC_OutputCurrentHighFault 0 "No Fault" 1 "Fault" ;
VAL_ 770 POD_DCDC_InputVoltHighFault 0 "No Fault" 1 "Fault" ;
VAL_ 770 POD_DCDC_InputVoltLowFault 0 "No Fault" 1 "Fault" ;
VAL_ 770 POD_DCDC_OutputVoltHighFault 0 "No Fault" 1 "Fault" ;
VAL_ 770 POD_DCDC_OutputVoltLowFault 0 "No Fault" 1 "Fault" ;
VAL_ 770 POD_DCDC_Outputopencircuiterror 0 "No Fault" 1 "Fault" ;
VAL_ 770 POD_DCDC_Side2Overtempfault 0 "No Fault" 1 "Fault" ;
VAL_ 770 POD_DCDC_OutCurSensorFault 0 "No Fault" 1 "Fault" ;
VAL_ 770 POD_DCDC_OutputTempSensorFault 0 "No Fault" 1 "Fault" ;
VAL_ 770 POD_DCDC_InternalFault 0 "No Fault" 1 "Fault" ;
VAL_ 770 POD_DCDC_HVinputshortcircuit 0 "No Fault" 1 "Fault" ;
VAL_ 770 POD_DCDC_LVoutputshortcircuit 0 "No Fault" 1 "Fault" ;
VAL_ 581 POD_OBC_CCStatus 0 "Unconnected" 1 "Half-connected" 2 "1500 Ohm" 3 "680 Ohm" 4 "220 Ohm" 5 "100 Ohm" 6 "2000 Ohm" 7 "2700 Ohm" 8 "1000 Ohm" 9 "470 Ohm" 10 "invalid" ;
VAL_ 581 POD_OBC_CPStatus 0 "Unconnected" 1 "9V" 2 "9V PWM" 3 "6V" 4 "6V PWM" 5 "Fault" 6 "Reserve" 7 "Reserve" ;
VAL_ 581 POD_OBC_WorkMode 0 "Init" 1 "Standby" 2 "Reserve" 3 "Charging Mode" 4 "Pre-heating Mode" 5 "V2L Mode" 6 "Sleep" 7 "Fault" ;
VAL_ 581 POD_OBC_EMLockState 0 "Close" 1 "Open" 2 "Error" ;
VAL_ 581 POD_OBC_ChargCapacibility 0 "single-phase" 1 "Three-phase" 2 "Error" ;
VAL_ 581 POD_OBC_S2State 0 "Close" 1 "Open" 2 "Error" ;
SIG_GROUP_ 249 IVI_03_SigGroup 1 : Checksum_0F9 MessageCounter_0F9 IVI_SFIDippedBeamSet IVI_SFIabnormalSts IVI_BulbCheckSts;
SIG_GROUP_ 1937 Uds_EPT_Boot_Response_SigGroup 1 : Uds_EPT_bootResponse_Byte0 Uds_EPT_bootResponse_Byte1 Uds_EPT_bootResponse_Byte2 Uds_EPT_bootResponse_Byte3 Uds_EPT_bootResponse_Byte4 Uds_EPT_bootResponse_Byte5 Uds_EPT_bootResponse_Byte6 Uds_EPT_bootResponse_Byte7;
SIG_GROUP_ 1809 Uds_EPT_Boot_Request_SigGroup 1 : UDS_EPT_BootCmd1 UDS_EPT_BootCmd2 UDS_EPT_BootCmd3;
SIG_GROUP_ 151 ACU_info_SigGroup 1 : Checksum_097 MessageCounter_097 ACU_CrashOutputSts ACU_CrashOutputStsValid ACU_DriverSeatBeltSts ACU_DriverSeatBeltStsValid ACU_PassengerSeatBeltSts ACU_PassengerSeatBeltStsValid ACU_PassengerSts ACU_SecondLeftSeatBeltSts ACU_RLSeatBeltStatusValid ACU_SecondLeftSts ACU_SecondRightSeatBeltSts ACU_RRSeatBeltStatusValid ACU_SecondRightSts ACU_PassengerAirbagSts ACU_DriverWarningLampSts ACU_PassengerWarningLampSts ACU_WarningLampSts;
SIG_GROUP_ 918 ADCU_temperature_SigGroup 1 : ADCU_TemperatureSts;
SIG_GROUP_ 613 APTC_TCU_SigGroup 1 : APTC_HVPowerUpReq APTC_HeatingFaltStatus APTC_DriveFaltStatus APTC_LostCommuFaltStatus APTC_IGBTFaltStatus APTC_Core1TempSensorFaltStatus APTC_LeftCoreTemp APTC_RightCoreTemp APTC_PowerConsumption APTC_HVBusVoltage APTC_OverCurrentFault APTC_LowVoltageStatus APTC_HighVoltageStatus APTC_OverLoadStatus APTC_IGBTTempSensorStatus APTC_PCBTempSensorStatus APTC_Core2TempSensorFaltStatus;
SIG_GROUP_ 822 BCM_01_SigGroup 1 : BCM_RLHSHumidSensorValue BCM_RLHSSolarDrvr BCM_RLHSSolarPass BCM_RLHSTempSensorValue BCM_RLHSTempDewPoint BCM_HUDBriUnit BCM_HUDBriRawVal;
SIG_GROUP_ 826 BCM_05_SigGroup 1 : Checksum_33A BCM_GearTimesSts BCM_ChrgFlapLockSts MessageCounter_33A BCM_KeyNotInCarRemind BCM_FLSeatBeltRemindReq BCM_FRSeatBeltRemindReq BCM_RLSeatBeltRemindReq BCM_RRSeatBeltRemindReq BCM_PuddleLiReq BCM_DomeLampBrightSts BCM_AutoCloseWinFunSts BCM_WiperServiceSts BCM_WiperWorkingSts BCM_FrontWiperModeSts BCM_DomeLampAutoSts BCM_WelLightshowOnOffSts;
SIG_GROUP_ 625 BCM_06_SigGroup 1 : checksum_271 MessageCounter_271 BCM_PepsPowerMode BCM_PowerOffDisplayReq;
SIG_GROUP_ 626 BCM_11_SigGroup 1 : BCM_Immo_State BCM_SecOCFV_272 BCM_SecOCMAC_272;
SIG_GROUP_ 820 BCM_Authentication_SigGroup 1 : BCM_AntiTheftSts BCM_AlarmedRemind BCM_ImmobilizingRemind BCM_SecOCFV_334 BCM_SecOCMAC_334;
SIG_GROUP_ 931 BMS_Batcode_SigGroup 1 : BMS_BatCodeFrameNO BMS_BatCodeFrameLength BMS_BatCode1 BMS_BatCode2 BMS_BatCode3 BMS_BatCode4 BMS_BatCode5 BMS_BatCode6;
SIG_GROUP_ 934 BMS_BatInfor_01_SigGroup 1 : BMS_BatType BMS_CellNumbers BMS_RatCapacity BMS_RatEnergy BMS_RatBatVoltage;
SIG_GROUP_ 935 BMS_BatInfor_02_SigGroup 1 : BMS_BatSupName;
SIG_GROUP_ 938 BMS_BatInfor_03_SigGroup 1 : BMS_RemainCapacity;
SIG_GROUP_ 993 BMS_Cellinfo_SigGroup 1 : BMS_Cellinfo;
SIG_GROUP_ 536 BMS_CellTemp_SigGroup 1 : BMS_ThermometerProbes BMS_AverageCellTemp BMS_MaxCellTemp BMS_MinCellTemp BMS_MaxCellTempModuleNO BMS_MinCellTempModuleNO BMS_MaxCellTempNO BMS_MinCellTempNO;
SIG_GROUP_ 535 BMS_CellVoltage_SigGroup 1 : BMS_MaxCellVoltage BMS_MinCellVoltage BMS_MaxCellVoltageModuleNO BMS_MinCellVoltageModlueNO BMS_MaxCellVoltageNO BMS_MinCellVoltageNO;
SIG_GROUP_ 530 BMS_Charge_01_SigGroup 1 : BMS_RemChagTime BMS_MaxChagVoltage BMS_AllowChagCurrent;
SIG_GROUP_ 531 BMS_Charge_02_SigGroup 1 : BMS_DCChgMode BMS_AbortAchiveSingleVolt BMS_AbortAchiveTotalVolt BMS_AbortFaultBMSTemp BMS_AbortFaultBatteryTemp BMS_AbortErrorCurrent BMS_AbortAchivesetValue BMS_AbortErrorVoltage BMS_ChagComplete BMS_ChargeRequest;
SIG_GROUP_ 936 BMS_Charge_03_SigGroup 1 : BMS_SingChgkwh BMS_SumChgkwh BMS_BatChagSum;
SIG_GROUP_ 937 BMS_Charge_04_SigGroup 1 : BMS_SumDisChgkwh;
SIG_GROUP_ 528 BMS_DIRelayState_SigGroup 1 : BMS_PosRelayStatus BMS_PTCRelayStatus BMS_NegRelayStatus BMS_PreRelayStatus BMS_PTC_VoltageValue BMS_PTC_WorkStatus BMS_PTC_WorkTime;
SIG_GROUP_ 772 BMS_ErrorInfo_SigGroup 1 : BMS_ErrorCellOverVolt BMS_ErrorCellUnderVolt BMS_ErrorCellHighTemp BMS_ErrorCellLowTemp BMS_ErrorBattOverVolt BMS_ErrorBattUnderVolt BMS_ErrorChaCurrentOver BMS_ErrorDisChaCurrentOver BMS_ErrorBSUOffline BMS_ErrorLeakCurrent BMS_ErrorCellVoltDiff BMS_ErrorCellTempDiff BMS_ErrorBatVolt BMS_ErrorHallOffline BMS_ErrorCellVoltOffline BMS_ErrorCellTempOffline BMS_ErrorPreChaFailed BMS_ErrorRelay BMS_ErrorBSUBalance BMS_ErrorLowSoc BMS_ErrorHighSoc BMS_ErrorSoCJump_RM BMS_ErrorHVIL BMS_ErrorEmergencyOffCrash BMS_ErrorSystemsMatch BMS_ErrorSmoke BMS_ErrorLeakDet BMS_ThermalRunawayFault BMS_DTC;
SIG_GROUP_ 933 BMS_PRO_SigGroup 1 : BMS_BatProDatYear BMS_BatProDatMonth BMS_BatProDatDay;
SIG_GROUP_ 992 BMS_SGW_01_SigGroup 1 : BMS_FeedEnergySts BMS_DirveDiscSts;
SIG_GROUP_ 193 BMS_status_01_SigGroup 1 : Checksum_0C1 BMS_ErrorIsolationSingleLow MessageCounter_0C1 BMS_WorkMode BMS_BalancingStatus BMS_InsulationDetectionStatus BMS_HVinterlockState BMS_ThrmlRunawayFault BMS_PreCharge BMS_ChargeStatus BMS_RunHeatStatus BMS_ErrorLevel BMS_SOH BMS_SysRegInsulationValue;
SIG_GROUP_ 194 BMS_status_02_SigGroup 1 : BMS_BattVolt BMS_BattCurr BMS_Heatcurrent;
SIG_GROUP_ 532 BMS_status_03_SigGroup 1 : BMS_PackVoltage BMS_LinkVoltage BMS_SOC BMS_DisplaySOC;
SIG_GROUP_ 533 BMS_status_04_SigGroup 1 : BMS_FeedbackCurr BMS_DisChgCurr;
SIG_GROUP_ 771 BMS_TCU_SigGroup 1 : BMS_CoolCommand BMS_AllowCellTemperature BMS_TargetBatteryMaxCellTemp BMS_TempInlet BMS_HeatCommand BMS_KeepWarmRequest BMS_KeepWarmStatus BMS_RTC_Request BMS_BalanceCommand BMS_Tempoutlet BMS_FlowRate;
SIG_GROUP_ 932 BMS_VersionInfor_SigGroup 1 : BMS_SoftVsesion BMS_HardVsesion BMS_ComVersion BMS_BatProRights BMS_Life;
SIG_GROUP_ 632 CGW_01_SigGroup 1 : Checksum_278 MessageCounter_278 CGW_VehicleState;
SIG_GROUP_ 642 DCM_FL_SigGroup 1 : DCM_FL_DoorFLLockSts DCM_FL_DoorFLAngle DCM_FL_FLPESwitchReq DCM_FL_DoorObstacleSts DCM_FL_DoorAntiPinchSts DCM_FL_ElectricDoorMovementSts DCM_FL_LinkageAvoidanceReq DCM_FL_InsideSwitchReq DCM_FL_WindowSts DCM_FL_PWM_POS_STS DCM_FL_GLASS_LOCATION DCM_FL_FrontDoorAngleFeedback;
SIG_GROUP_ 650 DCM_FL_02_SigGroup 1 : Checksum_28A MessageCounter_28A DCM_FL_DoorFLSts DCM_FL_FRWndSwA DCM_FL_RLWndSwA DCM_FL_RRWndSwA DCM_FL_LeftMirrorHorizontalPos DCM_FL_LeftMirrorVerticalPos DCM_FL_MirrorAutoTurnDownSts DCM_FL_MirrorAutoFoldUnfoldSts DCM_FL_RearmirrorHeatingSts DCM_FL_MirrorFold_UnfoldSts;
SIG_GROUP_ 643 DCM_FR_SigGroup 1 : DCM_FR_DoorFRLockSts DCM_FR_DoorFRAngle DCM_FR_FRPESwitchReq DCM_FR_DoorAntiPinchSts DCM_FR_DoorObstacleSts DCM_FR_ElectricDoorMovementSts DCM_FR_LinkageAvoidanceReq DCM_FR_InsideSwitchReq DCM_FR_WindowSts DCM_FR_PWM_POS_STS DCM_FR_GLASS_LOCATION DCM_FR_FrontDoorAngleFeedback DCM_FR_FRWindowLockSts DCM_FR_DoorFRSts;
SIG_GROUP_ 651 DCM_FR_02_SigGroup 1 : DCM_FR_AmbientTemperatureValid DCM_FR_AmbientTemperature DCM_FR_RightMirrorHorizontalPos DCM_FR_RightMirrorVerticalPos DCM_FR_MirrorAutoTurnDownSts DCM_FR_MirrorAutoFoldUnfoldSts DCM_FR_RearmirrorHeatingSts DCM_FR_MirrorFold_UnfoldSts;
SIG_GROUP_ 644 DCM_RL_SigGroup 1 : DCM_RL_DoorRLLockSts DCM_RL_DoorRLAngle DCM_RL_RLPESwitchReq DCM_RL_DoorObstacleSts DCM_RL_DoorAntiPinchSts DCM_RL_ElectricDoorMovementSts DCM_RL_LinkageAvoidanceReq DCM_RL_InsideSwitchReq DCM_RL_WindowSts DCM_RL_PWM_POS_STS DCM_RL_GLASS_LOCATION DCM_RL_RearDoorAngleFeedback DCM_RL_RLWindowLockSts DCM_RL_DoorRLSts;
SIG_GROUP_ 645 DCM_RR_SigGroup 1 : DCM_RR_DoorRRLockSts DCM_RR_DoorRRAngle DCM_RR_RRPESwitchReq DCM_RR_DoorObstacleSts DCM_RR_DoorAntiPinchSts DCM_RR_ElectricDoorMovementSts DCM_RR_LinkageAvoidanceReq DCM_RR_InsideSwitchReq DCM_RR_WindowSts DCM_RR_PWM_POS_STS DCM_RR_GLASS_LOCATION DCM_RR_RearDoorAngleFeedback DCM_RR_RRWindowLockSts DCM_RR_DoorRRSts;
SIG_GROUP_ 614 EVCOM_State_01_SigGroup 1 : EVCOM_OverPwrDropFreqError EVCOM_OverCurDropFreqError EVCOM_CommunicationError EVCOM_StandByUnderVolError EVCOM_StandByOverVolError EVCOM_UnderVoltageError EVCOM_OverVoltageError EVCOM_OverCurrentError EVCOM_CompDeviceInternTemp EVCOM_CompActlSpd EVCOM_CompActlPwrCnsmp EVCOM_CompActlCnsmpCur EVCOM_ActlOprtMode;
SIG_GROUP_ 615 EVCOM_State_02_SigGroup 1 : EVCOM_OverLoad EVCOM_InpowerError EVCOM_LackPhase EVCOM_TemperSensorError EVCOM_CurrentOffsetError EVCOM_OverHeat EVCOM_CompBusVolt EVCOM_CompActlCnsmpPhaseCur EVCOM_StallFault;
SIG_GROUP_ 179 IBS_Status_02_SigGroup 1 : Checksum_0B3 MessageCounter_0B3 IBS_EPBFailureLamp IBS_BrakeLightRequest IBS_EPBworkingSts IBS_TCSActive IBS_VDCActive IBS_HDCAvailable IBS_AEBActive IBS_HHCActive IBS_HHCAvailable IBS_AVHAvailable IBS_HazWarnReq IBS_AWBActive IBS_EPBFunctionLamp IBS_AEBAvailable IBS_AWBAvailable IBS_EPBControllerSts;
SIG_GROUP_ 180 IBS_Status_03_SigGroup 1 : Checksum_0B4 IBS_EPBTextdisplay MessageCounter_0B4 IBS_VehicleSpeed IBS_SystemStatus IBS_VehicleSpeedValid IBS_ABSFault IBS_EBDActive IBS_EBDFault IBS_VDCFault IBS_TCSFault IBS_ABSActive IBS_ABPActive IBS_ABPAvailable IBS_DTCFault IBS_VCU_DecelerationRequest_Avai;
SIG_GROUP_ 186 IBS_Status_04_SigGroup 1 : Checksum_0BA MessageCounter_0BA IBS_CDPActive IBS_CDPAvailable IBS_DTCActive;
SIG_GROUP_ 187 IBS_Status_05_SigGroup 1 : Checksum_0BB MessageCounter_0BB IBS_SUBEPBFailureStatus IBS_SUBEPBworkingSts IBS_SUBEPBControllerSts;
SIG_GROUP_ 152 MCU_01_SigGroup 1 : Checksum_098 MCU_ActualSpeedValid MCU_ActTrqValid MessageCounter_098 MCU_ActualTorque MCU_UdcCurr MCU_IsCurr MCU_ActualSpeed;
SIG_GROUP_ 243 MCU_02_SigGroup 1 : MCU_OfsAl MCU_Isd MCU_Isq MCU_DmpCTrqCurr MCU_VCUWorkMode MCU_BDmpCActv MCU_StGateDrv;
SIG_GROUP_ 594 MCU_DeratingStatus_SigGroup 1 : MCU_TrqAbsMax MCU_TrqAbsMin MCU_StDischg MCU_UT30Curr MCU_UT15State MCU_ActUnfilteredRotSpd MCU_SpdMaxLimit;
SIG_GROUP_ 595 MCU_FailureCode_SigGroup 1 : Checksum_253 MessageCounter_253 MCU_FaultLevel;
SIG_GROUP_ 929 MCU_HardwareNumber_SigGroup 1 : MCU_HwVer;
SIG_GROUP_ 928 MCU_SoftwareNumber_SigGroup 1 : MCU_CodeVer MCU_DataVer MCU_CpldVer MCU_HvMcuVer;
SIG_GROUP_ 914 MCU_Temperature_01_SigGroup 1 : MCU_IGBTTempU MCU_IGBTTempV MCU_IGBTTempW MCU_IGBTTempMax MCU_IGBTTempRiseU MCU_IGBTTempRiseV MCU_IGBTTempRiseW MCU_IGBTTempRiseMax;
SIG_GROUP_ 915 MCU_Temperature_02_SigGroup 1 : MCU_TempCurrCool MCU_TempCurrStr1 MCU_TempCurrStr2 MCU_TempCurrStrMax MCU_TempRiseCurrStr MCU_TempStatus;
SIG_GROUP_ 578 POD_DCDC_01_SigGroup 1 : POD_DCDC_HVInputVoltage POD_DCDC_WorkMode POD_DCDC_LVOutputCurrent POD_DCDC_HVInputCurrent POD_DCDC_LVOutputVoltage;
SIG_GROUP_ 770 POD_DCDC_02_SigGroup 1 : POD_DCDC_FaultLevel POD_DCDC_OutputCurrentHighFault POD_DCDC_InputVoltHighFault POD_DCDC_InputVoltLowFault POD_DCDC_OutputVoltHighFault POD_DCDC_OutputVoltLowFault POD_DCDC_Outputopencircuiterror POD_DCDC_Side2Overtempfault POD_DCDC_OutCurSensorFault POD_DCDC_OutputTempSensorFault POD_DCDC_InternalFault POD_DCDC_SecondarySideTemp POD_DCDC_Maxoutputpower POD_DCDC_HVinputshortcircuit POD_DCDC_LVoutputshortcircuit;
SIG_GROUP_ 581 POD_OBC_CHRGSTATION_SigGroup 1 : POD_OBC_CPCurrentLimit POD_OBC_CCStatus POD_OBC_CPStatus POD_OBC_CCCurrentLimit POD_OBC_CPFrequency POD_OBC_WorkMode POD_OBC_CPDuty POD_OBC_EMLockState POD_OBC_ChargCapacibility POD_OBC_S2State POD_OBC_OBCMaxPermOutpCrrt;
